VERSION "HNNBNNNYNNNNNNNNNNNNNNNNNNNNNNNNNNNNNNNNNN/4/%%%/4/'%**4NNN///"

NS_ :

BS_:

BU_: Frontradar Frontsensorik

BO_ 1801 ISO_Funktionaler_Req_09: 8 Vector__XXX
 SG_ ISO_09_Req_Data : 0|64@1+ (1,0) [0|1.84467440737096E+019] "" Vector__XXX

BO_ 1795 ISO_Funktionaler_Req_Abgas: 8 Vector__XXX
 SG_ ISO_Funktionaler_Req_Abgas : 0|64@1+ (1,0) [0|1.84467440737096E+019] "" Vector__XXX

BO_ 1792 ISO_Funktionaler_Req_All: 8 Vector__XXX
 SG_ ISO_ALL_01_Req_Data : 0|64@1+ (1,0) [0|1.84467440737096E+019] ""  Frontradar,Frontsensorik

BO_ 2015 ISO_Funktionaler_Req_OBD: 8 Vector__XXX
 SG_ ISO_OBD_Funktionaler_Req_Data : 0|64@1+ (1,0) [0|1.84467440737096E+019] "" Vector__XXX

BO_ 1871 ISO_Kamera_Req: 8 Vector__XXX
 SG_ ISO_Kamera_Req_Data : 0|64@1+ (1,0) [0|1.84467440737096E+019] ""  Frontsensorik

BO_ 1977 ISO_Kamera_Resp: 8 Frontsensorik
 SG_ ISO_Kamera_Resp_Data : 0|64@1+ (1,0) [0|1.84467440737096E+019] "" Vector__XXX

BO_ 1876 ISO_LWRAFS_Req: 8 Vector__XXX
 SG_ ISO_LWRAFS_Req_Data : 0|64@1+ (1,0) [0|1.84467440737096E+019] "" Vector__XXX

BO_ 1982 ISO_LWRAFS_Resp: 8 Vector__XXX
 SG_ ISO_LWRAFS_Resp_Data : 0|64@1+ (1,0) [0|1.84467440737096E+019] "" Vector__XXX

BO_ 1870 ISO_SWA_Req: 8 Vector__XXX
 SG_ ISO_SWA_Req_Data : 0|64@1+ (1,0) [0|1.84467440737096E+019] "" Vector__XXX

BO_ 1976 ISO_SWA_Resp: 8 Vector__XXX
 SG_ ISO_SWA_Resp_Data : 0|64@1+ (1,0) [0|1.84467440737096E+019] "" Vector__XXX

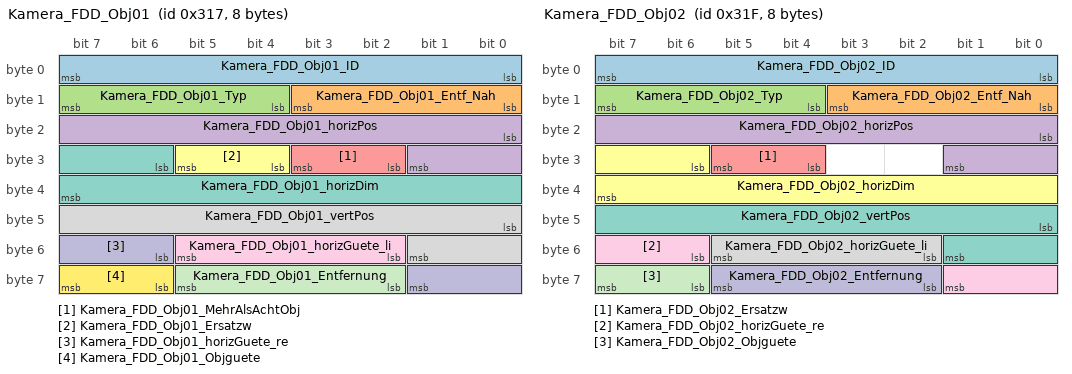
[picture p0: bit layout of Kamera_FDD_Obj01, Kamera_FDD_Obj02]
BO_ 791 Kamera_FDD_Obj01: 8 Frontsensorik
 SG_ Kamera_FDD_Obj01_ID : 0|8@1+ (1,0) [0|253] "" Vector__XXX
 SG_ Kamera_FDD_Obj01_Entf_Nah : 8|4@1+ (1,0) [0|15] "" Vector__XXX
 SG_ Kamera_FDD_Obj01_Typ : 12|4@1+ (1,0) [0|15] "" Vector__XXX
 SG_ Kamera_FDD_Obj01_horizPos : 16|10@1+ (0.05,-25.5) [-25.5|25.5] "Unit_DegreOfArc" Vector__XXX
 SG_ Kamera_FDD_Obj01_MehrAlsAchtObj : 26|2@1+ (1,0) [0|3] "" Vector__XXX
 SG_ Kamera_FDD_Obj01_Ersatzw : 28|2@1+ (1,0) [0|3] "" Vector__XXX
 SG_ Kamera_FDD_Obj01_horizDim : 30|10@1+ (0.05,0) [0|49.9] "Unit_DegreOfArc" Vector__XXX
 SG_ Kamera_FDD_Obj01_vertPos : 40|10@1+ (0.05,-12.75) [-12.75|12.75] "Unit_DegreOfArc" Vector__XXX
 SG_ Kamera_FDD_Obj01_horizGuete_li : 50|4@1+ (0.25,0) [0|3.75] "Unit_DegreOfArc" Vector__XXX
 SG_ Kamera_FDD_Obj01_horizGuete_re : 54|4@1+ (0.25,0) [0|3.75] "Unit_DegreOfArc" Vector__XXX
 SG_ Kamera_FDD_Obj01_Entfernung : 58|4@1+ (1,0) [0|15] "" Vector__XXX
 SG_ Kamera_FDD_Obj01_Objguete : 62|2@1+ (1,0) [0|3] "" Vector__XXX

BO_ 799 Kamera_FDD_Obj02: 8 Frontsensorik
 SG_ Kamera_FDD_Obj02_ID : 0|8@1+ (1,0) [0|253] "" Vector__XXX
 SG_ Kamera_FDD_Obj02_Entf_Nah : 8|4@1+ (1,0) [0|15] "" Vector__XXX
 SG_ Kamera_FDD_Obj02_Typ : 12|4@1+ (1,0) [0|15] "" Vector__XXX
 SG_ Kamera_FDD_Obj02_horizPos : 16|10@1+ (0.05,-25.5) [-25.5|25.5] "Unit_DegreOfArc" Vector__XXX
 SG_ Kamera_FDD_Obj02_Ersatzw : 28|2@1+ (1,0) [0|3] "" Vector__XXX
 SG_ Kamera_FDD_Obj02_horizDim : 30|10@1+ (0.05,0) [0|49.9] "Unit_DegreOfArc" Vector__XXX
 SG_ Kamera_FDD_Obj02_vertPos : 40|10@1+ (0.05,-12.75) [-12.75|12.75] "Unit_DegreOfArc" Vector__XXX
 SG_ Kamera_FDD_Obj02_horizGuete_li : 50|4@1+ (0.25,0) [0|3.75] "Unit_DegreOfArc" Vector__XXX
 SG_ Kamera_FDD_Obj02_horizGuete_re : 54|4@1+ (0.25,0) [0|3.75] "Unit_DegreOfArc" Vector__XXX
 SG_ Kamera_FDD_Obj02_Entfernung : 58|4@1+ (1,0) [0|15] "" Vector__XXX
 SG_ Kamera_FDD_Obj02_Objguete : 62|2@1+ (1,0) [0|3] "" Vector__XXX

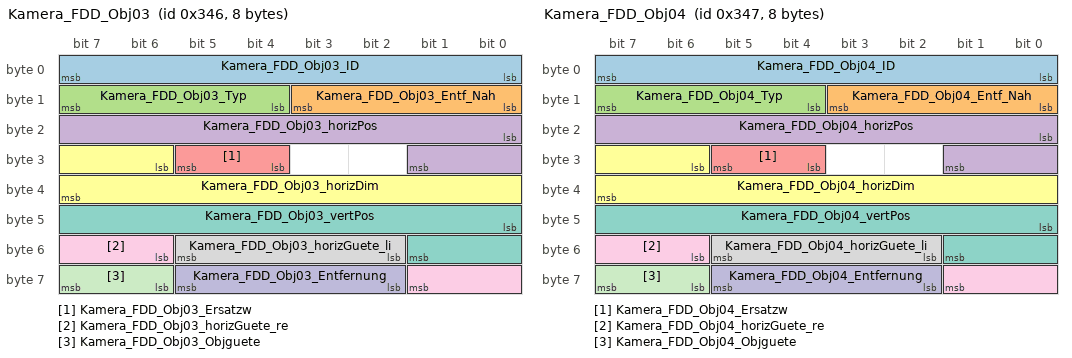
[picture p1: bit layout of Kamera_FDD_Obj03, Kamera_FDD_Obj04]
BO_ 838 Kamera_FDD_Obj03: 8 Frontsensorik
 SG_ Kamera_FDD_Obj03_ID : 0|8@1+ (1,0) [0|253] "" Vector__XXX
 SG_ Kamera_FDD_Obj03_Entf_Nah : 8|4@1+ (1,0) [0|15] "" Vector__XXX
 SG_ Kamera_FDD_Obj03_Typ : 12|4@1+ (1,0) [0|15] "" Vector__XXX
 SG_ Kamera_FDD_Obj03_horizPos : 16|10@1+ (0.05,-25.5) [-25.5|25.5] "Unit_DegreOfArc" Vector__XXX
 SG_ Kamera_FDD_Obj03_Ersatzw : 28|2@1+ (1,0) [0|3] "" Vector__XXX
 SG_ Kamera_FDD_Obj03_horizDim : 30|10@1+ (0.05,0) [0|49.9] "Unit_DegreOfArc" Vector__XXX
 SG_ Kamera_FDD_Obj03_vertPos : 40|10@1+ (0.05,-12.75) [-12.75|12.75] "Unit_DegreOfArc" Vector__XXX
 SG_ Kamera_FDD_Obj03_horizGuete_li : 50|4@1+ (0.25,0) [0|3.75] "Unit_DegreOfArc" Vector__XXX
 SG_ Kamera_FDD_Obj03_horizGuete_re : 54|4@1+ (0.25,0) [0|3.75] "Unit_DegreOfArc" Vector__XXX
 SG_ Kamera_FDD_Obj03_Entfernung : 58|4@1+ (1,0) [0|15] "" Vector__XXX
 SG_ Kamera_FDD_Obj03_Objguete : 62|2@1+ (1,0) [0|3] "" Vector__XXX

BO_ 839 Kamera_FDD_Obj04: 8 Frontsensorik
 SG_ Kamera_FDD_Obj04_ID : 0|8@1+ (1,0) [0|253] "" Vector__XXX
 SG_ Kamera_FDD_Obj04_Entf_Nah : 8|4@1+ (1,0) [0|15] "" Vector__XXX
 SG_ Kamera_FDD_Obj04_Typ : 12|4@1+ (1,0) [0|15] "" Vector__XXX
 SG_ Kamera_FDD_Obj04_horizPos : 16|10@1+ (0.05,-25.5) [-25.5|25.5] "Unit_DegreOfArc" Vector__XXX
 SG_ Kamera_FDD_Obj04_Ersatzw : 28|2@1+ (1,0) [0|3] "" Vector__XXX
 SG_ Kamera_FDD_Obj04_horizDim : 30|10@1+ (0.05,0) [0|49.9] "Unit_DegreOfArc" Vector__XXX
 SG_ Kamera_FDD_Obj04_vertPos : 40|10@1+ (0.05,-12.75) [-12.75|12.75] "Unit_DegreOfArc" Vector__XXX
 SG_ Kamera_FDD_Obj04_horizGuete_li : 50|4@1+ (0.25,0) [0|3.75] "Unit_DegreOfArc" Vector__XXX
 SG_ Kamera_FDD_Obj04_horizGuete_re : 54|4@1+ (0.25,0) [0|3.75] "Unit_DegreOfArc" Vector__XXX
 SG_ Kamera_FDD_Obj04_Entfernung : 58|4@1+ (1,0) [0|15] "" Vector__XXX
 SG_ Kamera_FDD_Obj04_Objguete : 62|2@1+ (1,0) [0|3] "" Vector__XXX

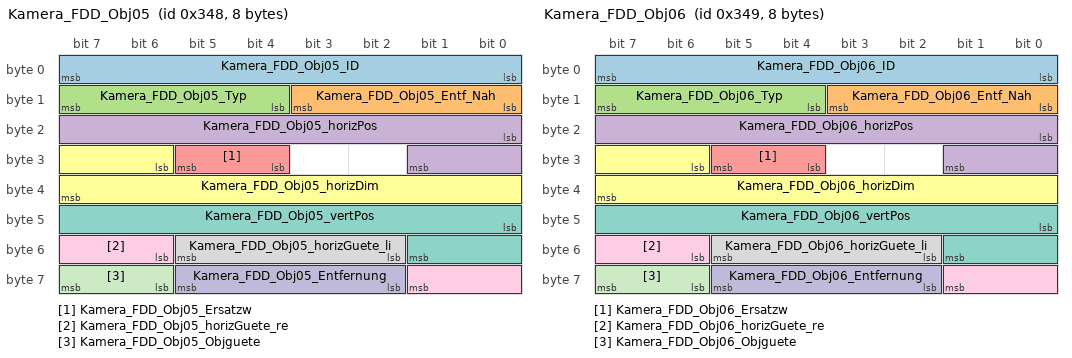
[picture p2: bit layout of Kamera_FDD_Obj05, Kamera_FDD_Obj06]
BO_ 840 Kamera_FDD_Obj05: 8 Frontsensorik
 SG_ Kamera_FDD_Obj05_ID : 0|8@1+ (1,0) [0|253] "" Vector__XXX
 SG_ Kamera_FDD_Obj05_Entf_Nah : 8|4@1+ (1,0) [0|15] "" Vector__XXX
 SG_ Kamera_FDD_Obj05_Typ : 12|4@1+ (1,0) [0|15] "" Vector__XXX
 SG_ Kamera_FDD_Obj05_horizPos : 16|10@1+ (0.05,-25.5) [-25.5|25.5] "Unit_DegreOfArc" Vector__XXX
 SG_ Kamera_FDD_Obj05_Ersatzw : 28|2@1+ (1,0) [0|3] "" Vector__XXX
 SG_ Kamera_FDD_Obj05_horizDim : 30|10@1+ (0.05,0) [0|49.9] "Unit_DegreOfArc" Vector__XXX
 SG_ Kamera_FDD_Obj05_vertPos : 40|10@1+ (0.05,-12.75) [-12.75|12.75] "Unit_DegreOfArc" Vector__XXX
 SG_ Kamera_FDD_Obj05_horizGuete_li : 50|4@1+ (0.25,0) [0|3.75] "Unit_DegreOfArc" Vector__XXX
 SG_ Kamera_FDD_Obj05_horizGuete_re : 54|4@1+ (0.25,0) [0|3.75] "Unit_DegreOfArc" Vector__XXX
 SG_ Kamera_FDD_Obj05_Entfernung : 58|4@1+ (1,0) [0|15] "" Vector__XXX
 SG_ Kamera_FDD_Obj05_Objguete : 62|2@1+ (1,0) [0|3] "" Vector__XXX

BO_ 841 Kamera_FDD_Obj06: 8 Frontsensorik
 SG_ Kamera_FDD_Obj06_ID : 0|8@1+ (1,0) [0|253] "" Vector__XXX
 SG_ Kamera_FDD_Obj06_Entf_Nah : 8|4@1+ (1,0) [0|15] "" Vector__XXX
 SG_ Kamera_FDD_Obj06_Typ : 12|4@1+ (1,0) [0|15] "" Vector__XXX
 SG_ Kamera_FDD_Obj06_horizPos : 16|10@1+ (0.05,-25.5) [-25.5|25.5] "Unit_DegreOfArc" Vector__XXX
 SG_ Kamera_FDD_Obj06_Ersatzw : 28|2@1+ (1,0) [0|3] "" Vector__XXX
 SG_ Kamera_FDD_Obj06_horizDim : 30|10@1+ (0.05,0) [0|49.9] "Unit_DegreOfArc" Vector__XXX
 SG_ Kamera_FDD_Obj06_vertPos : 40|10@1+ (0.05,-12.75) [-12.75|12.75] "Unit_DegreOfArc" Vector__XXX
 SG_ Kamera_FDD_Obj06_horizGuete_li : 50|4@1+ (0.25,0) [0|3.75] "Unit_DegreOfArc" Vector__XXX
 SG_ Kamera_FDD_Obj06_horizGuete_re : 54|4@1+ (0.25,0) [0|3.75] "Unit_DegreOfArc" Vector__XXX
 SG_ Kamera_FDD_Obj06_Entfernung : 58|4@1+ (1,0) [0|15] "" Vector__XXX
 SG_ Kamera_FDD_Obj06_Objguete : 62|2@1+ (1,0) [0|3] "" Vector__XXX

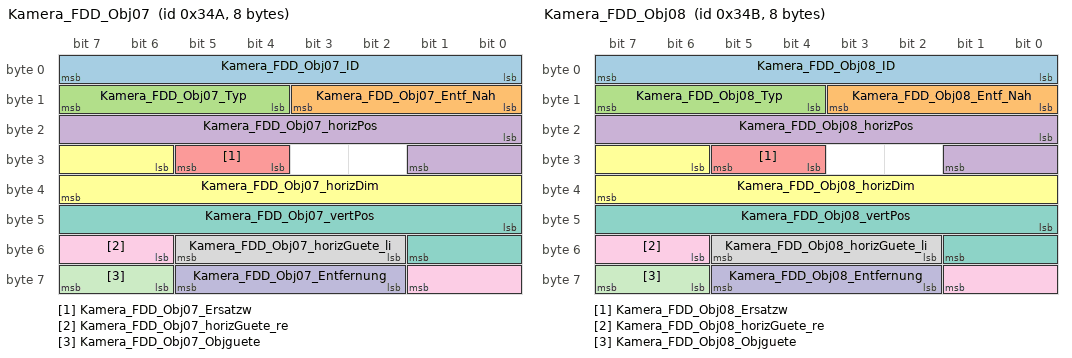
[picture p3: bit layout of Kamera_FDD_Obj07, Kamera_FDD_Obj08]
BO_ 842 Kamera_FDD_Obj07: 8 Frontsensorik
 SG_ Kamera_FDD_Obj07_ID : 0|8@1+ (1,0) [0|253] "" Vector__XXX
 SG_ Kamera_FDD_Obj07_Entf_Nah : 8|4@1+ (1,0) [0|15] "" Vector__XXX
 SG_ Kamera_FDD_Obj07_Typ : 12|4@1+ (1,0) [0|15] "" Vector__XXX
 SG_ Kamera_FDD_Obj07_horizPos : 16|10@1+ (0.05,-25.5) [-25.5|25.5] "Unit_DegreOfArc" Vector__XXX
 SG_ Kamera_FDD_Obj07_Ersatzw : 28|2@1+ (1,0) [0|3] "" Vector__XXX
 SG_ Kamera_FDD_Obj07_horizDim : 30|10@1+ (0.05,0) [0|49.9] "Unit_DegreOfArc" Vector__XXX
 SG_ Kamera_FDD_Obj07_vertPos : 40|10@1+ (0.05,-12.75) [-12.75|12.75] "Unit_DegreOfArc" Vector__XXX
 SG_ Kamera_FDD_Obj07_horizGuete_li : 50|4@1+ (0.25,0) [0|3.75] "Unit_DegreOfArc" Vector__XXX
 SG_ Kamera_FDD_Obj07_horizGuete_re : 54|4@1+ (0.25,0) [0|3.75] "Unit_DegreOfArc" Vector__XXX
 SG_ Kamera_FDD_Obj07_Entfernung : 58|4@1+ (1,0) [0|15] "" Vector__XXX
 SG_ Kamera_FDD_Obj07_Objguete : 62|2@1+ (1,0) [0|3] "" Vector__XXX

BO_ 843 Kamera_FDD_Obj08: 8 Frontsensorik
 SG_ Kamera_FDD_Obj08_ID : 0|8@1+ (1,0) [0|253] "" Vector__XXX
 SG_ Kamera_FDD_Obj08_Entf_Nah : 8|4@1+ (1,0) [0|15] "" Vector__XXX
 SG_ Kamera_FDD_Obj08_Typ : 12|4@1+ (1,0) [0|15] "" Vector__XXX
 SG_ Kamera_FDD_Obj08_horizPos : 16|10@1+ (0.05,-25.5) [-25.5|25.5] "Unit_DegreOfArc" Vector__XXX
 SG_ Kamera_FDD_Obj08_Ersatzw : 28|2@1+ (1,0) [0|3] "" Vector__XXX
 SG_ Kamera_FDD_Obj08_horizDim : 30|10@1+ (0.05,0) [0|49.9] "Unit_DegreOfArc" Vector__XXX
 SG_ Kamera_FDD_Obj08_vertPos : 40|10@1+ (0.05,-12.75) [-12.75|12.75] "Unit_DegreOfArc" Vector__XXX
 SG_ Kamera_FDD_Obj08_horizGuete_li : 50|4@1+ (0.25,0) [0|3.75] "Unit_DegreOfArc" Vector__XXX
 SG_ Kamera_FDD_Obj08_horizGuete_re : 54|4@1+ (0.25,0) [0|3.75] "Unit_DegreOfArc" Vector__XXX
 SG_ Kamera_FDD_Obj08_Entfernung : 58|4@1+ (1,0) [0|15] "" Vector__XXX
 SG_ Kamera_FDD_Obj08_Objguete : 62|2@1+ (1,0) [0|3] "" Vector__XXX

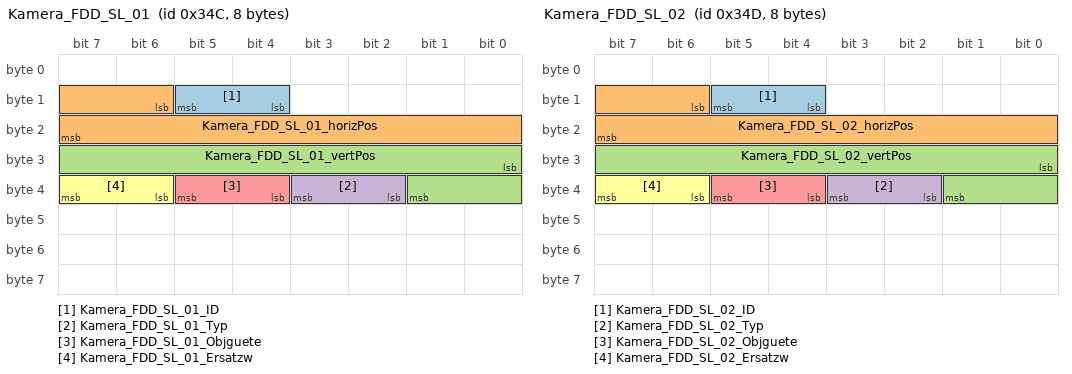
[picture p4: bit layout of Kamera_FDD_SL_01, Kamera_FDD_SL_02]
BO_ 844 Kamera_FDD_SL_01: 8 Frontsensorik
 SG_ Kamera_FDD_SL_01_ID : 12|2@1+ (1,0) [0|3] "" Vector__XXX
 SG_ Kamera_FDD_SL_01_horizPos : 14|10@1+ (0.05,-25.5) [-25.5|25.5] "Unit_DegreOfArc" Vector__XXX
 SG_ Kamera_FDD_SL_01_vertPos : 24|10@1+ (0.05,-12.75) [-12.75|12.75] "Unit_DegreOfArc" Vector__XXX
 SG_ Kamera_FDD_SL_01_Typ : 34|2@1+ (1,0) [0|3] "" Vector__XXX
 SG_ Kamera_FDD_SL_01_Objguete : 36|2@1+ (1,0) [0|3] "" Vector__XXX
 SG_ Kamera_FDD_SL_01_Ersatzw : 38|2@1+ (1,0) [0|3] "" Vector__XXX

BO_ 845 Kamera_FDD_SL_02: 8 Frontsensorik
 SG_ Kamera_FDD_SL_02_ID : 12|2@1+ (1,0) [0|3] "" Vector__XXX
 SG_ Kamera_FDD_SL_02_horizPos : 14|10@1+ (0.05,-25.5) [-25.5|25.5] "Unit_DegreOfArc" Vector__XXX
 SG_ Kamera_FDD_SL_02_vertPos : 24|10@1+ (0.05,-12.75) [-12.75|12.75] "Unit_DegreOfArc" Vector__XXX
 SG_ Kamera_FDD_SL_02_Typ : 34|2@1+ (1,0) [0|3] "" Vector__XXX
 SG_ Kamera_FDD_SL_02_Objguete : 36|2@1+ (1,0) [0|3] "" Vector__XXX
 SG_ Kamera_FDD_SL_02_Ersatzw : 38|2@1+ (1,0) [0|3] "" Vector__XXX

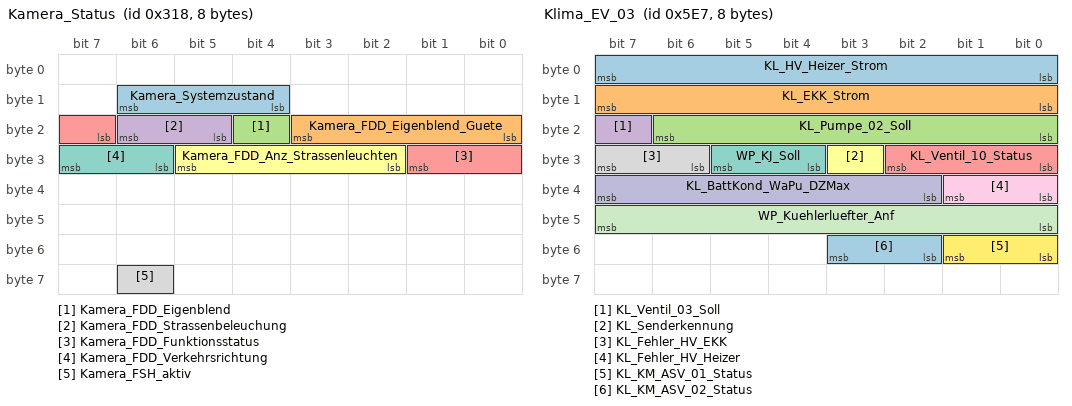
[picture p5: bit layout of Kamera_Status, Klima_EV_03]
BO_ 792 Kamera_Status: 8 Frontsensorik
 SG_ Kamera_Systemzustand : 12|3@1+ (1,0) [0|7] ""  Frontradar
 SG_ Kamera_FDD_Eigenblend_Guete : 16|4@1+ (10,0) [0|100] "Unit_PerCent" Vector__XXX
 SG_ Kamera_FDD_Eigenblend : 20|1@1+ (1,0) [0|1] "" Vector__XXX
 SG_ Kamera_FDD_Strassenbeleuchung : 21|2@1+ (1,0) [0|3] "" Vector__XXX
 SG_ Kamera_FDD_Funktionsstatus : 23|3@1+ (1,0) [0|7] "" Vector__XXX
 SG_ Kamera_FDD_Anz_Strassenleuchten : 26|4@1+ (1,0) [0|14] "" Vector__XXX
 SG_ Kamera_FDD_Verkehrsrichtung : 30|2@1+ (1,0) [0|3] "" Vector__XXX
 SG_ Kamera_FSH_aktiv : 62|1@1+ (1,0) [0|1] "" Vector__XXX

BO_ 960 Klemmen_Status_01: 4 Vector__XXX
 SG_ Klemmen_Status_01_CRC : 0|8@1+ (1,0) [0|255] "" Vector__XXX
 SG_ Klemmen_Status_01_BZ : 8|4@1+ (1,0) [0|15] "" Vector__XXX
 SG_ RSt_Fahrerhinweise : 12|4@1+ (1,0) [0|15] "" Vector__XXX
 SG_ ZAS_Kl_S : 16|1@1+ (1,0) [0|1] "" Vector__XXX
 SG_ ZAS_Kl_15 : 17|1@1+ (1,0) [0|1] ""  Frontradar
 SG_ ZAS_Kl_X : 18|1@1+ (1,0) [0|1] "" Vector__XXX
 SG_ ZAS_Kl_50_Startanforderung : 19|1@1+ (1,0) [0|1] "" Vector__XXX
 SG_ BCM_Remotestart_Betrieb : 20|1@1+ (1,0) [0|1] "" Vector__XXX
 SG_ ZAS_Kl_Infotainment : 21|1@1+ (1,0) [0|1] "" Vector__XXX
 SG_ BCM_Remotestart_KL15_Anf : 22|1@1+ (1,0) [0|1] "" Vector__XXX
 SG_ BCM_Remotestart_MO_Start : 23|1@1+ (1,0) [0|1] "" Vector__XXX
 SG_ KST_Warn_P1_ZST_def : 24|1@1+ (1,0) [0|1] "" Vector__XXX
 SG_ KST_Warn_P2_ZST_def : 25|1@1+ (1,0) [0|1] "" Vector__XXX
 SG_ KST_Fahrerhinweis_1 : 26|1@1+ (1,0) [0|1] "" Vector__XXX
 SG_ KST_Fahrerhinweis_2 : 27|1@1+ (1,0) [0|1] "" Vector__XXX
 SG_ KST_Fahrerhinweis_3 : 28|1@1+ (1,0) [0|1] "" Vector__XXX
 SG_ KST_Fahrerhinweis_4 : 29|1@1+ (1,0) [0|1] "" Vector__XXX
 SG_ KST_Fahrerhinweis_5 : 30|1@1+ (1,0) [0|1] "" Vector__XXX
 SG_ KST_Fahrerhinweis_6 : 31|1@1+ (1,0) [0|1] "" Vector__XXX

BO_ 1646 Klima_03: 8 Vector__XXX
 SG_ KL_STL_aktiv : 0|1@1+ (1,0) [0|1] "" Vector__XXX
 SG_ KL_STH_aktiv : 1|1@1+ (1,0) [0|1] "" Vector__XXX
 SG_ KL_Solarluefter_aktiv : 2|1@1+ (1,0) [0|1] "" Vector__XXX
 SG_ KL_Umluft_Taste : 3|1@1+ (1,0) [0|1] "" Vector__XXX
 SG_ KL_Geblaese_Fond_Status : 4|4@1+ (1,0) [0|15] "" Vector__XXX
 SG_ KL_STH_Ansteuerung : 8|2@1+ (1,0) [0|3] "" Vector__XXX
 SG_ KL_STH_Betriebsdauer : 10|6@1+ (1,0) [0|60] "Unit_Minut" Vector__XXX
 SG_ KL_Magnetventil : 16|1@1+ (1,0) [0|1] "" Vector__XXX
 SG_ KL_WaPu : 17|1@1+ (1,0) [0|1] "" Vector__XXX
 SG_ KL_Geblaese_Status : 18|4@1+ (1,0) [0|15] "" Vector__XXX
 SG_ KL_Restwaerme_aktiv : 22|1@1+ (1,0) [0|1] "" Vector__XXX
 SG_ KL_Kompressorkupplung : 23|1@1+ (1,0) [0|1] "" Vector__XXX
 SG_ KL_BCmE_Livetip_Freigabe : 24|1@1+ (1,0) [0|1] "" Vector__XXX
 SG_ KL_SH_Soll_hl : 25|3@1+ (1,0) [0|7] "" Vector__XXX
 SG_ KL_SH_Soll_hr : 28|3@1+ (1,0) [0|7] "" Vector__XXX
 SG_ KL_Innen_Temp : 32|8@1+ (0.5,-50) [-50|76] "Unit_DegreCelsi" Vector__XXX
 SG_ KL_I_Geblaese_Fond : 40|8@1+ (0.25,0) [0|63.5] "Unit_Amper" Vector__XXX
 SG_ KL_Heizkreisventilstellung : 49|2@1+ (1,0) [0|3] "" Vector__XXX
 SG_ KL_FSH_Automatikbetrieb : 51|1@1+ (1,0) [0|1] "" Vector__XXX
 SG_ KL_SIH_LEH_Verteilung_VL : 52|3@1+ (1,0) [0|7] "" Vector__XXX
 SG_ KL_SIH_LEL_Verteilung_VL : 55|3@1+ (1,0) [0|7] "" Vector__XXX
 SG_ KL_SIH_LEH_Verteilung_VR : 58|3@1+ (1,0) [0|7] "" Vector__XXX
 SG_ KL_SIH_LEL_Verteilung_VR : 61|3@1+ (1,0) [0|7] "" Vector__XXX

BO_ 949 Klima_11: 8 Vector__XXX
 SG_ KL_Drehz_Anh : 0|1@1+ (1,0) [0|1] "" Vector__XXX
 SG_ KL_Vorwarn_Komp_ein : 1|1@1+ (1,0) [0|1] "" Vector__XXX
 SG_ KL_AC_Schalter : 2|1@1+ (1,0) [0|1] "" Vector__XXX
 SG_ KL_Komp_Moment_alt : 3|1@1+ (1,0) [0|1] "" Vector__XXX
 SG_ KL_Vorwarn_Zuheizer_ein : 6|1@1+ (1,0) [0|1] "" Vector__XXX
 SG_ KL_Zustand : 7|1@1+ (1,0) [0|1] "" Vector__XXX
 SG_ KL_Kompressorkupplung_linear : 8|8@1+ (20,0) [0|4000] "Unit_MilliAmper" Vector__XXX
 SG_ KL_Charisma_FahrPr : 16|4@1+ (1,0) [0|15] "" Vector__XXX
 SG_ KL_Charisma_Status : 20|2@1+ (1,0) [0|3] "" Vector__XXX
 SG_ KL_nachtr_Stopp_Anf : 22|1@1+ (1,0) [0|1] "" Vector__XXX
 SG_ KL_T_Charge : 23|1@1+ (1,0) [0|1] "" Vector__XXX
 SG_ KL_Last_Kompr : 24|8@1+ (0.25,0) [0|63.5] "Unit_NewtoMeter" Vector__XXX
 SG_ KL_Spannungs_Anf : 32|2@1+ (1,0) [0|3] "" Vector__XXX
 SG_ KL_Thermomanagement : 34|2@1+ (1,0) [0|3] "" Vector__XXX
 SG_ KL_StartStopp_Info : 36|2@1+ (1,0) [0|3] "" Vector__XXX
 SG_ KL_Freilauf_Info : 38|2@1+ (1,0) [0|3] "" Vector__XXX
 SG_ KL_Anf_KL : 40|8@1+ (0.4,0) [0|101.6] "Unit_PerCent" Vector__XXX
 SG_ KL_el_Zuheizer_Stufe : 48|3@1+ (1,0) [0|7] "" Vector__XXX
 SG_ KL_Ausstattung_Klima : 51|3@1+ (1,0) [0|7] "" Vector__XXX
 SG_ KL_Variante_Standheizung : 54|2@1+ (1,0) [0|3] "" Vector__XXX

BO_ 1511 Klima_EV_03: 8 Vector__XXX
 SG_ KL_HV_Heizer_Strom : 0|8@1+ (0.25,0) [0|63.5] "Unit_Amper" Vector__XXX
 SG_ KL_EKK_Strom : 8|8@1+ (0.25,0) [0|63.5] "Unit_Amper" Vector__XXX
 SG_ KL_Pumpe_02_Soll : 16|7@1+ (1,0) [0|100] "Unit_PerCent" Vector__XXX
 SG_ KL_Ventil_03_Soll : 23|1@1+ (1,0) [0|1] "" Vector__XXX
 SG_ KL_Ventil_10_Status : 24|3@1+ (1,0) [0|7] "" Vector__XXX
 SG_ KL_Senderkennung : 27|1@1+ (1,0) [0|1] "" Vector__XXX
 SG_ WP_KJ_Soll : 28|2@1+ (1,0) [0|3] "" Vector__XXX
 SG_ KL_Fehler_HV_EKK : 30|2@1+ (1,0) [0|3] "" Vector__XXX
 SG_ KL_Fehler_HV_Heizer : 32|2@1+ (1,0) [0|3] "" Vector__XXX
 SG_ KL_BattKond_WaPu_DZMax : 34|6@1+ (2,0) [0|100] "Unit_PerCent" Vector__XXX
 SG_ WP_Kuehlerluefter_Anf : 40|8@1+ (0.4,0) [0|101.6] "Unit_PerCent" Vector__XXX
 SG_ KL_KM_ASV_01_Status : 48|2@1+ (1,0) [0|3] "" Vector__XXX
 SG_ KL_KM_ASV_02_Status : 50|2@1+ (1,0) [0|3] "" Vector__XXX

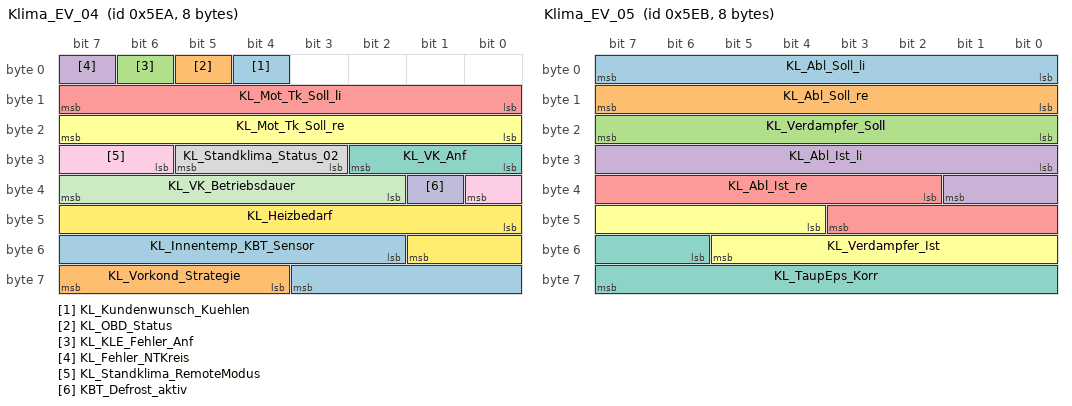
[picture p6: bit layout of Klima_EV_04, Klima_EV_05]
BO_ 1514 Klima_EV_04: 8 Vector__XXX
 SG_ KL_Kundenwunsch_Kuehlen : 4|1@1+ (1,0) [0|1] "" Vector__XXX
 SG_ KL_OBD_Status : 5|1@1+ (1,0) [0|1] "" Vector__XXX
 SG_ KL_KLE_Fehler_Anf : 6|1@1+ (1,0) [0|1] "" Vector__XXX
 SG_ KL_Fehler_NTKreis : 7|1@1+ (1,0) [0|1] "" Vector__XXX
 SG_ KL_Mot_Tk_Soll_li : 8|8@1+ (0.5,0) [0|100] "Unit_PerCent" Vector__XXX
 SG_ KL_Mot_Tk_Soll_re : 16|8@1+ (0.5,0) [0|100] "Unit_PerCent" Vector__XXX
 SG_ KL_VK_Anf : 24|3@1+ (1,0) [0|7] "" Vector__XXX
 SG_ KL_Standklima_Status_02 : 27|3@1+ (1,0) [0|7] "" Vector__XXX
 SG_ KL_Standklima_RemoteModus : 30|3@1+ (1,0) [0|7] "" Vector__XXX
 SG_ KBT_Defrost_aktiv : 33|1@1+ (1,0) [0|1] "" Vector__XXX
 SG_ KL_VK_Betriebsdauer : 34|6@1+ (1,0) [0|60] "Unit_Minut" Vector__XXX
 SG_ KL_Heizbedarf : 40|10@1+ (0.1,0) [0.1|90] "Unit_DegreCelsi" Vector__XXX
 SG_ KL_Innentemp_KBT_Sensor : 50|10@1+ (0.1,-40) [-40|62] "Unit_DegreCelsi" Vector__XXX
 SG_ KL_Vorkond_Strategie : 60|4@1+ (1,0) [0|15] "" Vector__XXX

BO_ 1515 Klima_EV_05: 8 Vector__XXX
 SG_ KL_Abl_Soll_li : 0|8@1+ (0.5,0) [0|86] "Unit_DegreCelsi" Vector__XXX
 SG_ KL_Abl_Soll_re : 8|8@1+ (0.5,0) [0|86] "Unit_DegreCelsi" Vector__XXX
 SG_ KL_Verdampfer_Soll : 16|8@1+ (0.5,-40) [-40|86.5] "Unit_DegreCelsi" Vector__XXX
 SG_ KL_Abl_Ist_li : 24|10@1+ (0.1,-20) [-20|82] "Unit_DegreCelsi" Vector__XXX
 SG_ KL_Abl_Ist_re : 34|10@1+ (0.1,-20) [-20|82] "Unit_DegreCelsi" Vector__XXX
 SG_ KL_Verdampfer_Ist : 44|10@1+ (0.1,-40) [-40|62] "Unit_DegreCelsi" Vector__XXX
 SG_ KL_TaupEps_Korr : 54|10@1+ (0.1,-50) [-50|52] "Unit_DegreCelsi" Vector__XXX

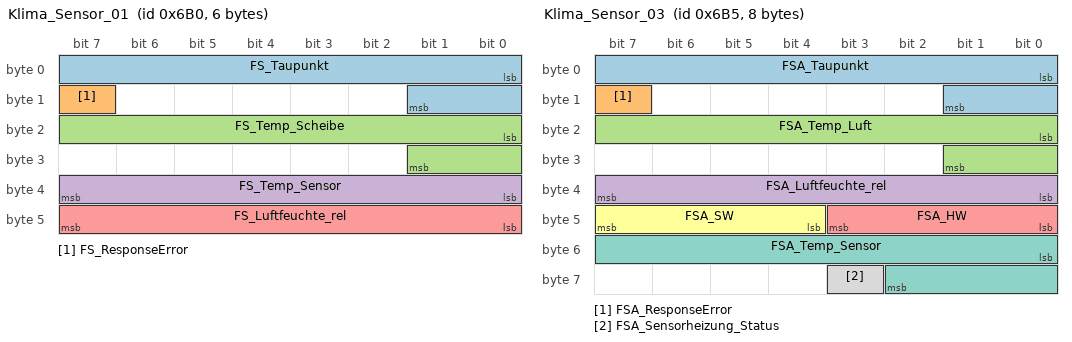
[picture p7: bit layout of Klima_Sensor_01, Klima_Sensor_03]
BO_ 1712 Klima_Sensor_01: 6 Vector__XXX
 SG_ FS_Taupunkt : 0|10@1+ (0.1,-39.6) [-39.5|60.4] "Unit_DegreCelsi" Vector__XXX
 SG_ FS_ResponseError : 15|1@1+ (1,0) [0|1] "" Vector__XXX
 SG_ FS_Temp_Scheibe : 16|10@1+ (0.1,-39.6) [-39.5|60.4] "Unit_DegreCelsi" Vector__XXX
 SG_ FS_Temp_Sensor : 32|8@1+ (0.5,-40) [-39.5|87] "Unit_DegreCelsi" Vector__XXX
 SG_ FS_Luftfeuchte_rel : 40|8@1+ (0.5,-0.5) [0|100] "Unit_PerCent" Vector__XXX

BO_ 1717 Klima_Sensor_03: 8 Vector__XXX
 SG_ FSA_Taupunkt : 0|10@1+ (0.1,-40) [-40|60] "Unit_DegreCelsi" Vector__XXX
 SG_ FSA_ResponseError : 15|1@1+ (1,0) [0|1] "" Vector__XXX
 SG_ FSA_Temp_Luft : 16|10@1+ (0.1,-40) [-40|61] "Unit_DegreCelsi" Vector__XXX
 SG_ FSA_Luftfeuchte_rel : 32|8@1+ (0.5,0) [0|100] "Unit_PerCent" Vector__XXX
 SG_ FSA_HW : 40|4@1+ (1,0) [0|15] "" Vector__XXX
 SG_ FSA_SW : 44|4@1+ (1,0) [0|15] "" Vector__XXX
 SG_ FSA_Temp_Sensor : 48|11@1+ (0.1,-40) [-40|90] "Unit_DegreCelsi" Vector__XXX
 SG_ FSA_Sensorheizung_Status : 59|1@1+ (1,0) [0|1] "" Vector__XXX

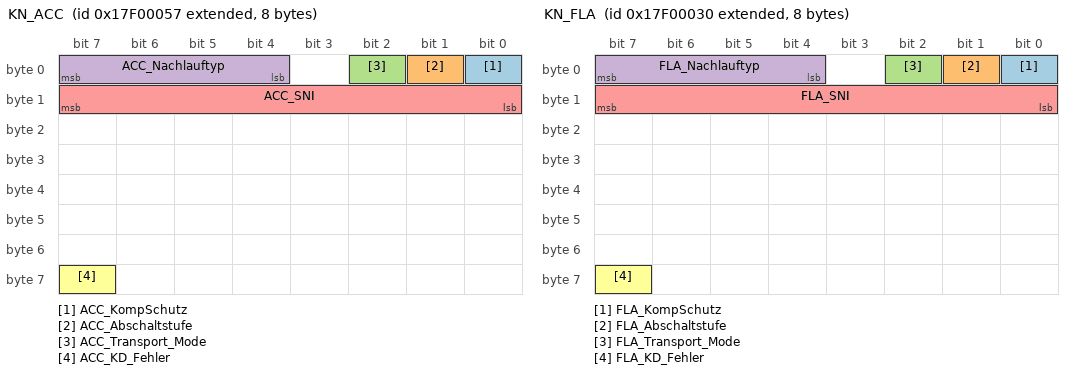
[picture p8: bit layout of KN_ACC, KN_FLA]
BO_ 2549088343 KN_ACC: 8 Frontradar
 SG_ ACC_KompSchutz : 0|1@1+ (1,0) [0|1] "" Vector__XXX
 SG_ ACC_Abschaltstufe : 1|1@1+ (1,0) [0|1] "" Vector__XXX
 SG_ ACC_Transport_Mode : 2|1@1+ (1,0) [0|1] "" Vector__XXX
 SG_ ACC_Nachlauftyp : 4|4@1+ (1,0) [0|15] "" Vector__XXX
 SG_ ACC_SNI : 8|8@1+ (1,0) [0|255] "" Vector__XXX
 SG_ ACC_KD_Fehler : 63|1@1+ (1,0) [0|1] "" Vector__XXX

BO_ 2549088304 KN_FLA: 8 Vector__XXX
 SG_ FLA_KompSchutz : 0|1@1+ (1,0) [0|1] "" Vector__XXX
 SG_ FLA_Abschaltstufe : 1|1@1+ (1,0) [0|1] "" Vector__XXX
 SG_ FLA_Transport_Mode : 2|1@1+ (1,0) [0|1] "" Vector__XXX
 SG_ FLA_Nachlauftyp : 4|4@1+ (1,0) [0|15] "" Vector__XXX
 SG_ FLA_SNI : 8|8@1+ (1,0) [0|255] "" Vector__XXX
 SG_ FLA_KD_Fehler : 63|1@1+ (1,0) [0|1] "" Vector__XXX

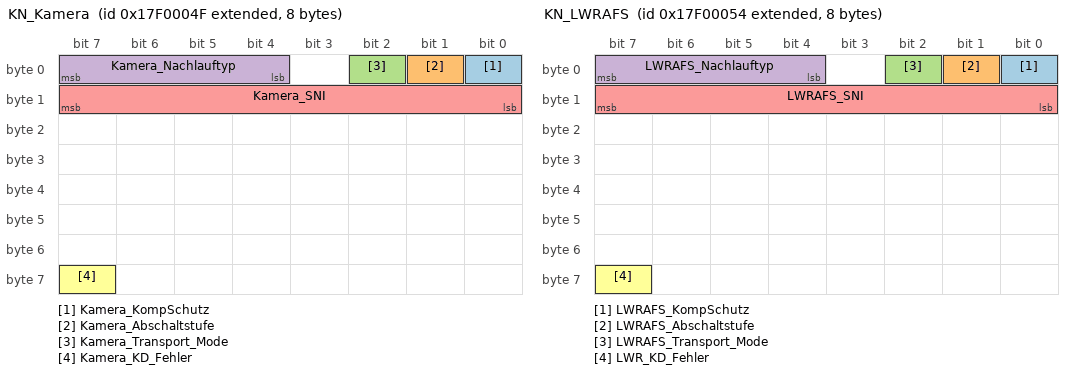
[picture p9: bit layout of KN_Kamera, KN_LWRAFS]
BO_ 2549088335 KN_Kamera: 8 Frontsensorik
 SG_ Kamera_KompSchutz : 0|1@1+ (1,0) [0|1] "" Vector__XXX
 SG_ Kamera_Abschaltstufe : 1|1@1+ (1,0) [0|1] "" Vector__XXX
 SG_ Kamera_Transport_Mode : 2|1@1+ (1,0) [0|1] "" Vector__XXX
 SG_ Kamera_Nachlauftyp : 4|4@1+ (1,0) [0|15] "" Vector__XXX
 SG_ Kamera_SNI : 8|8@1+ (1,0) [0|255] "" Vector__XXX
 SG_ Kamera_KD_Fehler : 63|1@1+ (1,0) [0|1] "" Vector__XXX

BO_ 2549088340 KN_LWRAFS: 8 Vector__XXX
 SG_ LWRAFS_KompSchutz : 0|1@1+ (1,0) [0|1] "" Vector__XXX
 SG_ LWRAFS_Abschaltstufe : 1|1@1+ (1,0) [0|1] "" Vector__XXX
 SG_ LWRAFS_Transport_Mode : 2|1@1+ (1,0) [0|1] "" Vector__XXX
 SG_ LWRAFS_Nachlauftyp : 4|4@1+ (1,0) [0|15] "" Vector__XXX
 SG_ LWRAFS_SNI : 8|8@1+ (1,0) [0|255] "" Vector__XXX
 SG_ LWR_KD_Fehler : 63|1@1+ (1,0) [0|1] "" Vector__XXX

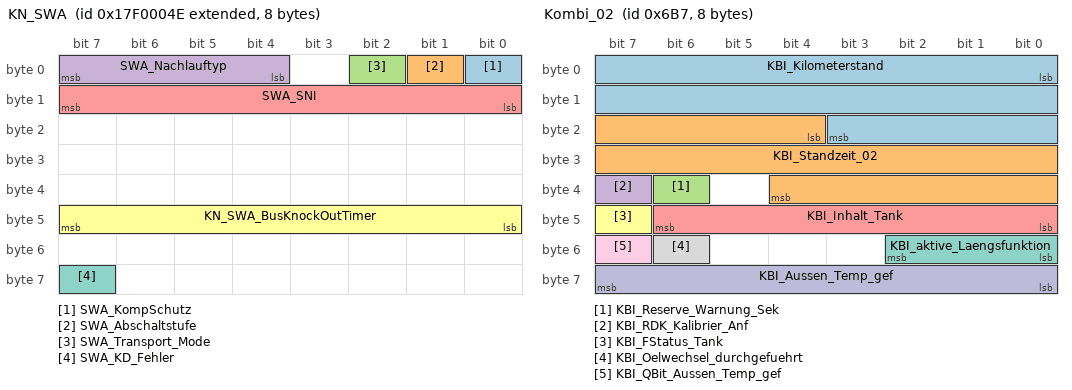
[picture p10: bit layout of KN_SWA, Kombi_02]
BO_ 2549088334 KN_SWA: 8 Vector__XXX
 SG_ SWA_KompSchutz : 0|1@1+ (1,0) [0|1] "" Vector__XXX
 SG_ SWA_Abschaltstufe : 1|1@1+ (1,0) [0|1] "" Vector__XXX
 SG_ SWA_Transport_Mode : 2|1@1+ (1,0) [0|1] "" Vector__XXX
 SG_ SWA_Nachlauftyp : 4|4@1+ (1,0) [0|15] "" Vector__XXX
 SG_ SWA_SNI : 8|8@1+ (1,0) [0|255] "" Vector__XXX
 SG_ KN_SWA_BusKnockOutTimer : 40|8@1+ (1,0) [0|254] "" Vector__XXX
 SG_ SWA_KD_Fehler : 63|1@1+ (1,0) [0|1] "" Vector__XXX

BO_ 779 Kombi_01: 8 Vector__XXX
 SG_ KBI_ABS_Lampe : 0|1@1+ (1,0) [0|1] "" Vector__XXX
 SG_ KBI_ESP_Lampe : 1|1@1+ (1,0) [0|1] "" Vector__XXX
 SG_ KBI_BKL_Lampe : 2|1@1+ (1,0) [0|1] "" Vector__XXX
 SG_ KBI_Airbag_Lampe : 3|1@1+ (1,0) [0|1] "" Vector__XXX
 SG_ KBI_SILA_gueltig : 4|1@1+ (1,0) [0|1] "" Vector__XXX
 SG_ KBI_Lenkung_Lampe : 5|1@1+ (1,0) [0|1] "" Vector__XXX
 SG_ KBI_Vorglueh_System_Lampe : 6|1@1+ (1,0) [0|1] "" Vector__XXX
 SG_ KBI_NV_in_Anzeige : 7|1@1+ (1,0) [0|1] "" Vector__XXX
 SG_ Kombi_01_BZ : 8|4@1+ (1,0) [0|15] ""  Frontradar
 SG_ KBI_Anzeigestatus_ACC : 12|1@1+ (1,0) [0|1] ""  Frontradar
 SG_ KBI_Anzeigestatus_GRA : 13|2@1+ (1,0) [0|3] "" Vector__XXX
 SG_ KBI_Oeldruck_Schalter : 15|1@1+ (1,0) [0|1] "" Vector__XXX
 SG_ KBI_Tankwarnung : 16|1@1+ (1,0) [0|1] "" Vector__XXX
 SG_ KBI_MFA_v_Einheit_01 : 17|1@1+ (1,0) [0|1] ""  Frontradar,Frontsensorik
 SG_ KBI_im_Stellgliedtest : 18|1@1+ (1,0) [0|1] "" Vector__XXX
 SG_ KBI_Anzeigefehler_LDW : 19|2@1+ (1,0) [0|3] "" Vector__XXX
 SG_ KBI_Oeldruckwarnung : 22|1@1+ (1,0) [0|1] "" Vector__XXX
 SG_ KBI_Handbremse : 23|1@1+ (1,0) [0|1] ""  Frontradar
 SG_ KBI_V_Digital : 24|9@1+ (1,0) [0|511] "" Vector__XXX
 SG_ KBI_PLA_in_Anzeige : 33|1@1+ (1,0) [0|1] "" Vector__XXX
 SG_ KBI_Anzeigefehler_NV : 34|1@1+ (1,0) [0|1] "" Vector__XXX
 SG_ KBI_Anzeigestatus_LIM : 35|2@1+ (1,0) [0|3] "" Vector__XXX
 SG_ KBI_ARA_in_Anzeige : 37|1@1+ (1,0) [0|1] "" Vector__XXX
 SG_ KBI_angez_Geschw : 48|10@1+ (0.32,0) [0|325.12] "Unit_KiloMeterPerHour"  Frontradar,Frontsensorik
 SG_ KBI_Einheit_Tacho : 58|1@1+ (1,0) [0|1] ""  Frontradar,Frontsensorik
 SG_ KBI_Konsistenz_ACC : 59|1@1+ (1,0) [0|1] ""  Frontradar
 SG_ KBI_Fehler_Anzeige_ACC : 60|1@1+ (1,0) [0|1] ""  Frontradar
 SG_ KBI_Anzeigefehler_SWA : 61|2@1+ (1,0) [0|3] "" Vector__XXX

BO_ 1719 Kombi_02: 8 Vector__XXX
 SG_ KBI_Kilometerstand : 0|20@1+ (1,0) [0|1048573] "Unit_KiloMeter" Vector__XXX
 SG_ KBI_Standzeit_02 : 20|17@1+ (1,0) [0|131068] "Unit_Secon" Vector__XXX
 SG_ KBI_Reserve_Warnung_Sek : 38|1@1+ (1,0) [0|1] "" Vector__XXX
 SG_ KBI_RDK_Kalibrier_Anf : 39|1@1+ (1,0) [0|1] "" Vector__XXX
 SG_ KBI_Inhalt_Tank : 40|7@1+ (1,0) [0|125] "Unit_Liter" Vector__XXX
 SG_ KBI_FStatus_Tank : 47|1@1+ (1,0) [0|1] "" Vector__XXX
 SG_ KBI_aktive_Laengsfunktion : 48|3@1+ (1,0) [0|7] "" Vector__XXX
 SG_ KBI_Oelwechsel_durchgefuehrt : 54|1@1+ (1,0) [0|1] "" Vector__XXX
 SG_ KBI_QBit_Aussen_Temp_gef : 55|1@1+ (1,0) [0|1] ""  Frontsensorik
 SG_ KBI_Aussen_Temp_gef : 56|8@1+ (0.5,-50) [-50|75] "Unit_DegreCelsi"  Frontsensorik

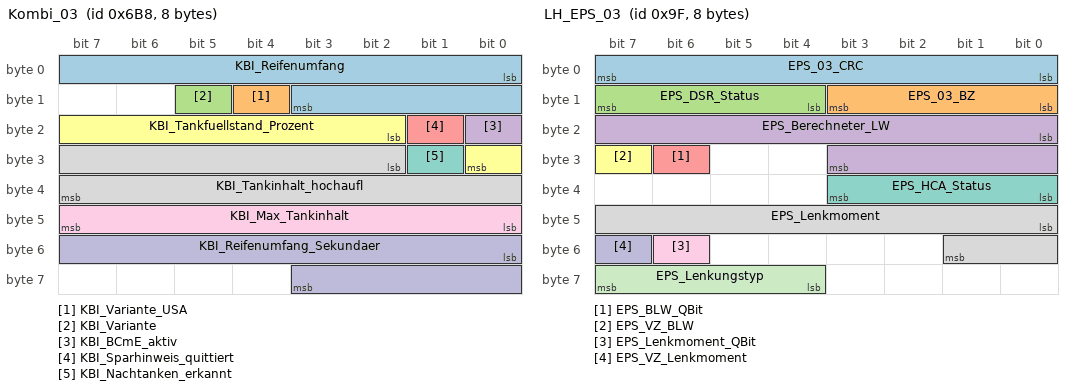
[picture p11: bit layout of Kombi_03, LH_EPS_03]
BO_ 1720 Kombi_03: 8 Vector__XXX
 SG_ KBI_Reifenumfang : 0|12@1+ (1,0) [0|4095] "Unit_MilliMeter" Vector__XXX
 SG_ KBI_Variante_USA : 12|1@1+ (1,0) [0|1] "" Vector__XXX
 SG_ KBI_Variante : 13|1@1+ (1,0) [0|1] ""  Frontradar
 SG_ KBI_BCmE_aktiv : 16|1@1+ (1,0) [0|1] "" Vector__XXX
 SG_ KBI_Sparhinweis_quittiert : 17|1@1+ (1,0) [0|1] "" Vector__XXX
 SG_ KBI_Tankfuellstand_Prozent : 18|7@1+ (1,0) [0|100] "Unit_PerCent" Vector__XXX
 SG_ KBI_Nachtanken_erkannt : 25|1@1+ (1,0) [0|1] "" Vector__XXX
 SG_ KBI_Tankinhalt_hochaufl : 26|14@1+ (0.01,0) [0|163.81] "Unit_Liter" Vector__XXX
 SG_ KBI_Max_Tankinhalt : 40|8@1+ (0.5,0) [0|126.5] "" Vector__XXX
 SG_ KBI_Reifenumfang_Sekundaer : 48|12@1+ (1,0) [0|4095] "Unit_MilliMeter" Vector__XXX

BO_ 2549875031 KS_ACC_Req: 8 Vector__XXX
 SG_ KS_ACC_Req_Data : 0|64@1+ (1,0) [0|1.84467440737096E+019] ""  Frontradar

BO_ 2550006103 KS_ACC_Resp: 8 Frontradar
 SG_ KS_ACC_Resp_Data : 0|64@1+ (1,0) [0|1.84467440737096E+019] "" Vector__XXX

BO_ 2549875023 KS_Kamera_Req: 8 Vector__XXX
 SG_ KS_Kamera_Req_Data : 0|64@1+ (1,0) [0|1.84467440737096E+019] "" Vector__XXX

BO_ 2550006095 KS_Kamera_Resp: 8 Vector__XXX
 SG_ KS_Kamera_Resp_Data : 0|64@1+ (1,0) [0|1.84467440737096E+019] "" Vector__XXX

BO_ 2549875082 KS_SWA_2_Req: 8 Vector__XXX
 SG_ KS_SWA_2_Req_Data : 0|64@1+ (1,0) [0|1.84467440737096E+019] "" Vector__XXX

BO_ 2550006154 KS_SWA_2_Resp: 8 Vector__XXX
 SG_ KS_SWA_2_Resp_Data : 0|64@1+ (1,0) [0|1.84467440737096E+019] "" Vector__XXX

BO_ 2549875022 KS_SWA_Req: 8 Vector__XXX
 SG_ KS_SWA_Req_Data : 0|64@1+ (1,0) [0|1.84467440737096E+019] "" Vector__XXX

BO_ 2550006094 KS_SWA_Resp: 8 Vector__XXX
 SG_ KS_SWA_Resp_Data : 0|64@1+ (1,0) [0|1.84467440737096E+019] "" Vector__XXX

BO_ 919 LDW_02: 8 Frontsensorik
 SG_ LDW_Gong : 12|2@1+ (1,0) [0|3] "" Vector__XXX
 SG_ LDW_Frueh_Spaet : 14|2@1+ (1,0) [0|3] "" Vector__XXX
 SG_ LDW_Texte : 16|4@1+ (1,0) [0|15] "" Vector__XXX
 SG_ LDW_Seite_DLCTLC : 20|1@1+ (1,0) [0|1] "" Vector__XXX
 SG_ LDW_Lernmodus : 21|3@1+ (1,0) [0|7] "" Vector__XXX
 SG_ LDW_Anlaufsp_VLR : 24|4@1+ (1,0) [0|15] "" Vector__XXX
 SG_ LDW_Vib_Amp_VLR : 28|4@1+ (1,0) [0|15] "" Vector__XXX
 SG_ LDW_Anlaufzeit_VLR : 32|4@1+ (1,0) [0|15] "" Vector__XXX
 SG_ LDW_Lernmodus_seitenabhaengig : 36|4@1+ (1,0) [0|15] "" Vector__XXX
 SG_ LDW_DLC : 40|8@1+ (0.01,-1.25) [-1.25|1.25] "Unit_Meter" Vector__XXX
 SG_ LDW_TLC : 48|5@1+ (0.1,0) [0|3] "Unit_Secon" Vector__XXX
 SG_ HC_Uss_Anforderung : 53|1@1+ (1,0) [0|1] "" Vector__XXX
 SG_ EA_Warnblinken : 54|2@1+ (1,0) [0|3] "" Vector__XXX
 SG_ LDW_Warnung_links : 56|1@1+ (1,0) [0|1] "" Vector__XXX
 SG_ LDW_Warnung_rechts : 57|1@1+ (1,0) [0|1] "" Vector__XXX
 SG_ LDW_Codierinfo_fuer_VLR : 58|2@1+ (1,0) [0|3] "" Vector__XXX
 SG_ LDW_Status_LED_gelb : 61|1@1+ (1,0) [0|1] "" Vector__XXX
 SG_ LDW_Status_LED_gruen : 62|1@1+ (1,0) [0|1] "" Vector__XXX

BO_ 159 LH_EPS_03: 8 Vector__XXX
 SG_ EPS_03_CRC : 0|8@1+ (1,0) [0|255] ""  Frontsensorik
 SG_ EPS_03_BZ : 8|4@1+ (1,0) [0|15] ""  Frontsensorik
 SG_ EPS_DSR_Status : 12|4@1+ (1,0) [0|15] "" Vector__XXX
 SG_ EPS_Berechneter_LW : 16|12@1+ (0.15,0) [0|613.95] "Unit_DegreOfArc"  Frontsensorik
 SG_ EPS_BLW_QBit : 30|1@1+ (1,0) [0|1] ""  Frontsensorik
 SG_ EPS_VZ_BLW : 31|1@1+ (1,0) [0|1] ""  Frontsensorik
 SG_ EPS_HCA_Status : 32|4@1+ (1,0) [0|15] ""  Frontsensorik
 SG_ EPS_Lenkmoment : 40|10@1+ (0.01,0) [0|8] "Unit_NewtoMeter"  Frontsensorik
 SG_ EPS_Lenkmoment_QBit : 54|1@1+ (1,0) [0|1] ""  Frontsensorik
 SG_ EPS_VZ_Lenkmoment : 55|1@1+ (1,0) [0|1] ""  Frontsensorik
 SG_ EPS_Lenkungstyp : 60|4@1+ (1,0) [0|15] ""  Frontsensorik

BO_ 981 Licht_Anf_01: 8 Vector__XXX
 SG_ Licht_Anf_01_CRC : 0|8@1+ (1,0) [0|255] "" Vector__XXX
 SG_ Licht_Anf_01_BZ : 8|4@1+ (1,0) [0|15] "" Vector__XXX
 SG_ BCM1_Kurvenlicht_links_Anf : 12|1@1+ (1,0) [0|1] "" Vector__XXX
 SG_ BCM1_Kurvenlicht_rechts_Anf : 13|1@1+ (1,0) [0|1] "" Vector__XXX
 SG_ BCM1_Standlicht_Anf : 14|1@1+ (1,0) [0|1] "" Vector__XXX
 SG_ BCM1_Abblendlicht_Anf : 15|1@1+ (1,0) [0|1] "" Vector__XXX
 SG_ BCM1_Fernlicht_Anf : 16|1@1+ (1,0) [0|1] "" Vector__XXX
 SG_ BCM1_Nebellicht_Anf : 17|1@1+ (1,0) [0|1] "" Vector__XXX
 SG_ BCM1_Parklicht_li_Anf : 18|1@1+ (1,0) [0|1] "" Vector__XXX
 SG_ BCM1_Parklicht_re_Anf : 19|1@1+ (1,0) [0|1] "" Vector__XXX
 SG_ BCM1_Nebelschluss_Ahg_Anf : 20|1@1+ (1,0) [0|1] "" Vector__XXX
 SG_ BCM1_Nebelschluss_Fzg_Anf : 21|1@1+ (1,0) [0|1] "" Vector__XXX
 SG_ BCM1_Schlusslicht_Anf : 22|1@1+ (1,0) [0|1] "" Vector__XXX
 SG_ BCM_Rueckfahrlicht_Anf : 23|1@1+ (1,0) [0|1] "" Vector__XXX
 SG_ BCM1_Signaturlicht_Anf : 24|1@1+ (1,0) [0|1] "" Vector__XXX
 SG_ BCM1_Umfeldleuchten_Anf : 25|1@1+ (1,0) [0|1] "" Vector__XXX
 SG_ BCM1_Tagfahrlicht_Anf : 26|1@1+ (1,0) [0|1] "" Vector__XXX
 SG_ BCM1_Regenlicht_Anf : 27|1@1+ (1,0) [0|1] "" Vector__XXX
 SG_ BCM1_Autobahnlicht_Anf : 28|1@1+ (1,0) [0|1] "" Vector__XXX
 SG_ BCM1_Touristen_Licht_Anf : 29|1@1+ (1,0) [0|1] ""  Frontsensorik
 SG_ BCM1_CH_aktiv : 30|1@1+ (1,0) [0|1] "" Vector__XXX
 SG_ BCM1_LH_aktiv : 31|1@1+ (1,0) [0|1] "" Vector__XXX
 SG_ BCM1_Gleitende_Leuchtw_Anf : 32|1@1+ (1,0) [0|1] "" Vector__XXX
 SG_ BCM1_GLW_Fernlicht_Anf : 33|1@1+ (1,0) [0|1] "" Vector__XXX
 SG_ BCM1_Adaptive_Lichtvert_Anf : 34|1@1+ (1,0) [0|1] "" Vector__XXX
 SG_ BCM1_CH_LH_aktiv : 40|1@1+ (1,0) [0|1] "" Vector__XXX
 SG_ BCM1_Allwetterlicht_Anf : 41|1@1+ (1,0) [0|1] ""  Frontsensorik

BO_ 1624 Licht_vorne_01: 8 Vector__XXX
 SG_ LV_Standlicht_Anzeige : 12|1@1+ (1,0) [0|1] "" Vector__XXX
 SG_ LV_Abblendlicht_Anzeige : 13|1@1+ (1,0) [0|1] ""  Frontsensorik
 SG_ LV_Fernlicht_Anzeige : 14|1@1+ (1,0) [0|1] ""  Frontsensorik
 SG_ LV_Nebellicht_Anzeige : 15|1@1+ (1,0) [0|1] ""  Frontsensorik
 SG_ LV_Nebelschlusslicht_Anzeige : 16|1@1+ (1,0) [0|1] ""  Frontsensorik
 SG_ LV_Tagfahrlicht_Anzeige : 17|1@1+ (1,0) [0|1] "" Vector__XXX
 SG_ LV_AFL_aktiv_Anzeige : 18|1@1+ (1,0) [0|1] ""  Frontsensorik
 SG_ LV_AFL_defekt : 19|1@1+ (1,0) [0|1] "" Vector__XXX
 SG_ LV_Blinker_li_def : 20|1@1+ (1,0) [0|1] "" Vector__XXX
 SG_ LV_Standlicht_li_def : 21|1@1+ (1,0) [0|1] "" Vector__XXX
 SG_ LV_Abblendlicht_li_def : 22|1@1+ (1,0) [0|1] "" Vector__XXX
 SG_ LV_Fernlicht_li_def : 23|1@1+ (1,0) [0|1] "" Vector__XXX
 SG_ LV_Nebellicht_li_def : 24|1@1+ (1,0) [0|1] "" Vector__XXX
 SG_ LV_Blk_li_Seite_def : 25|1@1+ (1,0) [0|1] "" Vector__XXX
 SG_ LV_Tagfahrlicht_li_def : 26|1@1+ (1,0) [0|1] "" Vector__XXX
 SG_ LV_FLA_aktiv_Anzeige : 27|1@1+ (1,0) [0|1] "" Vector__XXX
 SG_ LV_FLA_defekt : 28|1@1+ (1,0) [0|1] "" Vector__XXX
 SG_ LV_FLA_Sensor_blockiert : 29|1@1+ (1,0) [0|1] "" Vector__XXX
 SG_ LV_Blinker_re_def : 30|1@1+ (1,0) [0|1] "" Vector__XXX
 SG_ LV_Standlicht_re_def : 31|1@1+ (1,0) [0|1] "" Vector__XXX
 SG_ LV_Abblendlicht_re_def : 32|1@1+ (1,0) [0|1] "" Vector__XXX
 SG_ LV_Fernlicht_re_def : 33|1@1+ (1,0) [0|1] "" Vector__XXX
 SG_ LV_Nebellicht_re_def : 34|1@1+ (1,0) [0|1] "" Vector__XXX
 SG_ LV_Blk_re_Seite_def : 35|1@1+ (1,0) [0|1] "" Vector__XXX
 SG_ LV_Tagfahrlicht_re_def : 36|1@1+ (1,0) [0|1] "" Vector__XXX
 SG_ LV_Aussenlicht_def : 37|1@1+ (1,0) [0|1] "" Vector__XXX
 SG_ LV_Abblendlicht_TFL_li_def : 38|1@1+ (1,0) [0|1] "" Vector__XXX
 SG_ LV_Nebellicht_TFL_li_def : 39|1@1+ (1,0) [0|1] "" Vector__XXX
 SG_ LV_Standlicht_TFL_li_def : 40|1@1+ (1,0) [0|1] "" Vector__XXX
 SG_ LV_Abblend_Fernlicht_li_def : 41|1@1+ (1,0) [0|1] "" Vector__XXX
 SG_ LV_Abblendlicht_TFL_re_def : 42|1@1+ (1,0) [0|1] "" Vector__XXX
 SG_ LV_Nebellicht_TFL_re_def : 43|1@1+ (1,0) [0|1] "" Vector__XXX
 SG_ LV_Standlicht_TFL_re_def : 44|1@1+ (1,0) [0|1] "" Vector__XXX
 SG_ LV_Abblend_Fernlicht_re_def : 45|1@1+ (1,0) [0|1] "" Vector__XXX
 SG_ LV_Abbiegelicht_li_def : 46|1@1+ (1,0) [0|1] "" Vector__XXX
 SG_ LV_Abbiegelicht_re_def : 47|1@1+ (1,0) [0|1] "" Vector__XXX
 SG_ BCM1_Linksverkehr : 48|1@1+ (1,0) [0|1] "" Vector__XXX
 SG_ BCM1_Licht_Dunkelheit_aktiv : 49|1@1+ (1,0) [0|1] "" Vector__XXX
 SG_ LV_LED_Scheinwerfer_li_def : 50|1@1+ (1,0) [0|1] "" Vector__XXX
 SG_ LV_LED_Scheinwerfer_re_def : 51|1@1+ (1,0) [0|1] "" Vector__XXX
 SG_ LV_Blinker_VL_aktiv : 52|1@1+ (1,0) [0|1] "" Vector__XXX
 SG_ LV_Blinker_VR_aktiv : 53|1@1+ (1,0) [0|1] "" Vector__XXX

CM_ SG_ 1795 ISO_Funktionaler_Req_Abgas "Funktionaler Request für abgasrelevante Steuergeraete";
CM_ SG_ 1792 ISO_ALL_01_Req_Data "Funktionaler Request ALL";
CM_ SG_ 2015 ISO_OBD_Funktionaler_Req_Data "Funktionaler Request für OBD relevante Steuergeraete";
CM_ SG_ 1871 ISO_Kamera_Req_Data "Diagnose Request Kamerasteuergeraet";
CM_ SG_ 1977 ISO_Kamera_Resp_Data "Diagnose Response Kamerasteuergeraet";
CM_ SG_ 1876 ISO_LWRAFS_Req_Data "Diagnose Request Leuchtweitenregulierung / Advanced Frontlighting System";
CM_ SG_ 1982 ISO_LWRAFS_Resp_Data "Diagnose Response Leuchtweitenregulierung / Advanced Frontlighting System";
CM_ SG_ 1870 ISO_SWA_Req_Data "Diagnose Request Spurwechselassistent (Master)";
CM_ SG_ 1976 ISO_SWA_Resp_Data "Diagnose Response Spurwechselassistent (Master)";
CM_ SG_ 791 Kamera_FDD_Obj01_ID "Objekt-ID: Zuordnung einer festen ID zu den Objekten über die Lebenszeit. Damit kann ein Objekttracking im AFS - SG aufgebaut
werden.
";
CM_ SG_ 791 Kamera_FDD_Obj01_Entf_Nah "Genauere Entfernung des erkannten Objekts im Nahbereich (0...100 m).";
CM_ SG_ 791 Kamera_FDD_Obj01_Typ "Objekttyp";
CM_ SG_ 791 Kamera_FDD_Obj01_horizPos "Horizontale Position eines Objekts in Grad. Position bezieht sich auf Objektmitte im Sensorkoordinatensystem. ";
CM_ SG_ 791 Kamera_FDD_Obj01_MehrAlsAchtObj "Detektionsstatus hinsichtlich der Anzahl detektierter Objekte";
CM_ SG_ 791 Kamera_FDD_Obj01_Ersatzw "Objekt entstammt dem Tracking";
CM_ SG_ 791 Kamera_FDD_Obj01_horizDim "Horizontale Ausdehnung eines Objektes";
CM_ SG_ 791 Kamera_FDD_Obj01_vertPos "Verktikale Position eines Objekts. Position bezieht sich auf Unterkante Objekt im Sensorkoordinatensystem. Mathematischer Drehsinn.";
CM_ SG_ 791 Kamera_FDD_Obj01_horizGuete_li "Güte der horizontalen Position (Breite) bzgl. der linken Objektkante. Dieses Signal ersetzt das Signal FDD_Obj01_Guete!";
CM_ SG_ 791 Kamera_FDD_Obj01_horizGuete_re "Güte der horizontalen Position (Breite) bzgl. der rechten Objektkante. Dieses Signal ersetzt das Signal FDD_Obj01_Guete!";
CM_ SG_ 791 Kamera_FDD_Obj01_Entfernung "Eine Entfernungsschzätzung wird anhand des Heckleuchten- und Frontleuchtenabstandes durchgeführt.";
CM_ SG_ 791 Kamera_FDD_Obj01_Objguete "Die Objekt-Güte soll die Qualität der Objektklassifikation darstellen. Bei kleineren Güten ist die Aussage unsicherer.
Ensprechend kann die AFS - Steuerung darauf reagieren und bei unsicheren Objekten die Reaktion verlangsamen.";
CM_ SG_ 799 Kamera_FDD_Obj02_ID "Objekt-ID: Zuordnung einer festen ID zu den Objekten über die Lebenszeit. Damit kann ein Objekttracking im AFS - SG aufgebaut
werden.
";
CM_ SG_ 799 Kamera_FDD_Obj02_Entf_Nah "Genauere Entfernung des erkannten Objekts im Nahbereich (0...100 m).";
CM_ SG_ 799 Kamera_FDD_Obj02_Typ "Objekttyp";
CM_ SG_ 799 Kamera_FDD_Obj02_horizPos "Horizontale Position eines Objekts in Grad. Position bezieht sich auf Objektmitte im Sensorkoordinatensystem. ";
CM_ SG_ 799 Kamera_FDD_Obj02_Ersatzw "Objekt entstammt dem Tracking";
CM_ SG_ 799 Kamera_FDD_Obj02_horizDim "Horizontale Ausdehnung eines Objektes";
CM_ SG_ 799 Kamera_FDD_Obj02_vertPos "Verktikale Position eines Objekts. Position bezieht sich auf Unterkante Objekt im Sensorkoordinatensystem. Mathematischer Drehsinn.";
CM_ SG_ 799 Kamera_FDD_Obj02_horizGuete_li "Güte der horizontalen Position (Breite) bzgl. der linken Objektkante. Dieses Signal ersetzt das Signal FDD_Obj02_Guete!";
CM_ SG_ 799 Kamera_FDD_Obj02_horizGuete_re "Güte der horizontalen Position (Breite) bzgl. der rechten Objektkante. Dieses Signal ersetzt das Signal FDD_Obj02_Guete!";
CM_ SG_ 799 Kamera_FDD_Obj02_Entfernung "Eine Entfernungsschzätzung wird anhand des Heckleuchten- und Frontleuchtenabstandes durchgeführt.";
CM_ SG_ 799 Kamera_FDD_Obj02_Objguete "Die Objekt-Güte soll die Qualität der Objektklassifikation darstellen. Bei kleineren Güten ist die Aussage unsicherer.
Ensprechend kann die AFS - Steuerung darauf reagieren und bei unsicheren Objekten die Reaktion verlangsamen.";
CM_ SG_ 838 Kamera_FDD_Obj03_ID "Objekt-ID: Zuordnung einer festen ID zu den Objekten über die Lebenszeit. Damit kann ein Objekttracking im AFS - SG aufgebaut
werden.
";
CM_ SG_ 838 Kamera_FDD_Obj03_Entf_Nah "Genauere Entfernung des erkannten Objekts im Nahbereich (0...100 m).";
CM_ SG_ 838 Kamera_FDD_Obj03_Typ "Objekttyp";
CM_ SG_ 838 Kamera_FDD_Obj03_horizPos "Horizontale Position eines Objekts in Grad. Position bezieht sich auf Objektmitte im Sensorkoordinatensystem. ";
CM_ SG_ 838 Kamera_FDD_Obj03_Ersatzw "Objekt entstammt dem Tracking";
CM_ SG_ 838 Kamera_FDD_Obj03_horizDim "Horizontale Ausdehnung eines Objektes";
CM_ SG_ 838 Kamera_FDD_Obj03_vertPos "Verktikale Position eines Objekts. Position bezieht sich auf Unterkante Objekt im Sensorkoordinatensystem. Mathematischer Drehsinn.";
CM_ SG_ 838 Kamera_FDD_Obj03_horizGuete_li "Güte der horizontalen Position (Breite) bzgl. der linken Objektkante. Dieses Signal ersetzt das Signal FDD_Obj03_Guete!";
CM_ SG_ 838 Kamera_FDD_Obj03_horizGuete_re "Güte der horizontalen Position (Breite) bzgl. der rechten Objektkante. Dieses Signal ersetzt das Signal FDD_Obj03_Guete!";
CM_ SG_ 838 Kamera_FDD_Obj03_Entfernung "Eine Entfernungsschzätzung wird anhand des Heckleuchten- und Frontleuchtenabstandes durchgeführt.";
CM_ SG_ 838 Kamera_FDD_Obj03_Objguete "Die Objekt-Güte soll die Qualität der Objektklassifikation darstellen. Bei kleineren Güten ist die Aussage unsicherer.
Ensprechend kann die AFS - Steuerung darauf reagieren und bei unsicheren Objekten die Reaktion verlangsamen.";
CM_ SG_ 839 Kamera_FDD_Obj04_ID "Objekt-ID: Zuordnung einer festen ID zu den Objekten über die Lebenszeit. Damit kann ein Objekttracking im AFS - SG aufgebaut
werden.
";
CM_ SG_ 839 Kamera_FDD_Obj04_Entf_Nah "Genauere Entfernung des erkannten Objekts im Nahbereich (0...100 m).";
CM_ SG_ 839 Kamera_FDD_Obj04_Typ "Objekttyp";
CM_ SG_ 839 Kamera_FDD_Obj04_horizPos "Horizontale Position eines Objekts in Grad. Position bezieht sich auf Objektmitte im Sensorkoordinatensystem. ";
CM_ SG_ 839 Kamera_FDD_Obj04_Ersatzw "Objekt entstammt dem Tracking";
CM_ SG_ 839 Kamera_FDD_Obj04_horizDim "Horizontale Ausdehnung eines Objektes";
CM_ SG_ 839 Kamera_FDD_Obj04_vertPos "Verktikale Position eines Objekts. Position bezieht sich auf Unterkante Objekt im Sensorkoordinatensystem. Mathematischer Drehsinn.";
CM_ SG_ 839 Kamera_FDD_Obj04_horizGuete_li "Güte der horizontalen Position (Breite) bzgl. der linken Objektkante. Dieses Signal ersetzt das Signal FDD_Obj04_Guete!";
CM_ SG_ 839 Kamera_FDD_Obj04_horizGuete_re "Güte der horizontalen Position (Breite) bzgl. der rechten Objektkante. Dieses Signal ersetzt das Signal FDD_Obj04_Guete!";
CM_ SG_ 839 Kamera_FDD_Obj04_Entfernung "Eine Entfernungsschzätzung wird anhand des Heckleuchten- und Frontleuchtenabstandes durchgeführt.";
CM_ SG_ 839 Kamera_FDD_Obj04_Objguete "Die Objekt-Güte soll die Qualität der Objektklassifikation darstellen. Bei kleineren Güten ist die Aussage unsicherer.
Ensprechend kann die AFS - Steuerung darauf reagieren und bei unsicheren Objekten die Reaktion verlangsamen.";
CM_ SG_ 840 Kamera_FDD_Obj05_ID "Objekt-ID: Zuordnung einer festen ID zu den Objekten über die Lebenszeit. Damit kann ein Objekttracking im AFS - SG aufgebaut
werden.
";
CM_ SG_ 840 Kamera_FDD_Obj05_Entf_Nah "Genauere Entfernung des erkannten Objekts im Nahbereich (0...100 m).";
CM_ SG_ 840 Kamera_FDD_Obj05_Typ "Objekttyp";
CM_ SG_ 840 Kamera_FDD_Obj05_horizPos "Horizontale Position eines Objekts in Grad. Position bezieht sich auf Objektmitte im Sensorkoordinatensystem. ";
CM_ SG_ 840 Kamera_FDD_Obj05_Ersatzw "Objekt entstammt dem Tracking";
CM_ SG_ 840 Kamera_FDD_Obj05_horizDim "Horizontale Ausdehnung eines Objektes";
CM_ SG_ 840 Kamera_FDD_Obj05_vertPos "Verktikale Position eines Objekts. Position bezieht sich auf Unterkante Objekt im Sensorkoordinatensystem. Mathematischer Drehsinn.";
CM_ SG_ 840 Kamera_FDD_Obj05_horizGuete_li "Güte der horizontalen Position (Breite) bzgl. der linken Objektkante. Dieses Signal ersetzt das Signal FDD_Obj05_Guete!";
CM_ SG_ 840 Kamera_FDD_Obj05_horizGuete_re "Güte der horizontalen Position (Breite) bzgl. der rechten Objektkante. Dieses Signal ersetzt das Signal FDD_Obj05_Guete!";
CM_ SG_ 840 Kamera_FDD_Obj05_Entfernung "Eine Entfernungsschzätzung wird anhand des Heckleuchten- und Frontleuchtenabstandes durchgeführt.";
CM_ SG_ 840 Kamera_FDD_Obj05_Objguete "Die Objekt-Güte soll die Qualität der Objektklassifikation darstellen. Bei kleineren Güten ist die Aussage unsicherer.
Ensprechend kann die AFS - Steuerung darauf reagieren und bei unsicheren Objekten die Reaktion verlangsamen.";
CM_ SG_ 841 Kamera_FDD_Obj06_ID "Objekt-ID: Zuordnung einer festen ID zu den Objekten über die Lebenszeit. Damit kann ein Objekttracking im AFS - SG aufgebaut
werden.
";
CM_ SG_ 841 Kamera_FDD_Obj06_Entf_Nah "Genauere Entfernung des erkannten Objekts im Nahbereich (0...100 m).";
CM_ SG_ 841 Kamera_FDD_Obj06_Typ "Objekttyp";
CM_ SG_ 841 Kamera_FDD_Obj06_horizPos "Horizontale Position eines Objekts in Grad. Position bezieht sich auf Objektmitte im Sensorkoordinatensystem. ";
CM_ SG_ 841 Kamera_FDD_Obj06_Ersatzw "Objekt entstammt dem Tracking";
CM_ SG_ 841 Kamera_FDD_Obj06_horizDim "Horizontale Ausdehnung eines Objektes";
CM_ SG_ 841 Kamera_FDD_Obj06_vertPos "Verktikale Position eines Objekts. Position bezieht sich auf Unterkante Objekt im Sensorkoordinatensystem. Mathematischer Drehsinn.";
CM_ SG_ 841 Kamera_FDD_Obj06_horizGuete_li "Güte der horizontalen Position (Breite) bzgl. der linken Objektkante. Dieses Signal ersetzt das Signal FDD_Obj06_Guete!";
CM_ SG_ 841 Kamera_FDD_Obj06_horizGuete_re "Güte der horizontalen Position (Breite) bzgl. der rechten Objektkante. Dieses Signal ersetzt das Signal FDD_Obj06_Guete!";
CM_ SG_ 841 Kamera_FDD_Obj06_Entfernung "Eine Entfernungsschzätzung wird anhand des Heckleuchten- und Frontleuchtenabstandes durchgeführt.";
CM_ SG_ 841 Kamera_FDD_Obj06_Objguete "Die Objekt-Güte soll die Qualität der Objektklassifikation darstellen. Bei kleineren Güten ist die Aussage unsicherer.
Ensprechend kann die AFS - Steuerung darauf reagieren und bei unsicheren Objekten die Reaktion verlangsamen.";
CM_ SG_ 842 Kamera_FDD_Obj07_ID "Objekt-ID: Zuordnung einer festen ID zu den Objekten über die Lebenszeit. Damit kann ein Objekttracking im AFS - SG aufgebaut
werden.
";
CM_ SG_ 842 Kamera_FDD_Obj07_Entf_Nah "Genauere Entfernung des erkannten Objekts im Nahbereich (0...100 m).";
CM_ SG_ 842 Kamera_FDD_Obj07_Typ "Objekttyp";
CM_ SG_ 842 Kamera_FDD_Obj07_horizPos "Horizontale Position eines Objekts in Grad. Position bezieht sich auf Objektmitte im Sensorkoordinatensystem. ";
CM_ SG_ 842 Kamera_FDD_Obj07_Ersatzw "Objekt entstammt dem Tracking";
CM_ SG_ 842 Kamera_FDD_Obj07_horizDim "Horizontale Ausdehnung eines Objektes";
CM_ SG_ 842 Kamera_FDD_Obj07_vertPos "Verktikale Position eines Objekts. Position bezieht sich auf Unterkante Objekt im Sensorkoordinatensystem. Mathematischer Drehsinn.";
CM_ SG_ 842 Kamera_FDD_Obj07_horizGuete_li "Güte der horizontalen Position (Breite) bzgl. der linken Objektkante. Dieses Signal ersetzt das Signal FDD_Obj07_Guete!";
CM_ SG_ 842 Kamera_FDD_Obj07_horizGuete_re "Güte der horizontalen Position (Breite) bzgl. der rechten Objektkante. Dieses Signal ersetzt das Signal FDD_Obj07_Guete!";
CM_ SG_ 842 Kamera_FDD_Obj07_Entfernung "Eine Entfernungsschzätzung wird anhand des Heckleuchten- und Frontleuchtenabstandes durchgeführt.";
CM_ SG_ 842 Kamera_FDD_Obj07_Objguete "Die Objekt-Güte soll die Qualität der Objektklassifikation darstellen. Bei kleineren Güten ist die Aussage unsicherer.
Ensprechend kann die AFS - Steuerung darauf reagieren und bei unsicheren Objekten die Reaktion verlangsamen.";
CM_ SG_ 843 Kamera_FDD_Obj08_ID "Objekt-ID: Zuordnung einer festen ID zu den Objekten über die Lebenszeit. Damit kann ein Objekttracking im AFS - SG aufgebaut
werden.
";
CM_ SG_ 843 Kamera_FDD_Obj08_Entf_Nah "Genauere Entfernung des erkannten Objekts im Nahbereich (0...100 m).";
CM_ SG_ 843 Kamera_FDD_Obj08_Typ "Objekttyp";
CM_ SG_ 843 Kamera_FDD_Obj08_horizPos "Horizontale Position eines Objekts in Grad. Position bezieht sich auf Objektmitte im Sensorkoordinatensystem. ";
CM_ SG_ 843 Kamera_FDD_Obj08_Ersatzw "Objekt entstammt dem Tracking";
CM_ SG_ 843 Kamera_FDD_Obj08_horizDim "Horizontale Ausdehnung eines Objektes";
CM_ SG_ 843 Kamera_FDD_Obj08_vertPos "Verktikale Position eines Objekts. Position bezieht sich auf Unterkante Objekt im Sensorkoordinatensystem. Mathematischer Drehsinn.";
CM_ SG_ 843 Kamera_FDD_Obj08_horizGuete_li "Güte der horizontalen Position (Breite) bzgl. der linken Objektkante. Dieses Signal ersetzt das Signal FDD_Obj08_Guete!";
CM_ SG_ 843 Kamera_FDD_Obj08_horizGuete_re "Güte der horizontalen Position (Breite) bzgl. der rechten Objektkante. Dieses Signal ersetzt das Signal FDD_Obj08_Guete!";
CM_ SG_ 843 Kamera_FDD_Obj08_Entfernung "Eine Entfernungsschzätzung wird anhand des Heckleuchten- und Frontleuchtenabstandes durchgeführt.";
CM_ SG_ 843 Kamera_FDD_Obj08_Objguete "Die Objekt-Güte soll die Qualität der Objektklassifikation darstellen. Bei kleineren Güten ist die Aussage unsicherer.
Ensprechend kann die AFS - Steuerung darauf reagieren und bei unsicheren Objekten die Reaktion verlangsamen.";
CM_ BO_ 844 "Diese beiden Botschaften garantieren, dass maximal 2 Strassenleuchten immer als Objekte ausgegeben werden, falls vorhanden, auch wenn mehr als 6 Objekte in der Szene vorhanden sind. Sind weniger als 7 Objekte in der Szene vorhanden, werden die Daten der S";
CM_ SG_ 844 Kamera_FDD_SL_01_ID "Eindeutige ID der von der Kamera erkannten Strassenleuchte. Signal gilt für FDD_Strassenleuchte01 bis FDD_Strassenleuchte02.";
CM_ SG_ 844 Kamera_FDD_SL_01_horizPos "horizontale Position der erkannten Strassenleuchte. Signal gilt für FDD_Strassenleuchte01 bis FDD_Strassenleuchte02.";
CM_ SG_ 844 Kamera_FDD_SL_01_vertPos "Vertikale Position der erkannnten Strassenleucht. Wert gibt Position des Mittelpunkts an. Signal gilt für FDD_Strassenleuchte01 bis FDD_Strassenleuchte02.";
CM_ SG_ 844 Kamera_FDD_SL_01_Typ "Typ der erkannten Strassenleuchte. Signal gilt für FDD_Strassenleuchte01 bis FDD_Strassenleuchte02.";
CM_ SG_ 844 Kamera_FDD_SL_01_Objguete "Die Güte mit der die Strassenleuchte erkannt wurde. Signal gilt für FDD_Strassenleuchte01 bis FDD_Strassenleuchte02.";
CM_ SG_ 844 Kamera_FDD_SL_01_Ersatzw "Gibt an, ob es sich bei den gesendeten Werten um gemessene Werte handelt oder um Ersatzwerte durch Abschätzung. Signal gilt für FDD_Strassenleuchte01 bis FDD_Strassenleuchte02.";
CM_ BO_ 845 "Diese beiden Botschaften garantieren, dass maximal 2 Strassenleuchten immer als Objekte ausgegeben werden, falls vorhanden, auch wenn mehr als 6 Objekte in der Szene vorhanden sind. Sind weniger als 7 Objekte in der Szene vorhanden, werden die Daten der S";
CM_ SG_ 845 Kamera_FDD_SL_02_ID "Eindeutige ID der von der Kamera erkannten Strassenleuchte. Signal gilt für FDD_Strassenleuchte01 bis FDD_Strassenleuchte02.";
CM_ SG_ 845 Kamera_FDD_SL_02_horizPos "horizontale Position der erkannten Strassenleuchte. Signal gilt für FDD_Strassenleuchte01 bis FDD_Strassenleuchte02.";
CM_ SG_ 845 Kamera_FDD_SL_02_vertPos "Vertikale Position der erkannnten Strassenleucht. Wert gibt Position des Mittelpunkts an. Signal gilt für FDD_Strassenleuchte01 bis FDD_Strassenleuchte02.";
CM_ SG_ 845 Kamera_FDD_SL_02_Typ "Typ der erkannten Strassenleuchte. Signal gilt für FDD_Strassenleuchte01 bis FDD_Strassenleuchte02.";
CM_ SG_ 845 Kamera_FDD_SL_02_Objguete "Die Güte mit der die Strassenleuchte erkannt wurde. Signal gilt für FDD_Strassenleuchte01 bis FDD_Strassenleuchte02.";
CM_ SG_ 845 Kamera_FDD_SL_02_Ersatzw "Gibt an, ob es sich bei den gesendeten Werten um gemessene Werte handelt oder um Ersatzwerte durch Abschätzung. Signal gilt für FDD_Strassenleuchte01 bis FDD_Strassenleuchte02.";
CM_ SG_ 792 Kamera_Systemzustand "Systemzustand der Kamera";
CM_ SG_ 792 Kamera_FDD_Eigenblend_Guete "Diese Signal gibt an, welches Maß einer Eigenblendung vorliegt.";
CM_ SG_ 792 Kamera_FDD_Eigenblend "Dieses Signal gibt an, ob von der Kamera eine Eigenblendung, z.B. Nebel, erkannt wird.";
CM_ SG_ 792 Kamera_FDD_Strassenbeleuchung "Status Straßenbeleuchungsdetektion";
CM_ SG_ 792 Kamera_FDD_Funktionsstatus "Status der Fahrzeugdetektion bei Dunkelheit";
CM_ SG_ 792 Kamera_FDD_Anz_Strassenleuchten "Anzahl der erkannten Straßenleuchten";
CM_ SG_ 792 Kamera_FDD_Verkehrsrichtung "Gibt bei Nacht die auf Grund der entgegenkommenden Fahrzeuge erkannte Verkehrsrichtung an";
CM_ SG_ 792 Kamera_FSH_aktiv "Bei aktivierter (lokaler) Frontscheibenheizung wird die Scheibentemperaturmessung des Klimafeuchtesensors beeinflusst. Über das Signal wird dem Klima-SG mitgeteilt, dass die lokale Scheibenheizung aktiviert ist, um entsprechende Korrekturwerte bei der Sch";
CM_ BO_ 960 "MQB";
CM_ SG_ 960 Klemmen_Status_01_CRC "Für MLB:
'Berechnung siehe Lastenheft 'Kommunikationsabsicherung für FlexRay und CAN''

Ab MQB und MLBevo:
'Berechnung siehe Lastenheft 'End-to-End Kommunikationsabsicherung''

Endwerte siehe Begleitdokument 'S-PDU Kennungsfolgen'";
CM_ SG_ 960 Klemmen_Status_01_BZ "4bit Botschaftszaehler; wird in jeder Sendebotschaft inkrementiert";
CM_ SG_ 960 RSt_Fahrerhinweise "Über das Signal fordert das BCM Fahrerhinweise im Kombi für die Funktion RemoteStart an.";
CM_ SG_ 960 ZAS_Kl_S "Klemme S: S-Kontakt (Schluessel steckt)
";
CM_ SG_ 960 ZAS_Kl_15 "Klemme 15: Zuendung (SW-Kl.15)
";
CM_ SG_ 960 ZAS_Kl_X "Klemme 75
";
CM_ SG_ 960 ZAS_Kl_50_Startanforderung "Klemme 50: Startwunsch Fahrer
";
CM_ SG_ 960 BCM_Remotestart_Betrieb "Zeigt den Status des RemoteStarts an, d.h. KL15_RSt ist aktiviert und der Motorlauf ist im RSt-Betrieb aktiv.";
CM_ SG_ 960 ZAS_Kl_Infotainment "Separate Klemmeninformation für das Infotainment. Signal entspricht im wesentlichen einer Klemme S Information, kann aber über einen Vor - bzw. Nachlauf zu Klemme S verfügen. 
Ein konkreter Anwendungsfall für einen Nachlauf ist die Abschaltung der Klemme";
CM_ SG_ 960 BCM_Remotestart_KL15_Anf "Zeigt den Status der Aktivierung der KL15_RST durch das BCM an.";
CM_ SG_ 960 BCM_Remotestart_MO_Start "Nachdem das BCM die Remotestart MSG Freigabe sicher erkannt hat, fordert das BCM wiederum über dieses Signal vom MSG einen Motorstart durchzuführen.";
CM_ SG_ 960 KST_Warn_P1_ZST_def "Kombi Prio Warnung Klemmensteuerung 
Zündschloß defekt, Service aufsuchen!";
CM_ SG_ 960 KST_Warn_P2_ZST_def "Kombi Prio Warnung Klemmensteuerung
Zündschloß defekt!
";
CM_ SG_ 960 KST_Fahrerhinweis_1 "Signalisierung Fahrerhinweis 1 der Klemmensteuerung an das Kombi";
CM_ SG_ 960 KST_Fahrerhinweis_2 "Signalisierung Fahrerhinweis 2 der Klemmensteuerung an das Kombi";
CM_ SG_ 960 KST_Fahrerhinweis_3 "Signalisierung Fahrerhinweis 3 der Klemmensteuerung an das Kombi";
CM_ SG_ 960 KST_Fahrerhinweis_4 "Signalisierung Fahrerhinweis 4 der Klemmensteuerung an das Kombi";
CM_ SG_ 960 KST_Fahrerhinweis_5 "Anzeigesignal für RemoteStart";
CM_ SG_ 960 KST_Fahrerhinweis_6 "Signal aktiviert die Kombi-Anzeigeinstrumente (Drehzahl, Tankinhalt, Kühlmitteltemperatur) während aktiviertem RemoteStart-Betrieb";
CM_ BO_ 1646 "ab MQB 7.3";
CM_ SG_ 1646 KL_STL_aktiv "Betriebsstatus Standlueftung
";
CM_ SG_ 1646 KL_STH_aktiv "Betriebsstatus Standheizung
";
CM_ SG_ 1646 KL_Solarluefter_aktiv "Betriebsstatus Solarluefter
";
CM_ SG_ 1646 KL_Umluft_Taste "Betaetigung Umlufttaste
";
CM_ SG_ 1646 KL_Geblaese_Fond_Status "Status Geblaese









";
CM_ SG_ 1646 KL_STH_Ansteuerung "Ansteuerung STH

";
CM_ SG_ 1646 KL_STH_Betriebsdauer "Betriebsdauer STH";
CM_ SG_ 1646 KL_Magnetventil "Anforderung des Bypassventils.";
CM_ SG_ 1646 KL_WaPu "Ansteuerung der Standheizungswasserpumpe";
CM_ SG_ 1646 KL_Geblaese_Status "Status Geblaese









";
CM_ SG_ 1646 KL_Restwaerme_aktiv "Signal zur Aktivierung/Deaktivierung der Wasserpumpe bei Restwärme; 
reduzierte IRÜ Empfindlichkeit";
CM_ SG_ 1646 KL_Kompressorkupplung "Signal zur Aktivierung/Deaktivierung der Kompressorkupplung";
CM_ SG_ 1646 KL_BCmE_Livetip_Freigabe "Status der Klimaanlage. 
Zeigt an, ob der Livetip 'Fenster schließen wegen Ineffizienz Klimaanlage' sinvollerweise angezeigt werden soll

MQB: nur Audi relevant";
CM_ SG_ 1646 KL_SH_Soll_hl "Einstellung Sitzheizung hinten links (0...6)";
CM_ SG_ 1646 KL_SH_Soll_hr "Einstellung Sitzheizung hinten rechts (0...6)";
CM_ SG_ 1646 KL_Innen_Temp "Innentemperatur

";
CM_ SG_ 1646 KL_I_Geblaese_Fond "Stromaufnahme Gebläse Heck";
CM_ SG_ 1646 KL_Heizkreisventilstellung "Bei MQB PHEV: Stellung Heizkreisventil Motor";
CM_ SG_ 1646 KL_FSH_Automatikbetrieb "Ermöglicht eine Unterscheidung von Anforderung FSH durch Kundenwunsch und Anforderung FSH durch Regelung des Klimasteuergeräts.
Das Signal liegt als Pegel an.";
CM_ SG_ 1646 KL_SIH_LEH_Verteilung_VL "Vom Kunden eingestellte Aufteilung der Heizleistung auf Sitzfläche und Lehnefläche für Sitz vorne links";
CM_ SG_ 1646 KL_SIH_LEL_Verteilung_VL "Vom Kunden eingestellte Aufteilung der Lüftungsleistung auf Sitzfläche und Lehnenfläche für Sitz vorne links";
CM_ SG_ 1646 KL_SIH_LEH_Verteilung_VR "Vom Kunden eingestellte Aufteilung der Heizleistung auf Sitzfläche und Lehnefläche für Sitz vorne rechts";
CM_ SG_ 1646 KL_SIH_LEL_Verteilung_VR "Vom Kunden eingestellte Aufteilung der Lüftungsleistung auf Sitzfläche und Lehnenfläche für Sitz vorne rechts";
CM_ BO_ 949 "ab MQB 7.4";
CM_ SG_ 949 KL_Drehz_Anh "Drehzahlanhebung vom Motor angefordert

";
CM_ SG_ 949 KL_Vorwarn_Komp_ein "Vorwarnung Kompressor ein; 140ms vorher; Information für Motor zum Aufbau Momentenreserve";
CM_ SG_ 949 KL_AC_Schalter "AC Schalter
";
CM_ SG_ 949 KL_Vorwarn_Zuheizer_ein "Vorwarnung Zuheizerbetrieb
";
CM_ SG_ 949 KL_Zustand "Beschreibt den Zustand des Klima-/Heizungsbedienteils. (OFF-Mode Bedienteil)

PAG (MLB): Beschreibt den Zustand des Kompressors";
CM_ SG_ 949 KL_Kompressorkupplung_linear "Sollwert zur Ansteuerung der Kompressorkupplung";
CM_ SG_ 949 KL_Charisma_FahrPr "MLBevo: Aktuelles Fahrprogramm des Charisma-Teilnehmers (siehe Systemlastenheft Drive Select)
MQB: Istwert der Kennlinie (siehe Systemlastenheft MQB FPA)";
CM_ SG_ 949 KL_Charisma_Status "Charisma Systemstatus des Charisma-Teilnehmers

Wert 0x3 ist nur für Fahrzeuge ab MQB relevant";
CM_ SG_ 949 KL_nachtr_Stopp_Anf "Dieses Signal dient dem Motor als Trigger, dass ein nachträglicher Motorstopp eingeleitet werden kann, wenn es die Bedingungen des StSt Koordinators dies zulassen. ";
CM_ SG_ 949 KL_T_Charge "Signal für Tastenbetätigung Charge-Taste (SOC Increasing)";
CM_ SG_ 949 KL_Last_Kompr "Aktuelles Verlustmoment der Klimaanlage bezogen auf die Kurbelwelle. Wird der Klimakompressor nicht angesteuert, ist das Schleppmoment bezogen auf die Kurbelwelle zu senden.";
CM_ SG_ 949 KL_Spannungs_Anf "Forderung des Klima-SG's zur Spannungsanhebung.";
CM_ SG_ 949 KL_Thermomanagement "Stufen des Thermomanagements;
Bei Klemme 15 AUS und erkannten Timeout zum Klimabedienteil (z.B. Klimabedienteil während des Motorsteuergeräte-Kommunikations-Nachlaufs bereits im NM-Zustand ¿Bus Sleep¿)
erfolgt keine Ansteuerung der Wasserpumpe durch die";
CM_ SG_ 949 KL_StartStopp_Info "Stopp-Freigabe und Start-Anforderung an den Start-Stopp-Koordinator";
CM_ SG_ 949 KL_Freilauf_Info "Freilauf Informationssignal von Klima zum Freilaufkoordinator. Klima kann über dieses Signal den Freilauf freigeben, verhindern bzw. explizit anfordern.";
CM_ SG_ 949 KL_Anf_KL "Anforderung Kühlerlüfter der Klimaanlage in Prozent

";
CM_ SG_ 949 KL_el_Zuheizer_Stufe "Vorgabe für Motorsteuergeraet PTC-Stufe; im MLB-B8 und MQB nur Stufe 0...3

";
CM_ SG_ 949 KL_Ausstattung_Klima "Austtattungsart der Klimabedienung";
CM_ SG_ 949 KL_Variante_Standheizung "Identifikation der Variante der Standheizungen zur Berechnung der energetischen Zielzeit";
CM_ SG_ 1511 KL_HV_Heizer_Strom "Strom HV-Heizer für Reichweitenberechnung";
CM_ SG_ 1511 KL_EKK_Strom "EKK  Stromaufnahme (Hochvolt)";
CM_ SG_ 1511 KL_Pumpe_02_Soll "Anforderung KM-Pumpe Klimakreislauf
Init (126dec)      = 0% Ansteuerung Pumpe
Fehler (127dec) = 100% Ansteuerung Pumpe";
CM_ SG_ 1511 KL_Ventil_03_Soll "Anforderung Batteriebypass-Ventil im Klimakreislauf";
CM_ SG_ 1511 KL_Ventil_10_Status "Status Ventil_Wärmepumpe; 
nicht angesteuert: Motor- und Heizkreislauf getrennt; 
angesteuert: Motor- und Heizkreislauf verbunden.";
CM_ SG_ 1511 KL_Senderkennung "Gibt an, welches SG (Klima oder WP) die Botschaft sendet";
CM_ SG_ 1511 WP_KJ_Soll "Anforderung der Kuehlerjalousiestellung durch Waermepumpen SG";
CM_ SG_ 1511 KL_Fehler_HV_EKK "Fehlersignal bei Erkennung HV Fehler am elektrischen Klimakompressor EKK
Sender: Klima MQB (evtl. Wärmepumpen SG MQB, OBD SG MQB)";
CM_ SG_ 1511 KL_Fehler_HV_Heizer "Fehlersignal bei Erkennung HV Fehler am HV Heizer
Sender: Klima MQB (evtl. Wärmepumpen SG MQB, OBD SG MQB)";
CM_ SG_ 1511 KL_BattKond_WaPu_DZMax "Maximal-Drehzahl der Wasserpumpe im Batteriekühlkreislauf als Vorgabe für BMS";
CM_ SG_ 1511 WP_Kuehlerluefter_Anf "Anforderung Kühlerlüfter durch Wärmepumpen SG";
CM_ SG_ 1511 KL_KM_ASV_01_Status "Schaltstatus Kältemittel Absperrventil
VW370/9 PHEV = Ventil vor Verdampfer";
CM_ SG_ 1511 KL_KM_ASV_02_Status "Schaltstatus Kältemittel Absperrventil
VW370/9 PHEV = Ventil vor Chiller";
CM_ SG_ 1514 KL_Kundenwunsch_Kuehlen "KBT meldet aktiven Kühlungswunsch an Waermepumpen SG";
CM_ SG_ 1514 KL_OBD_Status "Dieses Bit steuert die MIL-Lampe an (Motorsteuergerät reicht diese Info an Kombi weiter).";
CM_ SG_ 1514 KL_KLE_Fehler_Anf "Anfrage der Klimatisierung an das MSG, ob ein Fehler im Kühlerlüfter vorliegt.";
CM_ SG_ 1514 KL_Fehler_NTKreis "Über dieses Fehlersignal werden andere Steuergeräte am NT-Kreis über einen Fehler in der Klimatisierung informiert und können so Folgefehlereinträge vermeiden.";
CM_ SG_ 1514 KL_Mot_Tk_Soll_li "Stellung Temperaturklappe Soll links";
CM_ SG_ 1514 KL_Mot_Tk_Soll_re "Stellung Temperaturklappe Soll rechts";
CM_ SG_ 1514 KL_VK_Anf "Starten einer Standklimatisierung ausgehend von der Climatronic Richtung Lademanagment.";
CM_ SG_ 1514 KL_Standklima_Status_02 "Status der Standklimatisierung (Innenraum)";
CM_ SG_ 1514 KL_Standklima_RemoteModus "Modus (Lüften, Kühlen, Heizen) der Standklimatisierung (Innenraum) zur Remote Anzeige";
CM_ SG_ 1514 KBT_Defrost_aktiv "Defrostmodus im KBT aktiv";
CM_ SG_ 1514 KL_VK_Betriebsdauer "Berechnete notwendige Betriebsdauer der Vorkonditionierung des Innerraumes (Standklimatisierung). ";
CM_ SG_ 1514 KL_Heizbedarf "Bedarf an Heizmenge für Innenraumklimatisierung";
CM_ SG_ 1514 KL_Innentemp_KBT_Sensor "Temperatur Innenraum vor Klimabedienteil";
CM_ SG_ 1514 KL_Vorkond_Strategie "Strategie der Vorkonditionierung des Innenraums";
CM_ SG_ 1515 KL_Abl_Soll_li "Ausblastemperatur Soll Links";
CM_ SG_ 1515 KL_Abl_Soll_re "Ausblastemperatur Soll Rechts";
CM_ SG_ 1515 KL_Verdampfer_Soll "Soll Temperatur nach Verdampfer";
CM_ SG_ 1515 KL_Abl_Ist_li "Ausblastemperatur Ist Links";
CM_ SG_ 1515 KL_Abl_Ist_re "Ausblastemperatur Ist Rechts";
CM_ SG_ 1515 KL_Verdampfer_Ist "Ist Temperatur nach Verdampfer";
CM_ SG_ 1515 KL_TaupEps_Korr "Korrigierter Taupunktabstannd Windschutzscheibe Innen";
CM_ BO_ 1712 "D4 und B8-PA

1:1 LIN-CAN Botschaft, nur bei Kl.15 EIN gesendet";
CM_ SG_ 1712 FS_ResponseError "siehe LIN2.0-Specification
(Darf nicht über ein Fehlergueltigkeitsbit abgesichtert werden!)";
CM_ BO_ 1717 "ab D4 gültig  --  geänderter Wertebereich und Signalnamen
1:1 LIN-CAN Botschaft vom BCM1, nur bei Kl.15 EIN gesendet";
CM_ SG_ 1717 FSA_Taupunkt "'Init' falls nicht verbaut";
CM_ SG_ 1717 FSA_ResponseError "siehe LIN2.0-Specification
(Darf nicht über ein Fehlergueltigkeitsbit abgesichtert werden!)";
CM_ SG_ 1717 FSA_Temp_Luft "gemessene Temperatur im Luftstrom (z.B. NTC am Sensor)
'Init' falls nicht verbaut
(+61°C bedeutet: Temp_Luft > 60,9°C !)";
CM_ SG_ 1717 FSA_HW "Hardwarestand";
CM_ SG_ 1717 FSA_SW "Softwarestand";
CM_ SG_ 1717 FSA_Sensorheizung_Status "Status der Heizung im Feuchteelement (z.B. SHT10).
0 (=inaktiv) auch bei nicht verbaut";
CM_ SG_ 2549088343 ACC_KompSchutz "Funktionseinschränkung aufgrund Komponentenschutz aktiv";
CM_ SG_ 2549088343 ACC_Abschaltstufe "Funktionseinschränkung aufgrund aktiver Abschaltstufe";
CM_ SG_ 2549088343 ACC_Transport_Mode "Funktionseinschränkung aufgrund aktivem Transport Mode und/oder Transport Schutz";
CM_ SG_ 2549088343 ACC_Nachlauftyp "Abgebildet wird die von der Hardware vorgegebene Möglichkeit, die Kommunikation nach Klemme 15 = AUS aufrecht zu erhalten. Es wird ein Init-Wert gesendet.
0 = Kommunikation nur bei KL15=EIN (kein Nachlauf, nicht weckfähig)
1 = Kommunikation nach KL15=AU";
CM_ SG_ 2549088343 ACC_SNI "Das Signal beinhaltet den Source Node Identifier (Knotenadresse, die auch in der Abbildungsvorschrift zur CAN-ID für die NM-High Botschaft verwendet wird).";
CM_ SG_ 2549088304 FLA_KompSchutz "Funktionseinschränkung aufgrund Komponentenschutz aktiv";
CM_ SG_ 2549088304 FLA_Abschaltstufe "Funktionseinschränkung aufgrund aktiver Abschaltstufe";
CM_ SG_ 2549088304 FLA_Transport_Mode "Funktionseinschränkung aufgrund aktivem Transport Mode und/oder Transport Schutz";
CM_ SG_ 2549088304 FLA_Nachlauftyp "Abgebildet wird die von der Hardware vorgegebene Möglichkeit, die Kommunikation nach Klemme 15 = AUS aufrecht zu erhalten. Es wird ein Init-Wert gesendet.
0 = Kommunikation nur bei KL15=EIN (kein Nachlauf, nicht weckfähig)
1 = Kommunikation nach KL15=AU";
CM_ SG_ 2549088304 FLA_SNI "Das Signal beinhaltet den Source Node Identifier (Knotenadresse, die auch in der Abbildungsvorschrift zur CAN-ID für die NM-High Botschaft verwendet wird).";
CM_ SG_ 2549088304 FLA_KD_Fehler "Kundendienstfehlerbit FLA";
CM_ SG_ 2549088335 Kamera_KompSchutz "Funktionseinschränkung aufgrund Komponentenschutz aktiv";
CM_ SG_ 2549088335 Kamera_Abschaltstufe "Funktionseinschränkung aufgrund aktiver Abschaltstufe";
CM_ SG_ 2549088335 Kamera_Transport_Mode "Funktionseinschränkung aufgrund aktivem Transport Mode und/oder Transport Schutz";
CM_ SG_ 2549088335 Kamera_Nachlauftyp "Abgebildet wird die von der Hardware vorgegebene Möglichkeit, die Kommunikation nach Klemme 15 = AUS aufrecht zu erhalten. Es wird ein Init-Wert gesendet.
0 = Kommunikation nur bei KL15=EIN (kein Nachlauf, nicht weckfähig)
1 = Kommunikation nach KL15=AU";
CM_ SG_ 2549088335 Kamera_SNI "Das Signal beinhaltet den Source Node Identifier (Knotenadresse, die auch in der Abbildungsvorschrift zur CAN-ID für die NM-High Botschaft verwendet wird).";
CM_ SG_ 2549088335 Kamera_KD_Fehler "Status Kundendienstfehlerspeichereinträge
";
CM_ SG_ 2549088340 LWRAFS_KompSchutz "Funktionseinschränkung aufgrund Komponentenschutz aktiv";
CM_ SG_ 2549088340 LWRAFS_Abschaltstufe "Funktionseinschränkung aufgrund aktiver Abschaltstufe";
CM_ SG_ 2549088340 LWRAFS_Transport_Mode "Funktionseinschränkung aufgrund aktivem Transport Mode und/oder Transport Schutz";
CM_ SG_ 2549088340 LWRAFS_Nachlauftyp "Abgebildet wird die von der Hardware vorgegebene Möglichkeit, die Kommunikation nach Klemme 15 = AUS aufrecht zu erhalten. Es wird ein Init-Wert gesendet.
0 = Kommunikation nur bei KL15=EIN (kein Nachlauf, nicht weckfähig)
1 = Kommunikation nach KL15=AU";
CM_ SG_ 2549088340 LWRAFS_SNI "Das Signal beinhaltet den Source Node Identifier (Knotenadresse, die auch in der Abbildungsvorschrift zur CAN-ID für die NM-High Botschaft verwendet wird).";
CM_ SG_ 2549088340 LWR_KD_Fehler "Bei gesetztem Bit ist mindestens ein Kundendienstfehler eingetragen";
CM_ SG_ 2549088334 SWA_KompSchutz "Funktionseinschränkung aufgrund Komponentenschutz aktiv";
CM_ SG_ 2549088334 SWA_Abschaltstufe "Funktionseinschränkung aufgrund aktiver Abschaltstufe";
CM_ SG_ 2549088334 SWA_Transport_Mode "Funktionseinschränkung aufgrund aktivem Transport Mode und/oder Transport Schutz";
CM_ SG_ 2549088334 SWA_Nachlauftyp "Abgebildet wird die von der Hardware vorgegebene Möglichkeit, die Kommunikation nach Klemme 15 = AUS aufrecht zu erhalten. Es wird ein Init-Wert gesendet.
0 = Kommunikation nur bei KL15=EIN (kein Nachlauf, nicht weckfähig)
1 = Kommunikation nach KL15=AU";
CM_ SG_ 2549088334 SWA_SNI "Das Signal beinhaltet den Source Node Identifier (Knotenadresse, die auch in der Abbildungsvorschrift zur CAN-ID für die NM-High Botschaft verwendet wird).";
CM_ SG_ 2549088334 KN_SWA_BusKnockOutTimer "Ausgabe des BusKnockOut-Timer in der Knotenbotschaft";
CM_ SG_ 2549088334 SWA_KD_Fehler "Bei gesetztem Bit ist mindestens ein Kundendienstfehler eingetragen";
CM_ BO_ 779 "MQB";
CM_ SG_ 779 KBI_ABS_Lampe "ABS-Sicherheits-Lampe wurde eingeschaltet.";
CM_ SG_ 779 KBI_ESP_Lampe "ESP-Sicherheits-Lampe wurde eingeschaltet ";
CM_ SG_ 779 KBI_BKL_Lampe "Sicherheits-Lampe Bremskontrolle wurde eingeschaltet;
";
CM_ SG_ 779 KBI_Airbag_Lampe "Airbag Sicherheits-Lampe wurde eingeschaltet ";
CM_ SG_ 779 KBI_SILA_gueltig "Rückmeldeinformation (Bit 1-6) ist gültig";
CM_ SG_ 779 KBI_Lenkung_Lampe "Sicherheits-Lampe der Lenkung (Lenkhilfe EPS, Audi-Dynamic-Steering ...) wurde eingeschaltet.

0x0 = Lenkungs-Lampe aus
0x1 = Lenkungs-Lampe ein";
CM_ SG_ 779 KBI_Vorglueh_System_Lampe "Rückmeldung der Vorglühlampe bzw. Motor Systemlampe (MO_Systemlampe) an den Motor (bei Diesel und Otto!). Hardwaremässig gleiche LED im Kombi (EPC- oder Glühwendel), Unterscheidung nur über Ziffernblatt.";
CM_ SG_ 779 KBI_NV_in_Anzeige "Das Bit gibt dem NV die Information, ob NV-Bild im Kombi in der Anzeige ist. (Information ist notwendig um Kontrasverstellungen nur dann zuzulassen, wenn der Fahrer das Feedback über das  Kombidisplay bekommt.)";
CM_ SG_ 779 KBI_Anzeigestatus_ACC "Status der ACC-Anzeige im nicht permanenten Displaybereich";
CM_ SG_ 779 KBI_Anzeigestatus_GRA "Anzeigestatus der GRA High Wunschgeschwindigkeitsanzeige im Kombiinstrument.
Bei VW bedeutet 'nicht vorhanden' GRA-low fähig (LED immer verbaut).
0 = nicht vorhanden
1 = Wunschgeschwindigkeits-Anzeigemöglichkeit vorhanden
2 = reserviert
3 = Fehler (B";
CM_ SG_ 779 KBI_Oeldruck_Schalter "Das Signal bildet den Status des Öldrucks über den am Kombi angeschlossenen Öldruckschalter ab.";
CM_ SG_ 779 KBI_Tankwarnung "Fahrer wird gewarnt, dass er den Reservebereich erreicht hat. Fzg.spezifische Warnschwelle";
CM_ SG_ 779 KBI_MFA_v_Einheit_01 "Einheit der Geschwindigkeit, die vom Fahrer im Car-Menü gewählt wurde. Veränderliche Grösse, im Gegensatz zur Einheit des Tachokranzes.";
CM_ SG_ 779 KBI_im_Stellgliedtest "Kombi im Stellgliedtest, Signal muss eingelesen werden, um Fehlfunktion aufgrund der Bewegung der Stellglieder (Drehzahlmesser, Tacho) des Kombis zu verhindern";
CM_ SG_ 779 KBI_Oeldruckwarnung "Öldruckwarnung im Kombi aktiv";
CM_ SG_ 779 KBI_Handbremse "Handbremsen-Information vom Kombi.
Das Signal bezieht sich ausschließlich auf den Zustand der konventionellen Handbremse.";
CM_ SG_ 779 KBI_V_Digital "Ausgabe der im Kombi angezeigten digitalen Geschwindigkeit.

Einheit ist im KBI_MFA_v_Einheit_01 definiert";
CM_ SG_ 779 KBI_PLA_in_Anzeige "Das Signal wird als aktive Rückmeldung genutzt, ob die Info des PLA im Kombi angezeigt wird. Wenn nach Anforderung des Displays das Signal zweimal auf 0 ist, wird der Parkvorgang abgebrochen.
Ein Kombi, dass PLA Anzeige nicht unterstützt, schickt dauerha";
CM_ SG_ 779 KBI_Anzeigefehler_NV "Über dieses Signal teilt das Kombiinstrument dem Nightvision-Steuergerät mit, dass ein Fehler vom Kombiinstrument diagnostiziert wurde, der zur Abschaltung der Nightvision-Funktion führen muss.";
CM_ SG_ 779 KBI_Anzeigestatus_LIM "Anzeigestatus der Speedlimiter Wunschgeschwindigkeitsanzeige im Kombiinstrument (permanenter Anzeigebereich)
0 = nicht vorhanden
1 = Wunschgeschwindigkeits-Anzeigemöglichkeit vorhanden
2 = reserviert
3 = Fehler (Botschaftsüberwachung, Timeout, Akustik";
CM_ SG_ 779 KBI_ARA_in_Anzeige "Anzeige von ARA im Kombi aktiv";
CM_ SG_ 779 KBI_angez_Geschw "Im Tacho angezeigte Geschwindigkeit inklusive der Voreilung

";
CM_ SG_ 779 KBI_Einheit_Tacho "Information, ob es sich um Meilen- oder Kmh-Kombi handelt, Einheit des Tachos entspricht dem Zifferblatt, Grösse ist nicht veränderlich";
CM_ SG_ 779 KBI_Konsistenz_ACC "Rückmeldung an ACC, dass die Botschaften zur Ansteuerung von Anzeigen nicht bzw. nicht konsistent empfangen wurden (Timeout-, BZ-, CHK- und DLC-Fehler)                                                                                                        ";
CM_ SG_ 779 KBI_Fehler_Anzeige_ACC "Rückmeldung an ACC, dass mindestens eine der ACC-relevanten Anzeigen -rote Fahrerübernahme, Mitteldisplay, Gong - fehlerhaft sind.";
CM_ SG_ 779 KBI_Anzeigefehler_SWA "Signal bezieht sich nur auf die SWA-Lampe, Vorhalt für Kombis mit SWA-Lampe. ";
CM_ SG_ 1719 KBI_Kilometerstand "Fehler wird ausgegeben, falls Kilometerstand nicht restaurierbar
";
CM_ SG_ 1719 KBI_Standzeit_02 "Zähler welcher die Standzeit des Motors wiedergibt.
Das Signal beschreibt den Anteil der Motor-Standzeit zwischen Zündung aus und nächstem Motorstart.";
CM_ SG_ 1719 KBI_Reserve_Warnung_Sek "Signalisiert die Reservewarnung für die Energiespeicher CNG, LPG, HV-Batterie.
Fahrer wird gewarnt, dass er den Reservebereich erreicht hat. Fzg.spezifische Warnschwelle.";
CM_ SG_ 1719 KBI_RDK_Kalibrier_Anf "Bei gesetztem Bit soll die RDK die aktuellen Istdrücke zu Solldrücken übernehmen (nur bei Nichtverbau einer Headunit erforderlich).";
CM_ SG_ 1719 KBI_Inhalt_Tank "Restmenge 2 bzw. 2,5l nicht auflösbar

";
CM_ SG_ 1719 KBI_FStatus_Tank "Signal wird gesetzt:

a) Während der Fehlerentprellzeit (20 s Entprellung)

b) Bei erkanntem Fehler wird der Tankinhalt während der laufenden KL15-Phase über den 
    Verbrauch zurückgerechnet. In dieser Zeit ist das Bit ebenfalls gesetzt. Nach einem";
CM_ SG_ 1719 KBI_aktive_Laengsfunktion "Auswahl, der vom Fahrer gewünschten Laengsregelfunktion";
CM_ SG_ 1719 KBI_Oelwechsel_durchgefuehrt "Nach einen Ölwechsel (Service) ist die Ethanol Warmfahrwarnung zu unterdrücken.";
CM_ SG_ 1719 KBI_QBit_Aussen_Temp_gef "0x0 = gültiger Wert
0x1 = Ersatz-, Init- oder Fehlerwert";
CM_ SG_ 1720 KBI_Reifenumfang "Mittlerer Radumfang aus der K-Zahl gerechnet in Millimeter.  Byte 2 Bit 5,4 reserviert, Byte 2 Bit 3..0 und Byte 1 Bit 7..0; Wertebereich 0..4096 mm
";
CM_ SG_ 1720 KBI_Variante_USA "In diesem Signal wird die HW-Variante des Kombis ausgegeben, ACC plausibilisiert auf dieses Signal hin seine US-Codierung";
CM_ SG_ 1720 KBI_Variante "Zeigt an ob es sich um ein konventionelles Zeiger-Kombiinstrument handelt oder um eine Volldisplay-Kombiinstrument";
CM_ SG_ 1720 KBI_BCmE_aktiv "Anzeige BCmE aktiv (BCmE-Screen oder Einsparhinweis in der Anzeige)";
CM_ SG_ 1720 KBI_Sparhinweis_quittiert "angezeigter Sparhinweis ist quittiert. Signal wird nach zwei Sendebotschaften wieder auf '0' gesetzt.";
CM_ SG_ 1720 KBI_Tankfuellstand_Prozent "Tankfüllstand in %";
CM_ SG_ 1720 KBI_Nachtanken_erkannt "Statusinformation Nachtankmodus";
CM_ SG_ 1720 KBI_Tankinhalt_hochaufl "angezeigter Tankinhalt hochauflösend zur Restreichweitenberechnung";
CM_ SG_ 1720 KBI_Max_Tankinhalt "Mitteilung des maximalen Tankinhalts an das Reichweitenmodul";
CM_ SG_ 1720 KBI_Reifenumfang_Sekundaer "Fahrzeuge mit unterschiedlichen Reifenumfängen Vorderachse / Hinterachse:

Primärachse: KBI_Reifenumfang
Sekundärachse: KBI_Reifenumfang_Sekundaer
";
CM_ SG_ 2549875031 KS_ACC_Req_Data "Komponentenschutz (Funktion 01h). Request mit NA des Slaves.";
CM_ SG_ 2550006103 KS_ACC_Resp_Data "Komponentenschutz (Funktion 01h). Response mit eigener NA.";
CM_ SG_ 2549875023 KS_Kamera_Req_Data "Komponentenschutz (Funktion 01h). Request mit NA des Slaves.";
CM_ SG_ 2550006095 KS_Kamera_Resp_Data "Komponentenschutz (Funktion 01h). Response mit eigener NA.";
CM_ SG_ 2549875082 KS_SWA_2_Req_Data "Komponentenschutz (Funktion 01h). Request mit NA des Slaves.";
CM_ SG_ 2550006154 KS_SWA_2_Resp_Data "Komponentenschutz (Funktion 01h). Response mit eigener NA.";
CM_ SG_ 2549875022 KS_SWA_Req_Data "Komponentenschutz (Funktion 01h). Request mit NA des Slaves.";
CM_ SG_ 2550006094 KS_SWA_Resp_Data "Komponentenschutz (Funktion 01h). Response mit eigener NA.";
CM_ BO_ 919 "ab MQB ohne CHK/BZ, LDW_SW_Warnung_links/rechts, KD-Fehler und mit Zyklus 100ms";
CM_ SG_ 919 LDW_Gong "Löst ein definiertes akustisches Signal aus.";
CM_ SG_ 919 LDW_Frueh_Spaet "Im MMI eingestellter, aktiver Lenkeingriffszeitpunkt:
0: frueh, frueh aktiv
1: frueh, spaet aktiv
2: spaet, spaet aktiv
3: Fehler";
CM_ SG_ 919 LDW_Texte "Bei Anzeige eines Fehlertextes im Kombi ertönt ein akustisches Signal";
CM_ SG_ 919 LDW_Seite_DLCTLC "Zuordnung auf welche Seite sich LDW_DLC bzw. LDW_TLC beziehen";
CM_ SG_ 919 LDW_Lernmodus "Signal dient zur Ansteuerung von Funktionsanzeigen im Mitteldisplay des Kombiinstruments (neue Funktion im MLB)";
CM_ SG_ 919 LDW_Lernmodus_seitenabhaengig "Signal dient zur Ansteuerung von Funktionsanzeigen im Mitteldisplay des Kombiinstruments für die Seitenabhänige Liniendetektion (neue Funktion ab D4)";
CM_ SG_ 919 LDW_DLC "distance to line, Abstand vom Fahrzeug zur Fahrbahnmarkierung
Der Wert gibt die Breite der Restspur zur Linie wieder (Abstand vom Fahrzeugäußerem zur Linie) (Wert POSITIV wenn Fahrzeug in der Spur - Wert NEGATIV wenn Fahrzeug über der Linie)";
CM_ SG_ 919 LDW_TLC "time to line, Zeit bis das Fahrzeug die Fahrbahnmarkierung überquert";
CM_ SG_ 919 HC_Uss_Anforderung "Ansteuerung der vorderen PLA (VLS, VRS) und APS Sensoren (VL, VR)
0 = Ultraschallsensoren Aus
1 = Ultraschallsensoren An";
CM_ SG_ 919 EA_Warnblinken "Anforderung Warnblinken durch Funktion Emergency Alert";
CM_ SG_ 919 LDW_Codierinfo_fuer_VLR "Vorhalt LDW-Codierinfo";
CM_ SG_ 919 LDW_Status_LED_gruen " ";
CM_ BO_ 159 "C7 und B8

Zykluszeit 10ms zyklisch";
CM_ SG_ 159 EPS_03_CRC "Für MLB:
'Berechnung siehe Lastenheft 'Kommunikationsabsicherung für FlexRay und CAN''

Ab MQB und MLBevo:
'Berechnung siehe Lastenheft 'End-to-End Kommunikationsabsicherung''

Endwerte siehe Begleitdokument 'S-PDU Kennungsfolgen'";
CM_ SG_ 159 EPS_DSR_Status "Interner DSR-Status des EPS-Steuergerätes";
CM_ SG_ 159 EPS_Berechneter_LW "Berechneter Lenkradwinkel (BLW)
MLB: Ausgabe des berechneten Lenkwinkels mit Geradeauslaufkorrektur aus der Position des Lenkmotors (Absolutwert)
MQB: Ausgabe des berechneten Lenkwinkels aus der Position des Lenkmotors (Absolutwert) und ggf. unter Berüc";
CM_ SG_ 159 EPS_BLW_QBit "beschreibt die Qualität/Vertrauenswürdigkeit des berechneten LW";
CM_ SG_ 159 EPS_VZ_BLW "Vorzeichen Berechneter Lenkwinkel

(für EPS_Berechneter_LW)";
CM_ SG_ 159 EPS_HCA_Status "Beschreibt den Status der HCA-Funktion im EPS-Steuergerät.";
CM_ SG_ 159 EPS_Lenkmoment "Gibt das durch den Momentensensor detektiertes Lenkhandmoment (Absolutmoment) aus

Wertebereich von 0x321 - 0x3FD reserviert (z.Zt. nicht bedient)";
CM_ SG_ 159 EPS_VZ_Lenkmoment "Vorzeichen Lenkhandmoment";
CM_ SG_ 159 EPS_Lenkungstyp "Signal beschreibt den eingebauten Lenkungstyp. Enthält z. B. implizit auch die Information, welche Ritzelübersetzung verbaut ist. Wichtig für die Regelsysteme HCA und DSR.
Im MQB gilt das 'EPS LH CAN-Schnittstelle'.";
CM_ SG_ 981 Licht_Anf_01_CRC "Für MLB:
'Berechnung siehe Lastenheft 'Kommunikationsabsicherung für FlexRay und CAN''

Ab MQB und MLBevo:
'Berechnung siehe Lastenheft 'End-to-End Kommunikationsabsicherung''

Endwerte siehe Begleitdokument 'S-PDU Kennungsfolgen'";
CM_ SG_ 981 Licht_Anf_01_BZ "4bit Botschaftszaehler, wird mit jeder Sendebotschaft inkrementiert";
CM_ SG_ 981 BCM1_Kurvenlicht_links_Anf "Ansteuerung linkes Kurvenlicht/Abbiegelicht duch BCM1";
CM_ SG_ 981 BCM1_Kurvenlicht_rechts_Anf "Ansteuerung rechtes Kurvenlicht/Abbiegelicht duch BCM1";
CM_ SG_ 981 BCM1_Standlicht_Anf "Anforderung: Schlusslicht (Sollzustand)";
CM_ SG_ 981 BCM1_Abblendlicht_Anf "Anforderung Abblendlicht
";
CM_ SG_ 981 BCM1_Fernlicht_Anf "Anforderung Fernlicht
";
CM_ SG_ 981 BCM1_Nebellicht_Anf "Anforderung Nebellicht
";
CM_ SG_ 981 BCM1_Parklicht_li_Anf "Anforderung: Parklicht links (Sollzustand)
";
CM_ SG_ 981 BCM1_Parklicht_re_Anf "Anforderung: Parklicht rechts (Sollzustand)
";
CM_ SG_ 981 BCM1_Nebelschluss_Ahg_Anf "Anforderung: Nebelschlusslicht Anhänger (Sollzustand)
";
CM_ SG_ 981 BCM1_Nebelschluss_Fzg_Anf "Anforderung: Nebelschlusslicht Fahrzeug (Sollzustand)
";
CM_ SG_ 981 BCM1_Schlusslicht_Anf "Anforderung: Schlusslicht Fahrzeug (Sollzustand)
";
CM_ SG_ 981 BCM_Rueckfahrlicht_Anf "Anforderung Rückfahrlicht (Sollzustand). 
Das Signal wird entprellt (typisch 400ms) und bei KL15EIN gesendet. Das Signal ist unabhängig von der Position des Heckdeckels (kein Überhitzungsschutz).";
CM_ SG_ 981 BCM1_Signaturlicht_Anf "Signal zur Anforderung des Signaturlichts";
CM_ SG_ 981 BCM1_Umfeldleuchten_Anf "Anforderung für Umfeldleuchten";
CM_ SG_ 981 BCM1_Tagfahrlicht_Anf "Anforderung: Tagfahrlicht (Sollzustand)";
CM_ SG_ 981 BCM1_Regenlicht_Anf "Anforderung: Regenlicht (Sollzustand)
";
CM_ SG_ 981 BCM1_Autobahnlicht_Anf "Anforderung Autobahnlicht
";
CM_ SG_ 981 BCM1_Touristen_Licht_Anf "Anforderung: Touristenlicht (Sollzustand)";
CM_ SG_ 981 BCM1_CH_aktiv "Coming Home (zusätzlich zum Signal 'BCM1_CH_LH_aktiv' in der Botschaft BCM1_01)";
CM_ SG_ 981 BCM1_LH_aktiv "Leaving Home (zusätzlich zum Signal 'BCM1_CH_LH_aktiv' in der Botschaft BCM1_01)";
CM_ SG_ 981 BCM1_Gleitende_Leuchtw_Anf "Funktion 'Gleitende Leuchtweite' im AFS-SG  freischalten";
CM_ SG_ 981 BCM1_GLW_Fernlicht_Anf "Harte Fernlichtanforderung von BCM1 an die Funktion 'gleitende Leuchtweite' im AFS-SG";
CM_ SG_ 981 BCM1_Adaptive_Lichtvert_Anf "Funktion 'Adaptive Lichtverteilung' im AFS-SG  Ein- und Ausschalten";
CM_ SG_ 981 BCM1_CH_LH_aktiv "Status Comming / Leaving Home
";
CM_ SG_ 981 BCM1_Allwetterlicht_Anf "Anforderung eines Allwetterlichts (über AFS-SG realisiert): Licht für schlechte Sichtverhältnisse";
CM_ SG_ 1624 LV_Standlicht_Anzeige "Anzeige Standlicht
";
CM_ SG_ 1624 LV_Abblendlicht_Anzeige "Abblendlicht aktiv";
CM_ SG_ 1624 LV_Fernlicht_Anzeige "Fernlicht_aktiv";
CM_ SG_ 1624 LV_Nebellicht_Anzeige "Nebellicht_aktiv
";
CM_ SG_ 1624 LV_Nebelschlusslicht_Anzeige "Nebelschlusslicht_aktiv
";
CM_ SG_ 1624 LV_Tagfahrlicht_Anzeige "Anzeige Tagfahrlicht
";
CM_ SG_ 1624 LV_AFL_aktiv_Anzeige "Anzeige AFL-Funktion";
CM_ SG_ 1624 LV_AFL_defekt "Fehlerstatus AFL
";
CM_ SG_ 1624 LV_Blinker_li_def "Fehlerstatus Blinker vorne links
";
CM_ SG_ 1624 LV_Standlicht_li_def "Fehlerstatus Standlicht vorne links
";
CM_ SG_ 1624 LV_Abblendlicht_li_def "Fehlerstatus Abblendlicht vorne links 
";
CM_ SG_ 1624 LV_Fernlicht_li_def "Fehlerstatus Fernlicht vorne links
";
CM_ SG_ 1624 LV_Nebellicht_li_def "Fehlerstatus Nebelscheinwerfer vorne links
";
CM_ SG_ 1624 LV_Blk_li_Seite_def "Fehlerstatus Seitenblinker links
";
CM_ SG_ 1624 LV_Tagfahrlicht_li_def "Fehlerstatus Tagfahrlicht links
";
CM_ SG_ 1624 LV_FLA_aktiv_Anzeige "Ansteuerung FLA-Lampe im Kombi (BCM1 Bedienmaster)";
CM_ SG_ 1624 LV_FLA_defekt "Fehlerstatus FLA (Anzeige des entsprechenden Fehlertext im Kombi)";
CM_ SG_ 1624 LV_FLA_Sensor_blockiert "Status FLA-Sensor (Anzeige des entsprechenden Fehlertext im Kombi)";
CM_ SG_ 1624 LV_Blinker_re_def "Fehlerstatus Blinker vorne rechts
";
CM_ SG_ 1624 LV_Standlicht_re_def "Fehlerstatus Standlicht vorne rechts
";
CM_ SG_ 1624 LV_Abblendlicht_re_def "Fehlerstatus Abblendlicht vorne rechts
";
CM_ SG_ 1624 LV_Fernlicht_re_def "Fehlerstatus Fernlicht vorne rechts
";
CM_ SG_ 1624 LV_Nebellicht_re_def "Fehlerstatus Nebelscheinwerfer vorne rechts
";
CM_ SG_ 1624 LV_Blk_re_Seite_def "Fehlerstatus Blinker Seite rechts
";
CM_ SG_ 1624 LV_Tagfahrlicht_re_def "Fehlerstatus Tagfahrlicht rechts";
CM_ SG_ 1624 LV_Aussenlicht_def "Aussenlicht kann nicht mehr korrekt angesteuert werden (EEPROM Codierung kann nicht mehr ausgelesen werden)
";
CM_ SG_ 1624 LV_Abblendlicht_TFL_li_def "Fehlerstatus Abblendlicht und Tagfahrlicht links
";
CM_ SG_ 1624 LV_Nebellicht_TFL_li_def "Fehlerstatus Nebellicht und Tagfahrlicht links ";
CM_ SG_ 1624 LV_Standlicht_TFL_li_def "Fehlerstatus Standlicht und Tagfahrlicht links ";
CM_ SG_ 1624 LV_Abblend_Fernlicht_li_def "Fehlerstatus Abblendlicht und Fernlicht links ";
CM_ SG_ 1624 LV_Abblendlicht_TFL_re_def "Fehlerstatus Abblendlicht und Tagfahrlicht rechts ";
CM_ SG_ 1624 LV_Nebellicht_TFL_re_def "Fehlerstatus Nebellicht und Tagfahrlicht rechts";
CM_ SG_ 1624 LV_Standlicht_TFL_re_def "Fehlerstatus Standlicht und Tagfahrlicht rechts ";
CM_ SG_ 1624 LV_Abblend_Fernlicht_re_def "Fehlerstatus Abblendlicht und Fernlicht rechts";
CM_ SG_ 1624 LV_Abbiegelicht_li_def "Fehlerstatus Abbiegelicht vorne links
";
CM_ SG_ 1624 LV_Abbiegelicht_re_def "Fehlerstatus Abbiegelicht vorne rechts
";
CM_ SG_ 1624 BCM1_Linksverkehr "Information über Aufbauzustand des Fzg:
0 = Scheinwerfer für Rechtsverkehr
1 = Scheinwerfer für Linksverkehr";
CM_ SG_ 1624 BCM1_Licht_Dunkelheit_aktiv "Licht aktiv aufgrund von Dunkelheit (nicht bei Autobahn-, Tagfahr- oder Regenlicht)
";
CM_ SG_ 1624 LV_LED_Scheinwerfer_li_def "Fehlerstatus LED-Scheinwerfer links
";
CM_ SG_ 1624 LV_LED_Scheinwerfer_re_def "Fehlerstatus LED-Scheinwerfer rechts";
CM_ SG_ 1624 LV_Blinker_VL_aktiv "Blinker vorne links
";
CM_ SG_ 1624 LV_Blinker_VR_aktiv "Blinker vorne links
";
BA_DEF_ BO_  "DiagRequest" ENUM  "No","Yes";
BA_DEF_ BO_  "DiagResponse" ENUM  "No","Yes";
BA_DEF_ BO_  "DiagState" ENUM  "No","Yes";
BA_DEF_ BO_  "GenMsgChkConstant" HEX 0 4095;
BA_DEF_ BO_  "GenMsgCycleTime" INT 0 65535;
BA_DEF_ BO_  "GenMsgCycleTimeFast" INT 0 65535;
BA_DEF_ BO_  "GenMsgDelayTime" INT 0 100000;
BA_DEF_ BO_  "GenMsgILSupport" ENUM  "No","Yes";
BA_DEF_ BO_  "GenMsgNrOfRepetition" INT 0 100;
BA_DEF_ BO_  "GenMsgPDUConstants" STRING ;
BA_DEF_ BO_  "GenMsgSendType" ENUM  "Cyclic","not_used","not_used","not_used","not_used","not_used","not_used","IfActive","NoMsgSendType";
BA_DEF_ BO_  "GenMsgStartDelayTime" INT 0 100000;
BA_DEF_ BO_  "NmMessage" ENUM  "No","Yes";
BA_DEF_ BO_  "NmhMessage" ENUM  "No","Yes";
BA_DEF_ BO_  "MsgType" ENUM  "Application","NM ","NMH","TP2.0","ISO-TP ","BAP","EID","KS";
BA_DEF_ BO_  "VAGTP20_API" HEX 0 255;
BA_DEF_ BO_  "VAGTP20_DynConnection" ENUM  "No","Yes";
BA_DEF_ BO_  "VAGTP20_DynSetup" ENUM  "No","Yes";
BA_DEF_ BO_  "VAGTP20_StatConnection" ENUM  "No","Yes";
BA_DEF_ SG_  "GenSigActiveRepetitions" INT -2147483648 2147483647;
BA_DEF_ SG_  "GenSigInactiveValue" INT -2147483648 2147483647;
BA_DEF_ SG_  "GenSigSendType" ENUM  "Cyclic","OnWrite","OnWriteWithRepetition","OnChange","OnChangeWithRepetition","IfActive","IfActiveWithRepetition","NoSigSendType","OnChangeAndIfActive","OnChangeAndIfActiveWithRepetition";
BA_DEF_ SG_  "GenSigStartValue" INT -2147483648 2147483647;
BA_DEF_ SG_  "NWM-WakeupAllowed" ENUM  "No","Yes";
BA_DEF_ SG_  "GenSigFuncType" ENUM  "NoFunction","MsgCounter","CRC-8","XOR","XOR-2","DatedBit","SW-Kl15","CHK","Constant","Protocol","CRC-8-SAE_J1850";
BA_DEF_ SG_  "GenSigSwitchedByIgnition" ENUM  "No","Yes";
BA_DEF_ SG_  "Fehlerwert" HEX 0 2147483647;
BA_DEF_ SG_  "GenSigMissingSourceValue" HEX 0 2147483647;
BA_DEF_REL_ BU_SG_REL_  "GenSigTimeoutTime" INT 0 65535;
BA_DEF_DEF_REL_ "GenSigTimeoutTime" 0;
BA_DEF_DEF_  "DiagRequest" "No";
BA_DEF_DEF_  "DiagResponse" "No";
BA_DEF_DEF_  "DiagState" "No";
BA_DEF_DEF_  "GenMsgChkConstant" 0;
BA_DEF_DEF_  "GenMsgCycleTime" 0;
BA_DEF_DEF_  "GenMsgCycleTimeFast" 0;
BA_DEF_DEF_  "GenMsgDelayTime" 0;
BA_DEF_DEF_  "GenMsgILSupport" "No";
BA_DEF_DEF_  "GenMsgNrOfRepetition" 0;
BA_DEF_DEF_  "GenMsgPDUConstants" "";
BA_DEF_DEF_  "GenMsgSendType" "NoMsgSendType";
BA_DEF_DEF_  "GenMsgStartDelayTime" 0;
BA_DEF_DEF_  "NmMessage" "No";
BA_DEF_DEF_  "NmhMessage" "No";
BA_DEF_DEF_  "MsgType" "Application";
BA_DEF_DEF_  "VAGTP20_API" 0;
BA_DEF_DEF_  "VAGTP20_DynConnection" "No";
BA_DEF_DEF_  "VAGTP20_DynSetup" "No";
BA_DEF_DEF_  "VAGTP20_StatConnection" "No";
BA_DEF_DEF_  "GenSigActiveRepetitions" 0;
BA_DEF_DEF_  "GenSigInactiveValue" 0;
BA_DEF_DEF_  "GenSigSendType" "NoSigSendType";
BA_DEF_DEF_  "GenSigStartValue" 0;
BA_DEF_DEF_  "NWM-WakeupAllowed" "No";
BA_DEF_DEF_  "GenSigFuncType" "NoFunction";
BA_DEF_DEF_  "GenSigSwitchedByIgnition" "Yes";
BA_DEF_DEF_  "Fehlerwert" 0;
BA_DEF_DEF_  "GenSigMissingSourceValue" 0;
BA_ "MsgType" BO_ 1801 4;
BA_ "DiagState" BO_ 1801 1;
BA_ "MsgType" BO_ 1795 4;
BA_ "DiagState" BO_ 1795 1;
BA_ "MsgType" BO_ 1792 4;
BA_ "DiagState" BO_ 1792 1;
BA_ "MsgType" BO_ 2015 4;
BA_ "DiagState" BO_ 2015 1;
BA_ "MsgType" BO_ 1871 4;
BA_ "DiagRequest" BO_ 1871 1;
BA_ "MsgType" BO_ 1977 4;
BA_ "DiagResponse" BO_ 1977 1;
BA_ "MsgType" BO_ 1876 4;
BA_ "DiagRequest" BO_ 1876 1;
BA_ "MsgType" BO_ 1982 4;
BA_ "DiagResponse" BO_ 1982 1;
BA_ "MsgType" BO_ 1870 4;
BA_ "DiagRequest" BO_ 1870 1;
BA_ "MsgType" BO_ 1976 4;
BA_ "DiagResponse" BO_ 1976 1;
BA_ "GenMsgSendType" BO_ 791 0;
BA_ "GenMsgILSupport" BO_ 791 1;
BA_ "GenMsgCycleTime" BO_ 791 40;
BA_ "GenMsgSendType" BO_ 799 0;
BA_ "GenMsgPDUConstants" BO_ 799 "0x1c,0x1c,0x1c,0x1c,0x1c,0x1c,0x1c,0x1c,0x1c,0x1c,0x1c,0x1c,0x1c,0x1c,0x1c,0x1c";
BA_ "GenMsgILSupport" BO_ 799 1;
BA_ "GenMsgCycleTime" BO_ 799 40;
BA_ "GenMsgChkConstant" BO_ 799 28;
BA_ "GenMsgSendType" BO_ 838 0;
BA_ "GenMsgPDUConstants" BO_ 838 "0x23,0x23,0x23,0x23,0x23,0x23,0x23,0x23,0x23,0x23,0x23,0x23,0x23,0x23,0x23,0x23";
BA_ "GenMsgILSupport" BO_ 838 1;
BA_ "GenMsgCycleTime" BO_ 838 40;
BA_ "GenMsgChkConstant" BO_ 838 35;
BA_ "GenMsgSendType" BO_ 839 0;
BA_ "GenMsgPDUConstants" BO_ 839 "0x22,0x22,0x22,0x22,0x22,0x22,0x22,0x22,0x22,0x22,0x22,0x22,0x22,0x22,0x22,0x22";
BA_ "GenMsgILSupport" BO_ 839 1;
BA_ "GenMsgCycleTime" BO_ 839 40;
BA_ "GenMsgChkConstant" BO_ 839 34;
BA_ "GenMsgSendType" BO_ 840 0;
BA_ "GenMsgILSupport" BO_ 840 1;
BA_ "GenMsgCycleTime" BO_ 840 40;
BA_ "GenMsgSendType" BO_ 841 0;
BA_ "GenMsgILSupport" BO_ 841 1;
BA_ "GenMsgCycleTime" BO_ 841 40;
BA_ "GenMsgSendType" BO_ 842 0;
BA_ "GenMsgILSupport" BO_ 842 1;
BA_ "GenMsgCycleTime" BO_ 842 40;
BA_ "GenMsgSendType" BO_ 843 0;
BA_ "GenMsgILSupport" BO_ 843 1;
BA_ "GenMsgCycleTime" BO_ 843 40;
BA_ "GenMsgSendType" BO_ 844 0;
BA_ "GenMsgILSupport" BO_ 844 1;
BA_ "GenMsgCycleTime" BO_ 844 40;
BA_ "GenMsgSendType" BO_ 845 0;
BA_ "GenMsgILSupport" BO_ 845 1;
BA_ "GenMsgCycleTime" BO_ 845 40;
BA_ "GenMsgSendType" BO_ 792 0;
BA_ "GenMsgILSupport" BO_ 792 1;
BA_ "GenMsgCycleTime" BO_ 792 80;
BA_ "GenMsgSendType" BO_ 960 0;
BA_ "GenMsgPDUConstants" BO_ 960 "0xc3,0xc3,0xc3,0xc3,0xc3,0xc3,0xc3,0xc3,0xc3,0xc3,0xc3,0xc3,0xc3,0xc3,0xc3,0xc3";
BA_ "GenMsgILSupport" BO_ 960 1;
BA_ "GenMsgDelayTime" BO_ 960 10;
BA_ "GenMsgCycleTime" BO_ 960 100;
BA_ "GenMsgChkConstant" BO_ 960 195;
BA_ "GenMsgSendType" BO_ 1646 0;
BA_ "GenMsgILSupport" BO_ 1646 1;
BA_ "GenMsgDelayTime" BO_ 1646 200;
BA_ "GenMsgCycleTime" BO_ 1646 2000;
BA_ "GenMsgSendType" BO_ 949 0;
BA_ "GenMsgILSupport" BO_ 949 1;
BA_ "GenMsgCycleTime" BO_ 949 100;
BA_ "GenMsgSendType" BO_ 1511 0;
BA_ "GenMsgILSupport" BO_ 1511 1;
BA_ "GenMsgCycleTime" BO_ 1511 500;
BA_ "GenMsgSendType" BO_ 1514 0;
BA_ "GenMsgILSupport" BO_ 1514 1;
BA_ "GenMsgCycleTime" BO_ 1514 500;
BA_ "GenMsgSendType" BO_ 1515 0;
BA_ "GenMsgILSupport" BO_ 1515 1;
BA_ "GenMsgCycleTime" BO_ 1515 500;
BA_ "GenMsgSendType" BO_ 1712 0;
BA_ "GenMsgILSupport" BO_ 1712 1;
BA_ "GenMsgCycleTime" BO_ 1712 500;
BA_ "GenMsgSendType" BO_ 1717 0;
BA_ "GenMsgILSupport" BO_ 1717 1;
BA_ "GenMsgCycleTime" BO_ 1717 500;
BA_ "GenMsgSendType" BO_ 2549088343 0;
BA_ "GenMsgILSupport" BO_ 2549088343 1;
BA_ "GenMsgCycleTime" BO_ 2549088343 500;
BA_ "GenMsgSendType" BO_ 2549088304 0;
BA_ "GenMsgILSupport" BO_ 2549088304 1;
BA_ "GenMsgCycleTime" BO_ 2549088304 500;
BA_ "GenMsgSendType" BO_ 2549088335 0;
BA_ "GenMsgILSupport" BO_ 2549088335 1;
BA_ "GenMsgCycleTime" BO_ 2549088335 500;
BA_ "GenMsgSendType" BO_ 2549088340 0;
BA_ "GenMsgILSupport" BO_ 2549088340 1;
BA_ "GenMsgCycleTime" BO_ 2549088340 500;
BA_ "GenMsgSendType" BO_ 2549088334 0;
BA_ "GenMsgILSupport" BO_ 2549088334 1;
BA_ "GenMsgCycleTime" BO_ 2549088334 500;
BA_ "GenMsgSendType" BO_ 779 0;
BA_ "GenMsgILSupport" BO_ 779 1;
BA_ "GenMsgCycleTime" BO_ 779 50;
BA_ "GenMsgSendType" BO_ 1719 0;
BA_ "GenMsgILSupport" BO_ 1719 1;
BA_ "GenMsgDelayTime" BO_ 1719 100;
BA_ "GenMsgCycleTime" BO_ 1719 1000;
BA_ "GenMsgSendType" BO_ 1720 0;
BA_ "GenMsgILSupport" BO_ 1720 1;
BA_ "GenMsgCycleTime" BO_ 1720 1000;
BA_ "MsgType" BO_ 2549875031 4;
BA_ "MsgType" BO_ 2550006103 4;
BA_ "MsgType" BO_ 2549875023 4;
BA_ "MsgType" BO_ 2550006095 4;
BA_ "MsgType" BO_ 2549875082 4;
BA_ "MsgType" BO_ 2550006154 4;
BA_ "MsgType" BO_ 2549875022 4;
BA_ "MsgType" BO_ 2550006094 4;
BA_ "GenMsgSendType" BO_ 919 0;
BA_ "GenMsgILSupport" BO_ 919 1;
BA_ "GenMsgDelayTime" BO_ 919 20;
BA_ "GenMsgCycleTime" BO_ 919 100;
BA_ "GenMsgSendType" BO_ 159 0;
BA_ "GenMsgPDUConstants" BO_ 159 "0xf5,0xf5,0xf5,0xf5,0xf5,0xf5,0xf5,0xf5,0xf5,0xf5,0xf5,0xf5,0xf5,0xf5,0xf5,0xf5";
BA_ "GenMsgILSupport" BO_ 159 1;
BA_ "GenMsgCycleTime" BO_ 159 10;
BA_ "GenMsgChkConstant" BO_ 159 245;
BA_ "GenMsgSendType" BO_ 981 0;
BA_ "GenMsgPDUConstants" BO_ 981 "0xc5,0x39,0xc7,0xf9,0x92,0xd8,0x24,0xce,0xf1,0xb5,0x7a,0xc4,0xbc,0x60,0xe3,0xd1";
BA_ "GenMsgILSupport" BO_ 981 1;
BA_ "GenMsgCycleTime" BO_ 981 100;
BA_ "GenMsgSendType" BO_ 1624 0;
BA_ "GenMsgPDUConstants" BO_ 1624 "0x46,0x0f,0xe0,0xcc,0xbe,0xb1,0xd7,0xf1,0x1f,0x31,0xc1,0x25,0xb4,0x3e,0xc8,0xa3";
BA_ "GenMsgILSupport" BO_ 1624 1;
BA_ "GenMsgDelayTime" BO_ 1624 50;
BA_ "GenMsgCycleTime" BO_ 1624 1000;
BA_ "GenSigSwitchedByIgnition" SG_ 1801 ISO_09_Req_Data 0;
BA_ "GenSigFuncType" SG_ 1801 ISO_09_Req_Data 9;
BA_ "GenSigSendType" SG_ 1801 ISO_09_Req_Data 3;
BA_ "GenSigSwitchedByIgnition" SG_ 1795 ISO_Funktionaler_Req_Abgas 0;
BA_ "GenSigFuncType" SG_ 1795 ISO_Funktionaler_Req_Abgas 9;
BA_ "GenSigSendType" SG_ 1795 ISO_Funktionaler_Req_Abgas 3;
BA_ "GenSigSwitchedByIgnition" SG_ 1792 ISO_ALL_01_Req_Data 0;
BA_ "GenSigFuncType" SG_ 1792 ISO_ALL_01_Req_Data 9;
BA_ "GenSigSendType" SG_ 1792 ISO_ALL_01_Req_Data 3;
BA_ "GenSigSwitchedByIgnition" SG_ 2015 ISO_OBD_Funktionaler_Req_Data 0;
BA_ "GenSigFuncType" SG_ 2015 ISO_OBD_Funktionaler_Req_Data 9;
BA_ "GenSigSendType" SG_ 2015 ISO_OBD_Funktionaler_Req_Data 3;
BA_ "GenSigSwitchedByIgnition" SG_ 1871 ISO_Kamera_Req_Data 0;
BA_ "GenSigFuncType" SG_ 1871 ISO_Kamera_Req_Data 9;
BA_ "GenSigSendType" SG_ 1871 ISO_Kamera_Req_Data 3;
BA_ "GenSigFuncType" SG_ 1977 ISO_Kamera_Resp_Data 9;
BA_ "GenSigSendType" SG_ 1977 ISO_Kamera_Resp_Data 3;
BA_ "GenSigSwitchedByIgnition" SG_ 1876 ISO_LWRAFS_Req_Data 0;
BA_ "GenSigFuncType" SG_ 1876 ISO_LWRAFS_Req_Data 9;
BA_ "GenSigSendType" SG_ 1876 ISO_LWRAFS_Req_Data 3;
BA_ "GenSigFuncType" SG_ 1982 ISO_LWRAFS_Resp_Data 9;
BA_ "GenSigSendType" SG_ 1982 ISO_LWRAFS_Resp_Data 3;
BA_ "GenSigSwitchedByIgnition" SG_ 1870 ISO_SWA_Req_Data 0;
BA_ "GenSigFuncType" SG_ 1870 ISO_SWA_Req_Data 9;
BA_ "GenSigSendType" SG_ 1870 ISO_SWA_Req_Data 3;
BA_ "GenSigFuncType" SG_ 1976 ISO_SWA_Resp_Data 9;
BA_ "GenSigSendType" SG_ 1976 ISO_SWA_Resp_Data 3;
BA_ "GenSigStartValue" SG_ 791 Kamera_FDD_Obj01_ID 254;
BA_ "GenSigSendType" SG_ 791 Kamera_FDD_Obj01_ID 0;
BA_ "GenSigSendType" SG_ 791 Kamera_FDD_Obj01_Entf_Nah 0;
BA_ "GenSigStartValue" SG_ 791 Kamera_FDD_Obj01_Typ 14;
BA_ "GenSigSendType" SG_ 791 Kamera_FDD_Obj01_Typ 0;
BA_ "GenSigStartValue" SG_ 791 Kamera_FDD_Obj01_horizPos 1022;
BA_ "GenSigSendType" SG_ 791 Kamera_FDD_Obj01_horizPos 0;
BA_ "GenSigStartValue" SG_ 791 Kamera_FDD_Obj01_MehrAlsAchtObj 2;
BA_ "GenSigSendType" SG_ 791 Kamera_FDD_Obj01_MehrAlsAchtObj 0;
BA_ "GenSigStartValue" SG_ 791 Kamera_FDD_Obj01_Ersatzw 2;
BA_ "GenSigSendType" SG_ 791 Kamera_FDD_Obj01_Ersatzw 0;
BA_ "GenSigStartValue" SG_ 791 Kamera_FDD_Obj01_horizDim 1022;
BA_ "GenSigSendType" SG_ 791 Kamera_FDD_Obj01_horizDim 0;
BA_ "GenSigStartValue" SG_ 791 Kamera_FDD_Obj01_vertPos 1022;
BA_ "GenSigSendType" SG_ 791 Kamera_FDD_Obj01_vertPos 0;
BA_ "GenSigSendType" SG_ 791 Kamera_FDD_Obj01_horizGuete_li 0;
BA_ "GenSigSendType" SG_ 791 Kamera_FDD_Obj01_horizGuete_re 0;
BA_ "GenSigStartValue" SG_ 791 Kamera_FDD_Obj01_Entfernung 14;
BA_ "GenSigSendType" SG_ 791 Kamera_FDD_Obj01_Entfernung 0;
BA_ "GenSigSendType" SG_ 791 Kamera_FDD_Obj01_Objguete 0;
BA_ "GenSigStartValue" SG_ 799 Kamera_FDD_Obj02_ID 254;
BA_ "GenSigSendType" SG_ 799 Kamera_FDD_Obj02_ID 0;
BA_ "GenSigSendType" SG_ 799 Kamera_FDD_Obj02_Entf_Nah 0;
BA_ "GenSigStartValue" SG_ 799 Kamera_FDD_Obj02_Typ 14;
BA_ "GenSigSendType" SG_ 799 Kamera_FDD_Obj02_Typ 0;
BA_ "GenSigStartValue" SG_ 799 Kamera_FDD_Obj02_horizPos 1022;
BA_ "GenSigSendType" SG_ 799 Kamera_FDD_Obj02_horizPos 0;
BA_ "GenSigStartValue" SG_ 799 Kamera_FDD_Obj02_Ersatzw 2;
BA_ "GenSigSendType" SG_ 799 Kamera_FDD_Obj02_Ersatzw 0;
BA_ "GenSigStartValue" SG_ 799 Kamera_FDD_Obj02_horizDim 1022;
BA_ "GenSigSendType" SG_ 799 Kamera_FDD_Obj02_horizDim 0;
BA_ "GenSigStartValue" SG_ 799 Kamera_FDD_Obj02_vertPos 1022;
BA_ "GenSigSendType" SG_ 799 Kamera_FDD_Obj02_vertPos 0;
BA_ "GenSigSendType" SG_ 799 Kamera_FDD_Obj02_horizGuete_li 0;
BA_ "GenSigSendType" SG_ 799 Kamera_FDD_Obj02_horizGuete_re 0;
BA_ "GenSigStartValue" SG_ 799 Kamera_FDD_Obj02_Entfernung 14;
BA_ "GenSigSendType" SG_ 799 Kamera_FDD_Obj02_Entfernung 0;
BA_ "GenSigSendType" SG_ 799 Kamera_FDD_Obj02_Objguete 0;
BA_ "GenSigStartValue" SG_ 838 Kamera_FDD_Obj03_ID 254;
BA_ "GenSigSendType" SG_ 838 Kamera_FDD_Obj03_ID 0;
BA_ "GenSigSendType" SG_ 838 Kamera_FDD_Obj03_Entf_Nah 0;
BA_ "GenSigStartValue" SG_ 838 Kamera_FDD_Obj03_Typ 14;
BA_ "GenSigSendType" SG_ 838 Kamera_FDD_Obj03_Typ 0;
BA_ "GenSigStartValue" SG_ 838 Kamera_FDD_Obj03_horizPos 1022;
BA_ "GenSigSendType" SG_ 838 Kamera_FDD_Obj03_horizPos 0;
BA_ "GenSigStartValue" SG_ 838 Kamera_FDD_Obj03_Ersatzw 2;
BA_ "GenSigSendType" SG_ 838 Kamera_FDD_Obj03_Ersatzw 0;
BA_ "GenSigStartValue" SG_ 838 Kamera_FDD_Obj03_horizDim 1022;
BA_ "GenSigSendType" SG_ 838 Kamera_FDD_Obj03_horizDim 0;
BA_ "GenSigStartValue" SG_ 838 Kamera_FDD_Obj03_vertPos 1022;
BA_ "GenSigSendType" SG_ 838 Kamera_FDD_Obj03_vertPos 0;
BA_ "GenSigSendType" SG_ 838 Kamera_FDD_Obj03_horizGuete_li 0;
BA_ "GenSigSendType" SG_ 838 Kamera_FDD_Obj03_horizGuete_re 0;
BA_ "GenSigStartValue" SG_ 838 Kamera_FDD_Obj03_Entfernung 14;
BA_ "GenSigSendType" SG_ 838 Kamera_FDD_Obj03_Entfernung 0;
BA_ "GenSigSendType" SG_ 838 Kamera_FDD_Obj03_Objguete 0;
BA_ "GenSigStartValue" SG_ 839 Kamera_FDD_Obj04_ID 254;
BA_ "GenSigSendType" SG_ 839 Kamera_FDD_Obj04_ID 0;
BA_ "GenSigSendType" SG_ 839 Kamera_FDD_Obj04_Entf_Nah 0;
BA_ "GenSigStartValue" SG_ 839 Kamera_FDD_Obj04_Typ 14;
BA_ "GenSigSendType" SG_ 839 Kamera_FDD_Obj04_Typ 0;
BA_ "GenSigStartValue" SG_ 839 Kamera_FDD_Obj04_horizPos 1022;
BA_ "GenSigSendType" SG_ 839 Kamera_FDD_Obj04_horizPos 0;
BA_ "GenSigStartValue" SG_ 839 Kamera_FDD_Obj04_Ersatzw 2;
BA_ "GenSigSendType" SG_ 839 Kamera_FDD_Obj04_Ersatzw 0;
BA_ "GenSigStartValue" SG_ 839 Kamera_FDD_Obj04_horizDim 1022;
BA_ "GenSigSendType" SG_ 839 Kamera_FDD_Obj04_horizDim 0;
BA_ "GenSigStartValue" SG_ 839 Kamera_FDD_Obj04_vertPos 1022;
BA_ "GenSigSendType" SG_ 839 Kamera_FDD_Obj04_vertPos 0;
BA_ "GenSigSendType" SG_ 839 Kamera_FDD_Obj04_horizGuete_li 0;
BA_ "GenSigSendType" SG_ 839 Kamera_FDD_Obj04_horizGuete_re 0;
BA_ "GenSigStartValue" SG_ 839 Kamera_FDD_Obj04_Entfernung 14;
BA_ "GenSigSendType" SG_ 839 Kamera_FDD_Obj04_Entfernung 0;
BA_ "GenSigSendType" SG_ 839 Kamera_FDD_Obj04_Objguete 0;
BA_ "GenSigStartValue" SG_ 840 Kamera_FDD_Obj05_ID 254;
BA_ "GenSigSendType" SG_ 840 Kamera_FDD_Obj05_ID 0;
BA_ "GenSigSendType" SG_ 840 Kamera_FDD_Obj05_Entf_Nah 0;
BA_ "GenSigStartValue" SG_ 840 Kamera_FDD_Obj05_Typ 14;
BA_ "GenSigSendType" SG_ 840 Kamera_FDD_Obj05_Typ 0;
BA_ "GenSigStartValue" SG_ 840 Kamera_FDD_Obj05_horizPos 1022;
BA_ "GenSigSendType" SG_ 840 Kamera_FDD_Obj05_horizPos 0;
BA_ "GenSigStartValue" SG_ 840 Kamera_FDD_Obj05_Ersatzw 2;
BA_ "GenSigSendType" SG_ 840 Kamera_FDD_Obj05_Ersatzw 0;
BA_ "GenSigStartValue" SG_ 840 Kamera_FDD_Obj05_horizDim 1022;
BA_ "GenSigSendType" SG_ 840 Kamera_FDD_Obj05_horizDim 0;
BA_ "GenSigStartValue" SG_ 840 Kamera_FDD_Obj05_vertPos 1022;
BA_ "GenSigSendType" SG_ 840 Kamera_FDD_Obj05_vertPos 0;
BA_ "GenSigSendType" SG_ 840 Kamera_FDD_Obj05_horizGuete_li 0;
BA_ "GenSigSendType" SG_ 840 Kamera_FDD_Obj05_horizGuete_re 0;
BA_ "GenSigStartValue" SG_ 840 Kamera_FDD_Obj05_Entfernung 14;
BA_ "GenSigSendType" SG_ 840 Kamera_FDD_Obj05_Entfernung 0;
BA_ "GenSigSendType" SG_ 840 Kamera_FDD_Obj05_Objguete 0;
BA_ "GenSigStartValue" SG_ 841 Kamera_FDD_Obj06_ID 254;
BA_ "GenSigSendType" SG_ 841 Kamera_FDD_Obj06_ID 0;
BA_ "GenSigSendType" SG_ 841 Kamera_FDD_Obj06_Entf_Nah 0;
BA_ "GenSigStartValue" SG_ 841 Kamera_FDD_Obj06_Typ 14;
BA_ "GenSigSendType" SG_ 841 Kamera_FDD_Obj06_Typ 0;
BA_ "GenSigStartValue" SG_ 841 Kamera_FDD_Obj06_horizPos 1022;
BA_ "GenSigSendType" SG_ 841 Kamera_FDD_Obj06_horizPos 0;
BA_ "GenSigStartValue" SG_ 841 Kamera_FDD_Obj06_Ersatzw 2;
BA_ "GenSigSendType" SG_ 841 Kamera_FDD_Obj06_Ersatzw 0;
BA_ "GenSigStartValue" SG_ 841 Kamera_FDD_Obj06_horizDim 1022;
BA_ "GenSigSendType" SG_ 841 Kamera_FDD_Obj06_horizDim 0;
BA_ "GenSigStartValue" SG_ 841 Kamera_FDD_Obj06_vertPos 1022;
BA_ "GenSigSendType" SG_ 841 Kamera_FDD_Obj06_vertPos 0;
BA_ "GenSigSendType" SG_ 841 Kamera_FDD_Obj06_horizGuete_li 0;
BA_ "GenSigSendType" SG_ 841 Kamera_FDD_Obj06_horizGuete_re 0;
BA_ "GenSigStartValue" SG_ 841 Kamera_FDD_Obj06_Entfernung 14;
BA_ "GenSigSendType" SG_ 841 Kamera_FDD_Obj06_Entfernung 0;
BA_ "GenSigSendType" SG_ 841 Kamera_FDD_Obj06_Objguete 0;
BA_ "GenSigStartValue" SG_ 842 Kamera_FDD_Obj07_ID 254;
BA_ "GenSigSendType" SG_ 842 Kamera_FDD_Obj07_ID 0;
BA_ "GenSigSendType" SG_ 842 Kamera_FDD_Obj07_Entf_Nah 0;
BA_ "GenSigStartValue" SG_ 842 Kamera_FDD_Obj07_Typ 14;
BA_ "GenSigSendType" SG_ 842 Kamera_FDD_Obj07_Typ 0;
BA_ "GenSigStartValue" SG_ 842 Kamera_FDD_Obj07_horizPos 1022;
BA_ "GenSigSendType" SG_ 842 Kamera_FDD_Obj07_horizPos 0;
BA_ "GenSigStartValue" SG_ 842 Kamera_FDD_Obj07_Ersatzw 2;
BA_ "GenSigSendType" SG_ 842 Kamera_FDD_Obj07_Ersatzw 0;
BA_ "GenSigStartValue" SG_ 842 Kamera_FDD_Obj07_horizDim 1022;
BA_ "GenSigSendType" SG_ 842 Kamera_FDD_Obj07_horizDim 0;
BA_ "GenSigStartValue" SG_ 842 Kamera_FDD_Obj07_vertPos 1022;
BA_ "GenSigSendType" SG_ 842 Kamera_FDD_Obj07_vertPos 0;
BA_ "GenSigSendType" SG_ 842 Kamera_FDD_Obj07_horizGuete_li 0;
BA_ "GenSigSendType" SG_ 842 Kamera_FDD_Obj07_horizGuete_re 0;
BA_ "GenSigStartValue" SG_ 842 Kamera_FDD_Obj07_Entfernung 14;
BA_ "GenSigSendType" SG_ 842 Kamera_FDD_Obj07_Entfernung 0;
BA_ "GenSigSendType" SG_ 842 Kamera_FDD_Obj07_Objguete 0;
BA_ "GenSigStartValue" SG_ 843 Kamera_FDD_Obj08_ID 254;
BA_ "GenSigSendType" SG_ 843 Kamera_FDD_Obj08_ID 0;
BA_ "GenSigSendType" SG_ 843 Kamera_FDD_Obj08_Entf_Nah 0;
BA_ "GenSigStartValue" SG_ 843 Kamera_FDD_Obj08_Typ 14;
BA_ "GenSigSendType" SG_ 843 Kamera_FDD_Obj08_Typ 0;
BA_ "GenSigStartValue" SG_ 843 Kamera_FDD_Obj08_horizPos 1022;
BA_ "GenSigSendType" SG_ 843 Kamera_FDD_Obj08_horizPos 0;
BA_ "GenSigStartValue" SG_ 843 Kamera_FDD_Obj08_Ersatzw 2;
BA_ "GenSigSendType" SG_ 843 Kamera_FDD_Obj08_Ersatzw 0;
BA_ "GenSigStartValue" SG_ 843 Kamera_FDD_Obj08_horizDim 1022;
BA_ "GenSigSendType" SG_ 843 Kamera_FDD_Obj08_horizDim 0;
BA_ "GenSigStartValue" SG_ 843 Kamera_FDD_Obj08_vertPos 1022;
BA_ "GenSigSendType" SG_ 843 Kamera_FDD_Obj08_vertPos 0;
BA_ "GenSigSendType" SG_ 843 Kamera_FDD_Obj08_horizGuete_li 0;
BA_ "GenSigSendType" SG_ 843 Kamera_FDD_Obj08_horizGuete_re 0;
BA_ "GenSigStartValue" SG_ 843 Kamera_FDD_Obj08_Entfernung 14;
BA_ "GenSigSendType" SG_ 843 Kamera_FDD_Obj08_Entfernung 0;
BA_ "GenSigSendType" SG_ 843 Kamera_FDD_Obj08_Objguete 0;
BA_ "GenSigSendType" SG_ 844 Kamera_FDD_SL_01_ID 0;
BA_ "GenSigStartValue" SG_ 844 Kamera_FDD_SL_01_horizPos 1022;
BA_ "GenSigSendType" SG_ 844 Kamera_FDD_SL_01_horizPos 0;
BA_ "GenSigStartValue" SG_ 844 Kamera_FDD_SL_01_vertPos 1022;
BA_ "GenSigSendType" SG_ 844 Kamera_FDD_SL_01_vertPos 0;
BA_ "GenSigStartValue" SG_ 844 Kamera_FDD_SL_01_Typ 2;
BA_ "GenSigSendType" SG_ 844 Kamera_FDD_SL_01_Typ 0;
BA_ "GenSigSendType" SG_ 844 Kamera_FDD_SL_01_Objguete 0;
BA_ "Fehlerwert" SG_ 844 Kamera_FDD_SL_01_Ersatzw 3;
BA_ "GenSigStartValue" SG_ 844 Kamera_FDD_SL_01_Ersatzw 2;
BA_ "GenSigSendType" SG_ 844 Kamera_FDD_SL_01_Ersatzw 0;
BA_ "GenSigSendType" SG_ 845 Kamera_FDD_SL_02_ID 0;
BA_ "GenSigStartValue" SG_ 845 Kamera_FDD_SL_02_horizPos 1022;
BA_ "GenSigSendType" SG_ 845 Kamera_FDD_SL_02_horizPos 0;
BA_ "GenSigStartValue" SG_ 845 Kamera_FDD_SL_02_vertPos 1022;
BA_ "GenSigSendType" SG_ 845 Kamera_FDD_SL_02_vertPos 0;
BA_ "GenSigStartValue" SG_ 845 Kamera_FDD_SL_02_Typ 2;
BA_ "GenSigSendType" SG_ 845 Kamera_FDD_SL_02_Typ 0;
BA_ "GenSigSendType" SG_ 845 Kamera_FDD_SL_02_Objguete 0;
BA_ "Fehlerwert" SG_ 845 Kamera_FDD_SL_02_Ersatzw 3;
BA_ "GenSigStartValue" SG_ 845 Kamera_FDD_SL_02_Ersatzw 2;
BA_ "GenSigSendType" SG_ 845 Kamera_FDD_SL_02_Ersatzw 0;
BA_ "GenSigStartValue" SG_ 792 Kamera_Systemzustand 1;
BA_ "GenSigSendType" SG_ 792 Kamera_Systemzustand 0;
BA_ "Fehlerwert" SG_ 792 Kamera_FDD_Eigenblend_Guete 15;
BA_ "GenSigStartValue" SG_ 792 Kamera_FDD_Eigenblend_Guete 14;
BA_ "GenSigSendType" SG_ 792 Kamera_FDD_Eigenblend_Guete 0;
BA_ "GenSigSendType" SG_ 792 Kamera_FDD_Eigenblend 0;
BA_ "GenSigSendType" SG_ 792 Kamera_FDD_Strassenbeleuchung 0;
BA_ "GenSigStartValue" SG_ 792 Kamera_FDD_Funktionsstatus 6;
BA_ "GenSigSendType" SG_ 792 Kamera_FDD_Funktionsstatus 0;
BA_ "GenSigStartValue" SG_ 792 Kamera_FDD_Anz_Strassenleuchten 15;
BA_ "GenSigSendType" SG_ 792 Kamera_FDD_Anz_Strassenleuchten 0;
BA_ "GenSigStartValue" SG_ 792 Kamera_FDD_Verkehrsrichtung 2;
BA_ "GenSigSendType" SG_ 792 Kamera_FDD_Verkehrsrichtung 0;
BA_ "GenSigSendType" SG_ 792 Kamera_FSH_aktiv 0;
BA_ "GenSigSwitchedByIgnition" SG_ 960 Klemmen_Status_01_CRC 0;
BA_ "GenSigFuncType" SG_ 960 Klemmen_Status_01_CRC 2;
BA_ "GenSigSendType" SG_ 960 Klemmen_Status_01_CRC 0;
BA_ "GenSigSwitchedByIgnition" SG_ 960 Klemmen_Status_01_BZ 0;
BA_ "GenSigFuncType" SG_ 960 Klemmen_Status_01_BZ 1;
BA_ "GenSigSendType" SG_ 960 Klemmen_Status_01_BZ 0;
BA_ "GenSigSwitchedByIgnition" SG_ 960 RSt_Fahrerhinweise 0;
BA_ "GenSigSendType" SG_ 960 RSt_Fahrerhinweise 3;
BA_ "GenSigSwitchedByIgnition" SG_ 960 ZAS_Kl_S 0;
BA_ "GenSigSendType" SG_ 960 ZAS_Kl_S 3;
BA_ "GenSigSwitchedByIgnition" SG_ 960 ZAS_Kl_15 0;
BA_ "GenSigFuncType" SG_ 960 ZAS_Kl_15 6;
BA_ "NWM-WakeupAllowed" SG_ 960 ZAS_Kl_15 1;
BA_ "GenSigSendType" SG_ 960 ZAS_Kl_15 3;
BA_ "GenSigSwitchedByIgnition" SG_ 960 ZAS_Kl_X 0;
BA_ "GenSigSendType" SG_ 960 ZAS_Kl_X 3;
BA_ "GenSigSwitchedByIgnition" SG_ 960 ZAS_Kl_50_Startanforderung 0;
BA_ "GenSigSendType" SG_ 960 ZAS_Kl_50_Startanforderung 3;
BA_ "GenSigSwitchedByIgnition" SG_ 960 BCM_Remotestart_Betrieb 0;
BA_ "GenSigSendType" SG_ 960 BCM_Remotestart_Betrieb 3;
BA_ "GenSigSwitchedByIgnition" SG_ 960 ZAS_Kl_Infotainment 0;
BA_ "GenSigSendType" SG_ 960 ZAS_Kl_Infotainment 3;
BA_ "GenSigSwitchedByIgnition" SG_ 960 BCM_Remotestart_KL15_Anf 0;
BA_ "GenSigSendType" SG_ 960 BCM_Remotestart_KL15_Anf 3;
BA_ "GenSigSwitchedByIgnition" SG_ 960 BCM_Remotestart_MO_Start 0;
BA_ "GenSigSendType" SG_ 960 BCM_Remotestart_MO_Start 3;
BA_ "GenSigSwitchedByIgnition" SG_ 960 KST_Warn_P1_ZST_def 0;
BA_ "GenSigSendType" SG_ 960 KST_Warn_P1_ZST_def 3;
BA_ "GenSigSwitchedByIgnition" SG_ 960 KST_Warn_P2_ZST_def 0;
BA_ "GenSigSendType" SG_ 960 KST_Warn_P2_ZST_def 3;
BA_ "GenSigSwitchedByIgnition" SG_ 960 KST_Fahrerhinweis_1 0;
BA_ "GenSigSendType" SG_ 960 KST_Fahrerhinweis_1 3;
BA_ "GenSigSwitchedByIgnition" SG_ 960 KST_Fahrerhinweis_2 0;
BA_ "GenSigSendType" SG_ 960 KST_Fahrerhinweis_2 3;
BA_ "GenSigSwitchedByIgnition" SG_ 960 KST_Fahrerhinweis_3 0;
BA_ "GenSigSendType" SG_ 960 KST_Fahrerhinweis_3 3;
BA_ "GenSigSwitchedByIgnition" SG_ 960 KST_Fahrerhinweis_4 0;
BA_ "GenSigSendType" SG_ 960 KST_Fahrerhinweis_4 3;
BA_ "GenSigSwitchedByIgnition" SG_ 960 KST_Fahrerhinweis_5 0;
BA_ "GenSigSendType" SG_ 960 KST_Fahrerhinweis_5 3;
BA_ "GenSigSwitchedByIgnition" SG_ 960 KST_Fahrerhinweis_6 0;
BA_ "GenSigSendType" SG_ 960 KST_Fahrerhinweis_6 3;
BA_ "GenSigSwitchedByIgnition" SG_ 1646 KL_STL_aktiv 0;
BA_ "GenSigSendType" SG_ 1646 KL_STL_aktiv 3;
BA_ "GenSigSwitchedByIgnition" SG_ 1646 KL_STH_aktiv 0;
BA_ "GenSigSendType" SG_ 1646 KL_STH_aktiv 3;
BA_ "GenSigSwitchedByIgnition" SG_ 1646 KL_Solarluefter_aktiv 0;
BA_ "GenSigSendType" SG_ 1646 KL_Solarluefter_aktiv 3;
BA_ "GenSigSwitchedByIgnition" SG_ 1646 KL_Umluft_Taste 0;
BA_ "GenSigSendType" SG_ 1646 KL_Umluft_Taste 3;
BA_ "Fehlerwert" SG_ 1646 KL_Geblaese_Fond_Status 15;
BA_ "GenSigSwitchedByIgnition" SG_ 1646 KL_Geblaese_Fond_Status 0;
BA_ "GenSigStartValue" SG_ 1646 KL_Geblaese_Fond_Status 14;
BA_ "GenSigSendType" SG_ 1646 KL_Geblaese_Fond_Status 0;
BA_ "GenSigSwitchedByIgnition" SG_ 1646 KL_STH_Ansteuerung 0;
BA_ "GenSigSendType" SG_ 1646 KL_STH_Ansteuerung 3;
BA_ "GenSigSwitchedByIgnition" SG_ 1646 KL_STH_Betriebsdauer 0;
BA_ "GenSigSendType" SG_ 1646 KL_STH_Betriebsdauer 3;
BA_ "GenSigSwitchedByIgnition" SG_ 1646 KL_Magnetventil 0;
BA_ "GenSigSendType" SG_ 1646 KL_Magnetventil 3;
BA_ "GenSigSwitchedByIgnition" SG_ 1646 KL_WaPu 0;
BA_ "GenSigSendType" SG_ 1646 KL_WaPu 3;
BA_ "Fehlerwert" SG_ 1646 KL_Geblaese_Status 15;
BA_ "GenSigSwitchedByIgnition" SG_ 1646 KL_Geblaese_Status 0;
BA_ "GenSigStartValue" SG_ 1646 KL_Geblaese_Status 14;
BA_ "GenSigSendType" SG_ 1646 KL_Geblaese_Status 0;
BA_ "GenSigSwitchedByIgnition" SG_ 1646 KL_Restwaerme_aktiv 0;
BA_ "GenSigSendType" SG_ 1646 KL_Restwaerme_aktiv 3;
BA_ "GenSigSwitchedByIgnition" SG_ 1646 KL_Kompressorkupplung 0;
BA_ "GenSigSendType" SG_ 1646 KL_Kompressorkupplung 3;
BA_ "GenSigSwitchedByIgnition" SG_ 1646 KL_BCmE_Livetip_Freigabe 0;
BA_ "GenSigSendType" SG_ 1646 KL_BCmE_Livetip_Freigabe 3;
BA_ "GenSigSwitchedByIgnition" SG_ 1646 KL_SH_Soll_hl 0;
BA_ "GenSigSendType" SG_ 1646 KL_SH_Soll_hl 3;
BA_ "GenSigSwitchedByIgnition" SG_ 1646 KL_SH_Soll_hr 0;
BA_ "GenSigSendType" SG_ 1646 KL_SH_Soll_hr 3;
BA_ "Fehlerwert" SG_ 1646 KL_Innen_Temp 255;
BA_ "GenSigSwitchedByIgnition" SG_ 1646 KL_Innen_Temp 0;
BA_ "GenSigStartValue" SG_ 1646 KL_Innen_Temp 254;
BA_ "GenSigSendType" SG_ 1646 KL_Innen_Temp 0;
BA_ "Fehlerwert" SG_ 1646 KL_I_Geblaese_Fond 255;
BA_ "GenSigSwitchedByIgnition" SG_ 1646 KL_I_Geblaese_Fond 0;
BA_ "GenSigSendType" SG_ 1646 KL_I_Geblaese_Fond 3;
BA_ "Fehlerwert" SG_ 1646 KL_Heizkreisventilstellung 3;
BA_ "GenSigSwitchedByIgnition" SG_ 1646 KL_Heizkreisventilstellung 0;
BA_ "GenSigSendType" SG_ 1646 KL_Heizkreisventilstellung 0;
BA_ "GenSigSwitchedByIgnition" SG_ 1646 KL_FSH_Automatikbetrieb 0;
BA_ "GenSigSendType" SG_ 1646 KL_FSH_Automatikbetrieb 3;
BA_ "GenSigSwitchedByIgnition" SG_ 1646 KL_SIH_LEH_Verteilung_VL 0;
BA_ "GenSigSendType" SG_ 1646 KL_SIH_LEH_Verteilung_VL 3;
BA_ "GenSigSwitchedByIgnition" SG_ 1646 KL_SIH_LEL_Verteilung_VL 0;
BA_ "GenSigSendType" SG_ 1646 KL_SIH_LEL_Verteilung_VL 3;
BA_ "GenSigSwitchedByIgnition" SG_ 1646 KL_SIH_LEH_Verteilung_VR 0;
BA_ "GenSigSendType" SG_ 1646 KL_SIH_LEH_Verteilung_VR 3;
BA_ "GenSigSwitchedByIgnition" SG_ 1646 KL_SIH_LEL_Verteilung_VR 0;
BA_ "GenSigSendType" SG_ 1646 KL_SIH_LEL_Verteilung_VR 3;
BA_ "GenSigSwitchedByIgnition" SG_ 949 KL_Drehz_Anh 0;
BA_ "GenSigSendType" SG_ 949 KL_Drehz_Anh 0;
BA_ "GenSigSwitchedByIgnition" SG_ 949 KL_Vorwarn_Komp_ein 0;
BA_ "GenSigSendType" SG_ 949 KL_Vorwarn_Komp_ein 0;
BA_ "GenSigSwitchedByIgnition" SG_ 949 KL_AC_Schalter 0;
BA_ "GenSigSendType" SG_ 949 KL_AC_Schalter 0;
BA_ "GenSigSwitchedByIgnition" SG_ 949 KL_Komp_Moment_alt 0;
BA_ "GenSigFuncType" SG_ 949 KL_Komp_Moment_alt 5;
BA_ "GenSigSendType" SG_ 949 KL_Komp_Moment_alt 0;
BA_ "GenSigSwitchedByIgnition" SG_ 949 KL_Vorwarn_Zuheizer_ein 0;
BA_ "GenSigSendType" SG_ 949 KL_Vorwarn_Zuheizer_ein 0;
BA_ "GenSigSwitchedByIgnition" SG_ 949 KL_Zustand 0;
BA_ "GenSigSendType" SG_ 949 KL_Zustand 0;
BA_ "GenSigSwitchedByIgnition" SG_ 949 KL_Kompressorkupplung_linear 0;
BA_ "GenSigStartValue" SG_ 949 KL_Kompressorkupplung_linear 254;
BA_ "GenSigSendType" SG_ 949 KL_Kompressorkupplung_linear 0;
BA_ "GenSigSwitchedByIgnition" SG_ 949 KL_Charisma_FahrPr 0;
BA_ "GenSigSendType" SG_ 949 KL_Charisma_FahrPr 0;
BA_ "GenSigSwitchedByIgnition" SG_ 949 KL_Charisma_Status 0;
BA_ "GenSigSendType" SG_ 949 KL_Charisma_Status 0;
BA_ "GenSigSwitchedByIgnition" SG_ 949 KL_nachtr_Stopp_Anf 0;
BA_ "GenSigSendType" SG_ 949 KL_nachtr_Stopp_Anf 0;
BA_ "GenSigSwitchedByIgnition" SG_ 949 KL_T_Charge 0;
BA_ "GenSigSendType" SG_ 949 KL_T_Charge 0;
BA_ "Fehlerwert" SG_ 949 KL_Last_Kompr 255;
BA_ "GenSigSwitchedByIgnition" SG_ 949 KL_Last_Kompr 0;
BA_ "GenSigSendType" SG_ 949 KL_Last_Kompr 0;
BA_ "GenSigSwitchedByIgnition" SG_ 949 KL_Spannungs_Anf 0;
BA_ "GenSigSendType" SG_ 949 KL_Spannungs_Anf 0;
BA_ "GenSigSwitchedByIgnition" SG_ 949 KL_Thermomanagement 0;
BA_ "GenSigSendType" SG_ 949 KL_Thermomanagement 0;
BA_ "GenSigSwitchedByIgnition" SG_ 949 KL_StartStopp_Info 0;
BA_ "GenSigSendType" SG_ 949 KL_StartStopp_Info 0;
BA_ "GenSigSwitchedByIgnition" SG_ 949 KL_Freilauf_Info 0;
BA_ "GenSigSendType" SG_ 949 KL_Freilauf_Info 0;
BA_ "Fehlerwert" SG_ 949 KL_Anf_KL 255;
BA_ "GenSigSwitchedByIgnition" SG_ 949 KL_Anf_KL 0;
BA_ "GenSigSendType" SG_ 949 KL_Anf_KL 0;
BA_ "GenSigSwitchedByIgnition" SG_ 949 KL_el_Zuheizer_Stufe 0;
BA_ "GenSigSendType" SG_ 949 KL_el_Zuheizer_Stufe 0;
BA_ "GenSigSwitchedByIgnition" SG_ 949 KL_Ausstattung_Klima 0;
BA_ "GenSigSendType" SG_ 949 KL_Ausstattung_Klima 0;
BA_ "GenSigSwitchedByIgnition" SG_ 949 KL_Variante_Standheizung 0;
BA_ "GenSigSendType" SG_ 949 KL_Variante_Standheizung 0;
BA_ "GenSigSwitchedByIgnition" SG_ 1511 KL_HV_Heizer_Strom 0;
BA_ "GenSigStartValue" SG_ 1511 KL_HV_Heizer_Strom 255;
BA_ "GenSigSendType" SG_ 1511 KL_HV_Heizer_Strom 0;
BA_ "GenSigSwitchedByIgnition" SG_ 1511 KL_EKK_Strom 0;
BA_ "GenSigStartValue" SG_ 1511 KL_EKK_Strom 255;
BA_ "GenSigSendType" SG_ 1511 KL_EKK_Strom 0;
BA_ "Fehlerwert" SG_ 1511 KL_Pumpe_02_Soll 127;
BA_ "GenSigSwitchedByIgnition" SG_ 1511 KL_Pumpe_02_Soll 0;
BA_ "GenSigStartValue" SG_ 1511 KL_Pumpe_02_Soll 126;
BA_ "GenSigSendType" SG_ 1511 KL_Pumpe_02_Soll 0;
BA_ "GenSigSwitchedByIgnition" SG_ 1511 KL_Ventil_03_Soll 0;
BA_ "GenSigSendType" SG_ 1511 KL_Ventil_03_Soll 0;
BA_ "Fehlerwert" SG_ 1511 KL_Ventil_10_Status 7;
BA_ "GenSigSwitchedByIgnition" SG_ 1511 KL_Ventil_10_Status 0;
BA_ "GenSigStartValue" SG_ 1511 KL_Ventil_10_Status 6;
BA_ "GenSigSendType" SG_ 1511 KL_Ventil_10_Status 0;
BA_ "GenSigSwitchedByIgnition" SG_ 1511 KL_Senderkennung 0;
BA_ "GenSigSendType" SG_ 1511 KL_Senderkennung 0;
BA_ "Fehlerwert" SG_ 1511 WP_KJ_Soll 3;
BA_ "GenSigSwitchedByIgnition" SG_ 1511 WP_KJ_Soll 0;
BA_ "GenSigSendType" SG_ 1511 WP_KJ_Soll 0;
BA_ "Fehlerwert" SG_ 1511 KL_Fehler_HV_EKK 3;
BA_ "GenSigSwitchedByIgnition" SG_ 1511 KL_Fehler_HV_EKK 0;
BA_ "GenSigSendType" SG_ 1511 KL_Fehler_HV_EKK 0;
BA_ "Fehlerwert" SG_ 1511 KL_Fehler_HV_Heizer 3;
BA_ "GenSigSwitchedByIgnition" SG_ 1511 KL_Fehler_HV_Heizer 0;
BA_ "GenSigSendType" SG_ 1511 KL_Fehler_HV_Heizer 0;
BA_ "Fehlerwert" SG_ 1511 KL_BattKond_WaPu_DZMax 63;
BA_ "GenSigSwitchedByIgnition" SG_ 1511 KL_BattKond_WaPu_DZMax 0;
BA_ "GenSigStartValue" SG_ 1511 KL_BattKond_WaPu_DZMax 62;
BA_ "GenSigSendType" SG_ 1511 KL_BattKond_WaPu_DZMax 0;
BA_ "Fehlerwert" SG_ 1511 WP_Kuehlerluefter_Anf 255;
BA_ "GenSigSwitchedByIgnition" SG_ 1511 WP_Kuehlerluefter_Anf 0;
BA_ "GenSigSendType" SG_ 1511 WP_Kuehlerluefter_Anf 0;
BA_ "Fehlerwert" SG_ 1511 KL_KM_ASV_01_Status 3;
BA_ "GenSigSwitchedByIgnition" SG_ 1511 KL_KM_ASV_01_Status 0;
BA_ "GenSigSendType" SG_ 1511 KL_KM_ASV_01_Status 0;
BA_ "Fehlerwert" SG_ 1511 KL_KM_ASV_02_Status 3;
BA_ "GenSigSwitchedByIgnition" SG_ 1511 KL_KM_ASV_02_Status 0;
BA_ "GenSigSendType" SG_ 1511 KL_KM_ASV_02_Status 0;
BA_ "GenSigSwitchedByIgnition" SG_ 1514 KL_Kundenwunsch_Kuehlen 0;
BA_ "GenSigSendType" SG_ 1514 KL_Kundenwunsch_Kuehlen 0;
BA_ "GenSigSwitchedByIgnition" SG_ 1514 KL_OBD_Status 0;
BA_ "GenSigSendType" SG_ 1514 KL_OBD_Status 0;
BA_ "GenSigSwitchedByIgnition" SG_ 1514 KL_KLE_Fehler_Anf 0;
BA_ "GenSigSendType" SG_ 1514 KL_KLE_Fehler_Anf 0;
BA_ "Fehlerwert" SG_ 1514 KL_Fehler_NTKreis 1;
BA_ "GenSigSwitchedByIgnition" SG_ 1514 KL_Fehler_NTKreis 0;
BA_ "GenSigSendType" SG_ 1514 KL_Fehler_NTKreis 0;
BA_ "GenSigSwitchedByIgnition" SG_ 1514 KL_Mot_Tk_Soll_li 0;
BA_ "GenSigSendType" SG_ 1514 KL_Mot_Tk_Soll_li 0;
BA_ "GenSigSwitchedByIgnition" SG_ 1514 KL_Mot_Tk_Soll_re 0;
BA_ "GenSigSendType" SG_ 1514 KL_Mot_Tk_Soll_re 0;
BA_ "Fehlerwert" SG_ 1514 KL_VK_Anf 7;
BA_ "GenSigSwitchedByIgnition" SG_ 1514 KL_VK_Anf 0;
BA_ "GenSigStartValue" SG_ 1514 KL_VK_Anf 6;
BA_ "GenSigSendType" SG_ 1514 KL_VK_Anf 0;
BA_ "Fehlerwert" SG_ 1514 KL_Standklima_Status_02 7;
BA_ "GenSigSwitchedByIgnition" SG_ 1514 KL_Standklima_Status_02 0;
BA_ "GenSigStartValue" SG_ 1514 KL_Standklima_Status_02 6;
BA_ "GenSigSendType" SG_ 1514 KL_Standklima_Status_02 0;
BA_ "GenSigSwitchedByIgnition" SG_ 1514 KL_Standklima_RemoteModus 0;
BA_ "GenSigSendType" SG_ 1514 KL_Standklima_RemoteModus 0;
BA_ "GenSigSwitchedByIgnition" SG_ 1514 KBT_Defrost_aktiv 0;
BA_ "GenSigSendType" SG_ 1514 KBT_Defrost_aktiv 0;
BA_ "Fehlerwert" SG_ 1514 KL_VK_Betriebsdauer 63;
BA_ "GenSigSwitchedByIgnition" SG_ 1514 KL_VK_Betriebsdauer 0;
BA_ "GenSigStartValue" SG_ 1514 KL_VK_Betriebsdauer 62;
BA_ "GenSigSendType" SG_ 1514 KL_VK_Betriebsdauer 0;
BA_ "Fehlerwert" SG_ 1514 KL_Heizbedarf 1023;
BA_ "GenSigSwitchedByIgnition" SG_ 1514 KL_Heizbedarf 0;
BA_ "GenSigStartValue" SG_ 1514 KL_Heizbedarf 1022;
BA_ "GenSigSendType" SG_ 1514 KL_Heizbedarf 0;
BA_ "Fehlerwert" SG_ 1514 KL_Innentemp_KBT_Sensor 1023;
BA_ "GenSigSwitchedByIgnition" SG_ 1514 KL_Innentemp_KBT_Sensor 0;
BA_ "GenSigStartValue" SG_ 1514 KL_Innentemp_KBT_Sensor 1022;
BA_ "GenSigSendType" SG_ 1514 KL_Innentemp_KBT_Sensor 0;
BA_ "GenSigSwitchedByIgnition" SG_ 1514 KL_Vorkond_Strategie 0;
BA_ "GenSigStartValue" SG_ 1514 KL_Vorkond_Strategie 15;
BA_ "GenSigSendType" SG_ 1514 KL_Vorkond_Strategie 0;
BA_ "Fehlerwert" SG_ 1515 KL_Abl_Soll_li 255;
BA_ "GenSigSwitchedByIgnition" SG_ 1515 KL_Abl_Soll_li 0;
BA_ "GenSigSendType" SG_ 1515 KL_Abl_Soll_li 0;
BA_ "Fehlerwert" SG_ 1515 KL_Abl_Soll_re 255;
BA_ "GenSigSwitchedByIgnition" SG_ 1515 KL_Abl_Soll_re 0;
BA_ "GenSigSendType" SG_ 1515 KL_Abl_Soll_re 0;
BA_ "Fehlerwert" SG_ 1515 KL_Verdampfer_Soll 255;
BA_ "GenSigSwitchedByIgnition" SG_ 1515 KL_Verdampfer_Soll 0;
BA_ "GenSigStartValue" SG_ 1515 KL_Verdampfer_Soll 254;
BA_ "GenSigSendType" SG_ 1515 KL_Verdampfer_Soll 0;
BA_ "Fehlerwert" SG_ 1515 KL_Abl_Ist_li 1023;
BA_ "GenSigSwitchedByIgnition" SG_ 1515 KL_Abl_Ist_li 0;
BA_ "GenSigStartValue" SG_ 1515 KL_Abl_Ist_li 1022;
BA_ "GenSigSendType" SG_ 1515 KL_Abl_Ist_li 0;
BA_ "Fehlerwert" SG_ 1515 KL_Abl_Ist_re 1023;
BA_ "GenSigSwitchedByIgnition" SG_ 1515 KL_Abl_Ist_re 0;
BA_ "GenSigStartValue" SG_ 1515 KL_Abl_Ist_re 1022;
BA_ "GenSigSendType" SG_ 1515 KL_Abl_Ist_re 0;
BA_ "GenSigSwitchedByIgnition" SG_ 1515 KL_Verdampfer_Ist 0;
BA_ "GenSigSendType" SG_ 1515 KL_Verdampfer_Ist 0;
BA_ "Fehlerwert" SG_ 1515 KL_TaupEps_Korr 1023;
BA_ "GenSigSwitchedByIgnition" SG_ 1515 KL_TaupEps_Korr 0;
BA_ "GenSigStartValue" SG_ 1515 KL_TaupEps_Korr 1022;
BA_ "GenSigSendType" SG_ 1515 KL_TaupEps_Korr 0;
BA_ "GenSigMissingSourceValue" SG_ 1712 FS_Taupunkt 1023;
BA_ "Fehlerwert" SG_ 1712 FS_Taupunkt 1023;
BA_ "GenSigSendType" SG_ 1712 FS_Taupunkt 0;
BA_ "Fehlerwert" SG_ 1712 FS_ResponseError 1;
BA_ "GenSigSendType" SG_ 1712 FS_ResponseError 0;
BA_ "GenSigMissingSourceValue" SG_ 1712 FS_Temp_Scheibe 1023;
BA_ "Fehlerwert" SG_ 1712 FS_Temp_Scheibe 1023;
BA_ "GenSigSendType" SG_ 1712 FS_Temp_Scheibe 0;
BA_ "GenSigMissingSourceValue" SG_ 1712 FS_Temp_Sensor 255;
BA_ "Fehlerwert" SG_ 1712 FS_Temp_Sensor 255;
BA_ "GenSigSendType" SG_ 1712 FS_Temp_Sensor 0;
BA_ "GenSigMissingSourceValue" SG_ 1712 FS_Luftfeuchte_rel 255;
BA_ "Fehlerwert" SG_ 1712 FS_Luftfeuchte_rel 255;
BA_ "GenSigSendType" SG_ 1712 FS_Luftfeuchte_rel 0;
BA_ "GenSigStartValue" SG_ 1717 FSA_Taupunkt 1022;
BA_ "GenSigSendType" SG_ 1717 FSA_Taupunkt 0;
BA_ "Fehlerwert" SG_ 1717 FSA_ResponseError 1;
BA_ "GenSigSendType" SG_ 1717 FSA_ResponseError 0;
BA_ "GenSigStartValue" SG_ 1717 FSA_Temp_Luft 1022;
BA_ "GenSigSendType" SG_ 1717 FSA_Temp_Luft 0;
BA_ "GenSigStartValue" SG_ 1717 FSA_Luftfeuchte_rel 254;
BA_ "GenSigSendType" SG_ 1717 FSA_Luftfeuchte_rel 0;
BA_ "GenSigSwitchedByIgnition" SG_ 1717 FSA_HW 0;
BA_ "GenSigSendType" SG_ 1717 FSA_HW 0;
BA_ "GenSigSendType" SG_ 1717 FSA_SW 0;
BA_ "GenSigStartValue" SG_ 1717 FSA_Temp_Sensor 2046;
BA_ "GenSigSendType" SG_ 1717 FSA_Temp_Sensor 0;
BA_ "GenSigSendType" SG_ 1717 FSA_Sensorheizung_Status 0;
BA_ "GenSigSendType" SG_ 2549088343 ACC_KompSchutz 0;
BA_ "GenSigSendType" SG_ 2549088343 ACC_Abschaltstufe 0;
BA_ "GenSigSendType" SG_ 2549088343 ACC_Transport_Mode 0;
BA_ "GenSigSendType" SG_ 2549088343 ACC_Nachlauftyp 0;
BA_ "GenSigStartValue" SG_ 2549088343 ACC_SNI 87;
BA_ "GenSigSendType" SG_ 2549088343 ACC_SNI 0;
BA_ "GenSigSendType" SG_ 2549088343 ACC_KD_Fehler 0;
BA_ "GenSigSendType" SG_ 2549088304 FLA_KompSchutz 0;
BA_ "GenSigSendType" SG_ 2549088304 FLA_Abschaltstufe 0;
BA_ "GenSigSendType" SG_ 2549088304 FLA_Transport_Mode 0;
BA_ "GenSigSendType" SG_ 2549088304 FLA_Nachlauftyp 0;
BA_ "GenSigStartValue" SG_ 2549088304 FLA_SNI 48;
BA_ "GenSigSendType" SG_ 2549088304 FLA_SNI 0;
BA_ "GenSigSendType" SG_ 2549088304 FLA_KD_Fehler 0;
BA_ "GenSigSendType" SG_ 2549088335 Kamera_KompSchutz 0;
BA_ "GenSigSendType" SG_ 2549088335 Kamera_Abschaltstufe 0;
BA_ "GenSigSendType" SG_ 2549088335 Kamera_Transport_Mode 0;
BA_ "GenSigSendType" SG_ 2549088335 Kamera_Nachlauftyp 0;
BA_ "GenSigStartValue" SG_ 2549088335 Kamera_SNI 79;
BA_ "GenSigSendType" SG_ 2549088335 Kamera_SNI 0;
BA_ "GenSigSendType" SG_ 2549088335 Kamera_KD_Fehler 0;
BA_ "GenSigSendType" SG_ 2549088340 LWRAFS_KompSchutz 0;
BA_ "GenSigSendType" SG_ 2549088340 LWRAFS_Abschaltstufe 0;
BA_ "GenSigSendType" SG_ 2549088340 LWRAFS_Transport_Mode 0;
BA_ "GenSigSendType" SG_ 2549088340 LWRAFS_Nachlauftyp 0;
BA_ "GenSigStartValue" SG_ 2549088340 LWRAFS_SNI 84;
BA_ "GenSigSendType" SG_ 2549088340 LWRAFS_SNI 0;
BA_ "GenSigSendType" SG_ 2549088340 LWR_KD_Fehler 0;
BA_ "GenSigSendType" SG_ 2549088334 SWA_KompSchutz 0;
BA_ "GenSigSendType" SG_ 2549088334 SWA_Abschaltstufe 0;
BA_ "GenSigSendType" SG_ 2549088334 SWA_Transport_Mode 0;
BA_ "GenSigSendType" SG_ 2549088334 SWA_Nachlauftyp 0;
BA_ "GenSigStartValue" SG_ 2549088334 SWA_SNI 78;
BA_ "GenSigSendType" SG_ 2549088334 SWA_SNI 0;
BA_ "GenSigSendType" SG_ 2549088334 KN_SWA_BusKnockOutTimer 0;
BA_ "GenSigSendType" SG_ 2549088334 SWA_KD_Fehler 0;
BA_ "GenSigSwitchedByIgnition" SG_ 779 KBI_ABS_Lampe 0;
BA_ "GenSigSendType" SG_ 779 KBI_ABS_Lampe 0;
BA_ "GenSigSwitchedByIgnition" SG_ 779 KBI_ESP_Lampe 0;
BA_ "GenSigSendType" SG_ 779 KBI_ESP_Lampe 0;
BA_ "GenSigSwitchedByIgnition" SG_ 779 KBI_BKL_Lampe 0;
BA_ "GenSigSendType" SG_ 779 KBI_BKL_Lampe 0;
BA_ "GenSigSwitchedByIgnition" SG_ 779 KBI_Airbag_Lampe 0;
BA_ "GenSigSendType" SG_ 779 KBI_Airbag_Lampe 0;
BA_ "GenSigSwitchedByIgnition" SG_ 779 KBI_SILA_gueltig 0;
BA_ "GenSigSendType" SG_ 779 KBI_SILA_gueltig 0;
BA_ "GenSigSwitchedByIgnition" SG_ 779 KBI_Lenkung_Lampe 0;
BA_ "GenSigSendType" SG_ 779 KBI_Lenkung_Lampe 0;
BA_ "GenSigSwitchedByIgnition" SG_ 779 KBI_Vorglueh_System_Lampe 0;
BA_ "GenSigSendType" SG_ 779 KBI_Vorglueh_System_Lampe 0;
BA_ "GenSigSwitchedByIgnition" SG_ 779 KBI_NV_in_Anzeige 0;
BA_ "GenSigSendType" SG_ 779 KBI_NV_in_Anzeige 0;
BA_ "GenSigSwitchedByIgnition" SG_ 779 Kombi_01_BZ 0;
BA_ "GenSigFuncType" SG_ 779 Kombi_01_BZ 1;
BA_ "GenSigSendType" SG_ 779 Kombi_01_BZ 0;
BA_ "GenSigSwitchedByIgnition" SG_ 779 KBI_Anzeigestatus_ACC 0;
BA_ "GenSigSendType" SG_ 779 KBI_Anzeigestatus_ACC 0;
BA_ "Fehlerwert" SG_ 779 KBI_Anzeigestatus_GRA 3;
BA_ "GenSigSwitchedByIgnition" SG_ 779 KBI_Anzeigestatus_GRA 0;
BA_ "GenSigSendType" SG_ 779 KBI_Anzeigestatus_GRA 0;
BA_ "GenSigSwitchedByIgnition" SG_ 779 KBI_Oeldruck_Schalter 0;
BA_ "GenSigSendType" SG_ 779 KBI_Oeldruck_Schalter 0;
BA_ "GenSigSwitchedByIgnition" SG_ 779 KBI_Tankwarnung 0;
BA_ "GenSigSendType" SG_ 779 KBI_Tankwarnung 0;
BA_ "GenSigSwitchedByIgnition" SG_ 779 KBI_MFA_v_Einheit_01 0;
BA_ "GenSigSendType" SG_ 779 KBI_MFA_v_Einheit_01 0;
BA_ "GenSigSwitchedByIgnition" SG_ 779 KBI_im_Stellgliedtest 0;
BA_ "GenSigSendType" SG_ 779 KBI_im_Stellgliedtest 0;
BA_ "GenSigSwitchedByIgnition" SG_ 779 KBI_Anzeigefehler_LDW 0;
BA_ "GenSigSendType" SG_ 779 KBI_Anzeigefehler_LDW 0;
BA_ "GenSigSwitchedByIgnition" SG_ 779 KBI_Oeldruckwarnung 0;
BA_ "GenSigSendType" SG_ 779 KBI_Oeldruckwarnung 0;
BA_ "GenSigSwitchedByIgnition" SG_ 779 KBI_Handbremse 0;
BA_ "GenSigSendType" SG_ 779 KBI_Handbremse 0;
BA_ "GenSigSwitchedByIgnition" SG_ 779 KBI_V_Digital 0;
BA_ "GenSigSendType" SG_ 779 KBI_V_Digital 0;
BA_ "GenSigSwitchedByIgnition" SG_ 779 KBI_PLA_in_Anzeige 0;
BA_ "GenSigSendType" SG_ 779 KBI_PLA_in_Anzeige 0;
BA_ "GenSigSwitchedByIgnition" SG_ 779 KBI_Anzeigefehler_NV 0;
BA_ "GenSigSendType" SG_ 779 KBI_Anzeigefehler_NV 0;
BA_ "Fehlerwert" SG_ 779 KBI_Anzeigestatus_LIM 3;
BA_ "GenSigSwitchedByIgnition" SG_ 779 KBI_Anzeigestatus_LIM 0;
BA_ "GenSigSendType" SG_ 779 KBI_Anzeigestatus_LIM 0;
BA_ "GenSigSwitchedByIgnition" SG_ 779 KBI_ARA_in_Anzeige 0;
BA_ "GenSigSendType" SG_ 779 KBI_ARA_in_Anzeige 0;
BA_ "GenSigSwitchedByIgnition" SG_ 779 KBI_angez_Geschw 0;
BA_ "GenSigSendType" SG_ 779 KBI_angez_Geschw 0;
BA_ "GenSigSwitchedByIgnition" SG_ 779 KBI_Einheit_Tacho 0;
BA_ "GenSigSendType" SG_ 779 KBI_Einheit_Tacho 0;
BA_ "GenSigSwitchedByIgnition" SG_ 779 KBI_Konsistenz_ACC 0;
BA_ "GenSigSendType" SG_ 779 KBI_Konsistenz_ACC 0;
BA_ "GenSigSwitchedByIgnition" SG_ 779 KBI_Fehler_Anzeige_ACC 0;
BA_ "GenSigSendType" SG_ 779 KBI_Fehler_Anzeige_ACC 0;
BA_ "GenSigSwitchedByIgnition" SG_ 779 KBI_Anzeigefehler_SWA 0;
BA_ "GenSigSendType" SG_ 779 KBI_Anzeigefehler_SWA 0;
BA_ "Fehlerwert" SG_ 1719 KBI_Kilometerstand 1048575;
BA_ "GenSigSwitchedByIgnition" SG_ 1719 KBI_Kilometerstand 0;
BA_ "GenSigStartValue" SG_ 1719 KBI_Kilometerstand 1048574;
BA_ "GenSigSendType" SG_ 1719 KBI_Kilometerstand 0;
BA_ "Fehlerwert" SG_ 1719 KBI_Standzeit_02 131071;
BA_ "GenSigSwitchedByIgnition" SG_ 1719 KBI_Standzeit_02 0;
BA_ "GenSigStartValue" SG_ 1719 KBI_Standzeit_02 131070;
BA_ "GenSigSendType" SG_ 1719 KBI_Standzeit_02 0;
BA_ "GenSigSwitchedByIgnition" SG_ 1719 KBI_Reserve_Warnung_Sek 0;
BA_ "GenSigSendType" SG_ 1719 KBI_Reserve_Warnung_Sek 3;
BA_ "GenSigSwitchedByIgnition" SG_ 1719 KBI_RDK_Kalibrier_Anf 0;
BA_ "GenSigSendType" SG_ 1719 KBI_RDK_Kalibrier_Anf 3;
BA_ "Fehlerwert" SG_ 1719 KBI_Inhalt_Tank 127;
BA_ "GenSigSwitchedByIgnition" SG_ 1719 KBI_Inhalt_Tank 0;
BA_ "GenSigStartValue" SG_ 1719 KBI_Inhalt_Tank 126;
BA_ "GenSigSendType" SG_ 1719 KBI_Inhalt_Tank 0;
BA_ "GenSigSwitchedByIgnition" SG_ 1719 KBI_FStatus_Tank 0;
BA_ "GenSigSendType" SG_ 1719 KBI_FStatus_Tank 0;
BA_ "GenSigSendType" SG_ 1719 KBI_aktive_Laengsfunktion 3;
BA_ "GenSigSwitchedByIgnition" SG_ 1719 KBI_Oelwechsel_durchgefuehrt 0;
BA_ "GenSigSendType" SG_ 1719 KBI_Oelwechsel_durchgefuehrt 0;
BA_ "GenSigSwitchedByIgnition" SG_ 1719 KBI_QBit_Aussen_Temp_gef 0;
BA_ "GenSigStartValue" SG_ 1719 KBI_QBit_Aussen_Temp_gef 1;
BA_ "GenSigSendType" SG_ 1719 KBI_QBit_Aussen_Temp_gef 0;
BA_ "Fehlerwert" SG_ 1719 KBI_Aussen_Temp_gef 255;
BA_ "GenSigSwitchedByIgnition" SG_ 1719 KBI_Aussen_Temp_gef 0;
BA_ "GenSigStartValue" SG_ 1719 KBI_Aussen_Temp_gef 254;
BA_ "GenSigSendType" SG_ 1719 KBI_Aussen_Temp_gef 0;
BA_ "GenSigSwitchedByIgnition" SG_ 1720 KBI_Reifenumfang 0;
BA_ "GenSigFuncType" SG_ 1720 KBI_Reifenumfang 8;
BA_ "GenSigSendType" SG_ 1720 KBI_Reifenumfang 0;
BA_ "GenSigSwitchedByIgnition" SG_ 1720 KBI_Variante_USA 0;
BA_ "GenSigSendType" SG_ 1720 KBI_Variante_USA 0;
BA_ "GenSigSwitchedByIgnition" SG_ 1720 KBI_Variante 0;
BA_ "GenSigSendType" SG_ 1720 KBI_Variante 0;
BA_ "GenSigSwitchedByIgnition" SG_ 1720 KBI_BCmE_aktiv 0;
BA_ "GenSigSendType" SG_ 1720 KBI_BCmE_aktiv 0;
BA_ "GenSigSwitchedByIgnition" SG_ 1720 KBI_Sparhinweis_quittiert 0;
BA_ "GenSigSendType" SG_ 1720 KBI_Sparhinweis_quittiert 0;
BA_ "Fehlerwert" SG_ 1720 KBI_Tankfuellstand_Prozent 127;
BA_ "GenSigSwitchedByIgnition" SG_ 1720 KBI_Tankfuellstand_Prozent 0;
BA_ "GenSigStartValue" SG_ 1720 KBI_Tankfuellstand_Prozent 126;
BA_ "GenSigSendType" SG_ 1720 KBI_Tankfuellstand_Prozent 0;
BA_ "GenSigSwitchedByIgnition" SG_ 1720 KBI_Nachtanken_erkannt 0;
BA_ "GenSigSendType" SG_ 1720 KBI_Nachtanken_erkannt 0;
BA_ "Fehlerwert" SG_ 1720 KBI_Tankinhalt_hochaufl 16383;
BA_ "GenSigSwitchedByIgnition" SG_ 1720 KBI_Tankinhalt_hochaufl 0;
BA_ "GenSigStartValue" SG_ 1720 KBI_Tankinhalt_hochaufl 16382;
BA_ "GenSigSendType" SG_ 1720 KBI_Tankinhalt_hochaufl 0;
BA_ "Fehlerwert" SG_ 1720 KBI_Max_Tankinhalt 255;
BA_ "GenSigSwitchedByIgnition" SG_ 1720 KBI_Max_Tankinhalt 0;
BA_ "GenSigStartValue" SG_ 1720 KBI_Max_Tankinhalt 254;
BA_ "GenSigSendType" SG_ 1720 KBI_Max_Tankinhalt 0;
BA_ "GenSigSwitchedByIgnition" SG_ 1720 KBI_Reifenumfang_Sekundaer 0;
BA_ "GenSigSendType" SG_ 1720 KBI_Reifenumfang_Sekundaer 0;
BA_ "GenSigSwitchedByIgnition" SG_ 2549875031 KS_ACC_Req_Data 0;
BA_ "GenSigFuncType" SG_ 2549875031 KS_ACC_Req_Data 9;
BA_ "GenSigFuncType" SG_ 2550006103 KS_ACC_Resp_Data 9;
BA_ "GenSigSwitchedByIgnition" SG_ 2549875023 KS_Kamera_Req_Data 0;
BA_ "GenSigFuncType" SG_ 2549875023 KS_Kamera_Req_Data 9;
BA_ "GenSigSwitchedByIgnition" SG_ 2550006095 KS_Kamera_Resp_Data 0;
BA_ "GenSigFuncType" SG_ 2550006095 KS_Kamera_Resp_Data 9;
BA_ "GenSigSwitchedByIgnition" SG_ 2549875082 KS_SWA_2_Req_Data 0;
BA_ "GenSigFuncType" SG_ 2549875082 KS_SWA_2_Req_Data 9;
BA_ "GenSigSwitchedByIgnition" SG_ 2550006154 KS_SWA_2_Resp_Data 0;
BA_ "GenSigFuncType" SG_ 2550006154 KS_SWA_2_Resp_Data 9;
BA_ "GenSigSwitchedByIgnition" SG_ 2549875022 KS_SWA_Req_Data 0;
BA_ "GenSigFuncType" SG_ 2549875022 KS_SWA_Req_Data 9;
BA_ "GenSigSwitchedByIgnition" SG_ 2550006094 KS_SWA_Resp_Data 0;
BA_ "GenSigFuncType" SG_ 2550006094 KS_SWA_Resp_Data 9;
BA_ "GenSigSendType" SG_ 919 LDW_Gong 0;
BA_ "Fehlerwert" SG_ 919 LDW_Frueh_Spaet 3;
BA_ "GenSigStartValue" SG_ 919 LDW_Frueh_Spaet 2;
BA_ "GenSigSendType" SG_ 919 LDW_Frueh_Spaet 0;
BA_ "GenSigSendType" SG_ 919 LDW_Texte 0;
BA_ "GenSigSendType" SG_ 919 LDW_Seite_DLCTLC 0;
BA_ "GenSigSendType" SG_ 919 LDW_Lernmodus 0;
BA_ "GenSigSendType" SG_ 919 LDW_Anlaufsp_VLR 3;
BA_ "GenSigSendType" SG_ 919 LDW_Vib_Amp_VLR 3;
BA_ "GenSigSendType" SG_ 919 LDW_Anlaufzeit_VLR 3;
BA_ "GenSigSendType" SG_ 919 LDW_Lernmodus_seitenabhaengig 3;
BA_ "GenSigStartValue" SG_ 919 LDW_DLC 250;
BA_ "GenSigSendType" SG_ 919 LDW_DLC 0;
BA_ "GenSigStartValue" SG_ 919 LDW_TLC 31;
BA_ "GenSigSendType" SG_ 919 LDW_TLC 0;
BA_ "GenSigSendType" SG_ 919 HC_Uss_Anforderung 3;
BA_ "GenSigSendType" SG_ 919 EA_Warnblinken 0;
BA_ "GenSigSendType" SG_ 919 LDW_Warnung_links 3;
BA_ "GenSigSendType" SG_ 919 LDW_Warnung_rechts 3;
BA_ "GenSigSendType" SG_ 919 LDW_Codierinfo_fuer_VLR 0;
BA_ "GenSigSendType" SG_ 919 LDW_Status_LED_gelb 0;
BA_ "GenSigSendType" SG_ 919 LDW_Status_LED_gruen 0;
BA_ "GenSigSwitchedByIgnition" SG_ 159 EPS_03_CRC 0;
BA_ "GenSigFuncType" SG_ 159 EPS_03_CRC 2;
BA_ "GenSigSendType" SG_ 159 EPS_03_CRC 0;
BA_ "GenSigSwitchedByIgnition" SG_ 159 EPS_03_BZ 0;
BA_ "GenSigFuncType" SG_ 159 EPS_03_BZ 1;
BA_ "GenSigSendType" SG_ 159 EPS_03_BZ 0;
BA_ "GenSigSwitchedByIgnition" SG_ 159 EPS_DSR_Status 0;
BA_ "GenSigSendType" SG_ 159 EPS_DSR_Status 0;
BA_ "Fehlerwert" SG_ 159 EPS_Berechneter_LW 4095;
BA_ "GenSigSwitchedByIgnition" SG_ 159 EPS_Berechneter_LW 0;
BA_ "GenSigStartValue" SG_ 159 EPS_Berechneter_LW 4094;
BA_ "GenSigSendType" SG_ 159 EPS_Berechneter_LW 0;
BA_ "GenSigSwitchedByIgnition" SG_ 159 EPS_BLW_QBit 0;
BA_ "GenSigSendType" SG_ 159 EPS_BLW_QBit 0;
BA_ "GenSigSwitchedByIgnition" SG_ 159 EPS_VZ_BLW 0;
BA_ "GenSigSendType" SG_ 159 EPS_VZ_BLW 0;
BA_ "GenSigSwitchedByIgnition" SG_ 159 EPS_HCA_Status 0;
BA_ "GenSigStartValue" SG_ 159 EPS_HCA_Status 3;
BA_ "GenSigSendType" SG_ 159 EPS_HCA_Status 0;
BA_ "Fehlerwert" SG_ 159 EPS_Lenkmoment 1023;
BA_ "GenSigSwitchedByIgnition" SG_ 159 EPS_Lenkmoment 0;
BA_ "GenSigStartValue" SG_ 159 EPS_Lenkmoment 1022;
BA_ "GenSigSendType" SG_ 159 EPS_Lenkmoment 0;
BA_ "GenSigSwitchedByIgnition" SG_ 159 EPS_Lenkmoment_QBit 0;
BA_ "GenSigSendType" SG_ 159 EPS_Lenkmoment_QBit 0;
BA_ "GenSigSwitchedByIgnition" SG_ 159 EPS_VZ_Lenkmoment 0;
BA_ "GenSigSendType" SG_ 159 EPS_VZ_Lenkmoment 0;
BA_ "GenSigSwitchedByIgnition" SG_ 159 EPS_Lenkungstyp 0;
BA_ "GenSigStartValue" SG_ 159 EPS_Lenkungstyp 15;
BA_ "GenSigSendType" SG_ 159 EPS_Lenkungstyp 0;
BA_ "GenSigSwitchedByIgnition" SG_ 981 Licht_Anf_01_CRC 0;
BA_ "GenSigFuncType" SG_ 981 Licht_Anf_01_CRC 2;
BA_ "GenSigSendType" SG_ 981 Licht_Anf_01_CRC 0;
BA_ "GenSigSwitchedByIgnition" SG_ 981 Licht_Anf_01_BZ 0;
BA_ "GenSigFuncType" SG_ 981 Licht_Anf_01_BZ 1;
BA_ "GenSigSendType" SG_ 981 Licht_Anf_01_BZ 0;
BA_ "GenSigSwitchedByIgnition" SG_ 981 BCM1_Kurvenlicht_links_Anf 0;
BA_ "GenSigSendType" SG_ 981 BCM1_Kurvenlicht_links_Anf 0;
BA_ "GenSigSwitchedByIgnition" SG_ 981 BCM1_Kurvenlicht_rechts_Anf 0;
BA_ "GenSigSendType" SG_ 981 BCM1_Kurvenlicht_rechts_Anf 0;
BA_ "GenSigSwitchedByIgnition" SG_ 981 BCM1_Standlicht_Anf 0;
BA_ "GenSigSendType" SG_ 981 BCM1_Standlicht_Anf 0;
BA_ "GenSigSwitchedByIgnition" SG_ 981 BCM1_Abblendlicht_Anf 0;
BA_ "GenSigSendType" SG_ 981 BCM1_Abblendlicht_Anf 0;
BA_ "GenSigSwitchedByIgnition" SG_ 981 BCM1_Fernlicht_Anf 0;
BA_ "GenSigSendType" SG_ 981 BCM1_Fernlicht_Anf 0;
BA_ "GenSigSwitchedByIgnition" SG_ 981 BCM1_Nebellicht_Anf 0;
BA_ "GenSigSendType" SG_ 981 BCM1_Nebellicht_Anf 0;
BA_ "GenSigSwitchedByIgnition" SG_ 981 BCM1_Parklicht_li_Anf 0;
BA_ "GenSigSendType" SG_ 981 BCM1_Parklicht_li_Anf 0;
BA_ "GenSigSwitchedByIgnition" SG_ 981 BCM1_Parklicht_re_Anf 0;
BA_ "GenSigSendType" SG_ 981 BCM1_Parklicht_re_Anf 0;
BA_ "GenSigSwitchedByIgnition" SG_ 981 BCM1_Nebelschluss_Ahg_Anf 0;
BA_ "GenSigSendType" SG_ 981 BCM1_Nebelschluss_Ahg_Anf 0;
BA_ "GenSigSwitchedByIgnition" SG_ 981 BCM1_Nebelschluss_Fzg_Anf 0;
BA_ "GenSigSendType" SG_ 981 BCM1_Nebelschluss_Fzg_Anf 0;
BA_ "GenSigSwitchedByIgnition" SG_ 981 BCM1_Schlusslicht_Anf 0;
BA_ "GenSigSendType" SG_ 981 BCM1_Schlusslicht_Anf 0;
BA_ "GenSigSwitchedByIgnition" SG_ 981 BCM_Rueckfahrlicht_Anf 0;
BA_ "GenSigSendType" SG_ 981 BCM_Rueckfahrlicht_Anf 0;
BA_ "GenSigSwitchedByIgnition" SG_ 981 BCM1_Signaturlicht_Anf 0;
BA_ "GenSigSendType" SG_ 981 BCM1_Signaturlicht_Anf 0;
BA_ "GenSigSwitchedByIgnition" SG_ 981 BCM1_Umfeldleuchten_Anf 0;
BA_ "GenSigSendType" SG_ 981 BCM1_Umfeldleuchten_Anf 0;
BA_ "GenSigSwitchedByIgnition" SG_ 981 BCM1_Tagfahrlicht_Anf 0;
BA_ "GenSigSendType" SG_ 981 BCM1_Tagfahrlicht_Anf 0;
BA_ "GenSigSwitchedByIgnition" SG_ 981 BCM1_Regenlicht_Anf 0;
BA_ "GenSigSendType" SG_ 981 BCM1_Regenlicht_Anf 0;
BA_ "GenSigSwitchedByIgnition" SG_ 981 BCM1_Autobahnlicht_Anf 0;
BA_ "GenSigSendType" SG_ 981 BCM1_Autobahnlicht_Anf 0;
BA_ "GenSigSwitchedByIgnition" SG_ 981 BCM1_Touristen_Licht_Anf 0;
BA_ "GenSigSendType" SG_ 981 BCM1_Touristen_Licht_Anf 0;
BA_ "GenSigSwitchedByIgnition" SG_ 981 BCM1_CH_aktiv 0;
BA_ "NWM-WakeupAllowed" SG_ 981 BCM1_CH_aktiv 1;
BA_ "GenSigSendType" SG_ 981 BCM1_CH_aktiv 0;
BA_ "GenSigSwitchedByIgnition" SG_ 981 BCM1_LH_aktiv 0;
BA_ "NWM-WakeupAllowed" SG_ 981 BCM1_LH_aktiv 1;
BA_ "GenSigSendType" SG_ 981 BCM1_LH_aktiv 0;
BA_ "GenSigSwitchedByIgnition" SG_ 981 BCM1_Gleitende_Leuchtw_Anf 0;
BA_ "GenSigSendType" SG_ 981 BCM1_Gleitende_Leuchtw_Anf 0;
BA_ "GenSigSwitchedByIgnition" SG_ 981 BCM1_GLW_Fernlicht_Anf 0;
BA_ "GenSigSendType" SG_ 981 BCM1_GLW_Fernlicht_Anf 0;
BA_ "GenSigSwitchedByIgnition" SG_ 981 BCM1_Adaptive_Lichtvert_Anf 0;
BA_ "GenSigSendType" SG_ 981 BCM1_Adaptive_Lichtvert_Anf 0;
BA_ "GenSigSwitchedByIgnition" SG_ 981 BCM1_CH_LH_aktiv 0;
BA_ "GenSigSendType" SG_ 981 BCM1_CH_LH_aktiv 0;
BA_ "GenSigSwitchedByIgnition" SG_ 981 BCM1_Allwetterlicht_Anf 0;
BA_ "GenSigSendType" SG_ 981 BCM1_Allwetterlicht_Anf 0;
BA_ "GenSigSwitchedByIgnition" SG_ 1624 LV_Standlicht_Anzeige 0;
BA_ "GenSigSendType" SG_ 1624 LV_Standlicht_Anzeige 3;
BA_ "GenSigSwitchedByIgnition" SG_ 1624 LV_Abblendlicht_Anzeige 0;
BA_ "GenSigSendType" SG_ 1624 LV_Abblendlicht_Anzeige 3;
BA_ "GenSigSwitchedByIgnition" SG_ 1624 LV_Fernlicht_Anzeige 0;
BA_ "GenSigSendType" SG_ 1624 LV_Fernlicht_Anzeige 3;
BA_ "GenSigSwitchedByIgnition" SG_ 1624 LV_Nebellicht_Anzeige 0;
BA_ "GenSigSendType" SG_ 1624 LV_Nebellicht_Anzeige 3;
BA_ "GenSigSwitchedByIgnition" SG_ 1624 LV_Nebelschlusslicht_Anzeige 0;
BA_ "GenSigSendType" SG_ 1624 LV_Nebelschlusslicht_Anzeige 3;
BA_ "GenSigSwitchedByIgnition" SG_ 1624 LV_Tagfahrlicht_Anzeige 0;
BA_ "GenSigSendType" SG_ 1624 LV_Tagfahrlicht_Anzeige 3;
BA_ "GenSigSwitchedByIgnition" SG_ 1624 LV_AFL_aktiv_Anzeige 0;
BA_ "GenSigSendType" SG_ 1624 LV_AFL_aktiv_Anzeige 3;
BA_ "GenSigSwitchedByIgnition" SG_ 1624 LV_AFL_defekt 0;
BA_ "GenSigSendType" SG_ 1624 LV_AFL_defekt 3;
BA_ "GenSigSwitchedByIgnition" SG_ 1624 LV_Blinker_li_def 0;
BA_ "GenSigSendType" SG_ 1624 LV_Blinker_li_def 0;
BA_ "GenSigSwitchedByIgnition" SG_ 1624 LV_Standlicht_li_def 0;
BA_ "GenSigSendType" SG_ 1624 LV_Standlicht_li_def 0;
BA_ "GenSigSwitchedByIgnition" SG_ 1624 LV_Abblendlicht_li_def 0;
BA_ "GenSigSendType" SG_ 1624 LV_Abblendlicht_li_def 0;
BA_ "GenSigSwitchedByIgnition" SG_ 1624 LV_Fernlicht_li_def 0;
BA_ "GenSigSendType" SG_ 1624 LV_Fernlicht_li_def 0;
BA_ "GenSigSwitchedByIgnition" SG_ 1624 LV_Nebellicht_li_def 0;
BA_ "GenSigSendType" SG_ 1624 LV_Nebellicht_li_def 0;
BA_ "GenSigSwitchedByIgnition" SG_ 1624 LV_Blk_li_Seite_def 0;
BA_ "GenSigSendType" SG_ 1624 LV_Blk_li_Seite_def 0;
BA_ "GenSigSwitchedByIgnition" SG_ 1624 LV_Tagfahrlicht_li_def 0;
BA_ "GenSigSendType" SG_ 1624 LV_Tagfahrlicht_li_def 0;
BA_ "GenSigSwitchedByIgnition" SG_ 1624 LV_FLA_aktiv_Anzeige 0;
BA_ "GenSigSendType" SG_ 1624 LV_FLA_aktiv_Anzeige 3;
BA_ "GenSigSwitchedByIgnition" SG_ 1624 LV_FLA_defekt 0;
BA_ "GenSigSendType" SG_ 1624 LV_FLA_defekt 0;
BA_ "GenSigSwitchedByIgnition" SG_ 1624 LV_FLA_Sensor_blockiert 0;
BA_ "GenSigSendType" SG_ 1624 LV_FLA_Sensor_blockiert 0;
BA_ "GenSigSwitchedByIgnition" SG_ 1624 LV_Blinker_re_def 0;
BA_ "GenSigSendType" SG_ 1624 LV_Blinker_re_def 0;
BA_ "GenSigSwitchedByIgnition" SG_ 1624 LV_Standlicht_re_def 0;
BA_ "GenSigSendType" SG_ 1624 LV_Standlicht_re_def 0;
BA_ "GenSigSwitchedByIgnition" SG_ 1624 LV_Abblendlicht_re_def 0;
BA_ "GenSigSendType" SG_ 1624 LV_Abblendlicht_re_def 0;
BA_ "GenSigSwitchedByIgnition" SG_ 1624 LV_Fernlicht_re_def 0;
BA_ "GenSigSendType" SG_ 1624 LV_Fernlicht_re_def 0;
BA_ "GenSigSwitchedByIgnition" SG_ 1624 LV_Nebellicht_re_def 0;
BA_ "GenSigSendType" SG_ 1624 LV_Nebellicht_re_def 0;
BA_ "GenSigSwitchedByIgnition" SG_ 1624 LV_Blk_re_Seite_def 0;
BA_ "GenSigSendType" SG_ 1624 LV_Blk_re_Seite_def 0;
BA_ "GenSigSwitchedByIgnition" SG_ 1624 LV_Tagfahrlicht_re_def 0;
BA_ "GenSigSendType" SG_ 1624 LV_Tagfahrlicht_re_def 0;
BA_ "GenSigSwitchedByIgnition" SG_ 1624 LV_Aussenlicht_def 0;
BA_ "GenSigSendType" SG_ 1624 LV_Aussenlicht_def 3;
BA_ "GenSigSwitchedByIgnition" SG_ 1624 LV_Abblendlicht_TFL_li_def 0;
BA_ "GenSigSendType" SG_ 1624 LV_Abblendlicht_TFL_li_def 0;
BA_ "GenSigSwitchedByIgnition" SG_ 1624 LV_Nebellicht_TFL_li_def 0;
BA_ "GenSigSendType" SG_ 1624 LV_Nebellicht_TFL_li_def 0;
BA_ "GenSigSwitchedByIgnition" SG_ 1624 LV_Standlicht_TFL_li_def 0;
BA_ "GenSigSendType" SG_ 1624 LV_Standlicht_TFL_li_def 0;
BA_ "GenSigSwitchedByIgnition" SG_ 1624 LV_Abblend_Fernlicht_li_def 0;
BA_ "GenSigSendType" SG_ 1624 LV_Abblend_Fernlicht_li_def 0;
BA_ "GenSigSwitchedByIgnition" SG_ 1624 LV_Abblendlicht_TFL_re_def 0;
BA_ "GenSigSendType" SG_ 1624 LV_Abblendlicht_TFL_re_def 0;
BA_ "GenSigSwitchedByIgnition" SG_ 1624 LV_Nebellicht_TFL_re_def 0;
BA_ "GenSigSendType" SG_ 1624 LV_Nebellicht_TFL_re_def 0;
BA_ "GenSigSwitchedByIgnition" SG_ 1624 LV_Standlicht_TFL_re_def 0;
BA_ "GenSigSendType" SG_ 1624 LV_Standlicht_TFL_re_def 0;
BA_ "GenSigSwitchedByIgnition" SG_ 1624 LV_Abblend_Fernlicht_re_def 0;
BA_ "GenSigSendType" SG_ 1624 LV_Abblend_Fernlicht_re_def 0;
BA_ "GenSigSwitchedByIgnition" SG_ 1624 LV_Abbiegelicht_li_def 0;
BA_ "GenSigSendType" SG_ 1624 LV_Abbiegelicht_li_def 0;
BA_ "GenSigSwitchedByIgnition" SG_ 1624 LV_Abbiegelicht_re_def 0;
BA_ "GenSigSendType" SG_ 1624 LV_Abbiegelicht_re_def 0;
BA_ "GenSigSwitchedByIgnition" SG_ 1624 BCM1_Linksverkehr 0;
BA_ "GenSigSendType" SG_ 1624 BCM1_Linksverkehr 0;
BA_ "GenSigSwitchedByIgnition" SG_ 1624 BCM1_Licht_Dunkelheit_aktiv 0;
BA_ "GenSigSendType" SG_ 1624 BCM1_Licht_Dunkelheit_aktiv 3;
BA_ "GenSigSwitchedByIgnition" SG_ 1624 LV_LED_Scheinwerfer_li_def 0;
BA_ "GenSigSendType" SG_ 1624 LV_LED_Scheinwerfer_li_def 0;
BA_ "GenSigSwitchedByIgnition" SG_ 1624 LV_LED_Scheinwerfer_re_def 0;
BA_ "GenSigSendType" SG_ 1624 LV_LED_Scheinwerfer_re_def 0;
BA_ "GenSigSwitchedByIgnition" SG_ 1624 LV_Blinker_VL_aktiv 0;
BA_ "GenSigSendType" SG_ 1624 LV_Blinker_VL_aktiv 3;
BA_ "GenSigSwitchedByIgnition" SG_ 1624 LV_Blinker_VR_aktiv 0;
BA_ "GenSigSendType" SG_ 1624 LV_Blinker_VR_aktiv 3;
BA_REL_ "GenSigTimeoutTime" BU_SG_REL_ Frontradar SG_ 792 Kamera_Systemzustand 800;
BA_REL_ "GenSigTimeoutTime" BU_SG_REL_ Frontradar SG_ 960 ZAS_Kl_15 1000;
BA_REL_ "GenSigTimeoutTime" BU_SG_REL_ Frontradar SG_ 779 Kombi_01_BZ 500;
BA_REL_ "GenSigTimeoutTime" BU_SG_REL_ Frontradar SG_ 779 KBI_Anzeigestatus_ACC 500;
BA_REL_ "GenSigTimeoutTime" BU_SG_REL_ Frontradar SG_ 779 KBI_MFA_v_Einheit_01 500;
BA_REL_ "GenSigTimeoutTime" BU_SG_REL_ Frontsensorik SG_ 779 KBI_MFA_v_Einheit_01 500;
BA_REL_ "GenSigTimeoutTime" BU_SG_REL_ Frontradar SG_ 779 KBI_Handbremse 500;
BA_REL_ "GenSigTimeoutTime" BU_SG_REL_ Frontradar SG_ 779 KBI_angez_Geschw 500;
BA_REL_ "GenSigTimeoutTime" BU_SG_REL_ Frontsensorik SG_ 779 KBI_angez_Geschw 500;
BA_REL_ "GenSigTimeoutTime" BU_SG_REL_ Frontradar SG_ 779 KBI_Einheit_Tacho 500;
BA_REL_ "GenSigTimeoutTime" BU_SG_REL_ Frontsensorik SG_ 779 KBI_Einheit_Tacho 500;
BA_REL_ "GenSigTimeoutTime" BU_SG_REL_ Frontradar SG_ 779 KBI_Konsistenz_ACC 500;
BA_REL_ "GenSigTimeoutTime" BU_SG_REL_ Frontradar SG_ 779 KBI_Fehler_Anzeige_ACC 500;
BA_REL_ "GenSigTimeoutTime" BU_SG_REL_ Frontsensorik SG_ 1719 KBI_QBit_Aussen_Temp_gef 5000;
BA_REL_ "GenSigTimeoutTime" BU_SG_REL_ Frontsensorik SG_ 1719 KBI_Aussen_Temp_gef 5000;
BA_REL_ "GenSigTimeoutTime" BU_SG_REL_ Frontradar SG_ 1720 KBI_Variante 5000;
BA_REL_ "GenSigTimeoutTime" BU_SG_REL_ Frontsensorik SG_ 159 EPS_03_CRC 500;
BA_REL_ "GenSigTimeoutTime" BU_SG_REL_ Frontsensorik SG_ 159 EPS_03_BZ 500;
BA_REL_ "GenSigTimeoutTime" BU_SG_REL_ Frontsensorik SG_ 159 EPS_Berechneter_LW 500;
BA_REL_ "GenSigTimeoutTime" BU_SG_REL_ Frontsensorik SG_ 159 EPS_BLW_QBit 500;
BA_REL_ "GenSigTimeoutTime" BU_SG_REL_ Frontsensorik SG_ 159 EPS_VZ_BLW 500;
BA_REL_ "GenSigTimeoutTime" BU_SG_REL_ Frontsensorik SG_ 159 EPS_HCA_Status 500;
BA_REL_ "GenSigTimeoutTime" BU_SG_REL_ Frontsensorik SG_ 159 EPS_Lenkmoment 500;
BA_REL_ "GenSigTimeoutTime" BU_SG_REL_ Frontsensorik SG_ 159 EPS_Lenkmoment_QBit 500;
BA_REL_ "GenSigTimeoutTime" BU_SG_REL_ Frontsensorik SG_ 159 EPS_VZ_Lenkmoment 500;
BA_REL_ "GenSigTimeoutTime" BU_SG_REL_ Frontsensorik SG_ 159 EPS_Lenkungstyp 500;
BA_REL_ "GenSigTimeoutTime" BU_SG_REL_ Frontsensorik SG_ 981 BCM1_Touristen_Licht_Anf 1000;
BA_REL_ "GenSigTimeoutTime" BU_SG_REL_ Frontsensorik SG_ 981 BCM1_Allwetterlicht_Anf 1000;
BA_REL_ "GenSigTimeoutTime" BU_SG_REL_ Frontsensorik SG_ 1624 LV_Abblendlicht_Anzeige 5000;
BA_REL_ "GenSigTimeoutTime" BU_SG_REL_ Frontsensorik SG_ 1624 LV_Fernlicht_Anzeige 5000;
BA_REL_ "GenSigTimeoutTime" BU_SG_REL_ Frontsensorik SG_ 1624 LV_Nebellicht_Anzeige 5000;
BA_REL_ "GenSigTimeoutTime" BU_SG_REL_ Frontsensorik SG_ 1624 LV_Nebelschlusslicht_Anzeige 5000;
BA_REL_ "GenSigTimeoutTime" BU_SG_REL_ Frontsensorik SG_ 1624 LV_AFL_aktiv_Anzeige 5000;
VAL_ 791 Kamera_FDD_Obj01_ID 254 "Init" 255 "nicht_verfuegbar" ;
VAL_ 791 Kamera_FDD_Obj01_Entf_Nah 0 "kein_Objekt" 1 "Objekt_0-10m" 2 "Objekt_11-20m" 3 "Objekt_21-30m" 4 "Objekt_31-40m" 5 "Objekt_41-50m" 6 "Objekt_51-60m" 7 "Objekt_61-70m" 8 "Objekt_71-80m" 9 "Objekt_81-90m" 10 "Objekt_91-100m" 11 "reserviert" 12 "reserviert" 13 "keine_Entfernungsschaetzung" 14 "Init" 15 "nicht_verfuegbar" ;
VAL_ 791 Kamera_FDD_Obj01_Typ 0 "kein_Objekt" 1 "Scheinwerfer" 2 "Rueckleuchte" 3 "Scheinwerferpaar" 4 "Rueckleuchtenpaar_PKW" 5 "Kalibriermuster_links" 6 "Kalibriermuster_rechts" 7 "Cluster" 8 "Strassenleuchte" 9 "Positionsleuchte" 10 "Reflektor" 11 "unklassifizierte_Leuchtquelle" 12 "Reflektion" 13 "Rueckleuchtenpaar_LKW" 14 "Init" 15 "nicht_verfuegbar" ;
VAL_ 791 Kamera_FDD_Obj01_horizPos 1022 "Init" 1023 "nicht_verfuegbar" ;
VAL_ 791 Kamera_FDD_Obj01_MehrAlsAchtObj 0 "8 Objekte oder weniger detektiert" 1 "mehr als 8 Objekte detektiert" 2 "Init" 3 "nicht_verfuegbar" ;
VAL_ 791 Kamera_FDD_Obj01_Ersatzw 0 "Messwert" 1 "Ersatzwert" 2 "Init" 3 "nicht_verfuegbar" ;
VAL_ 791 Kamera_FDD_Obj01_horizDim 1022 "Init" 1023 "nicht_verfuegbar" ;
VAL_ 791 Kamera_FDD_Obj01_vertPos 1022 "Init" 1023 "nicht_verfuegbar" ;
VAL_ 791 Kamera_FDD_Obj01_Entfernung 0 "kein_Objekt" 1 "Objekt_0-50m" 2 "Objekt_51-75m" 3 "Objekt_76-100m" 4 "Objekt_101-125m" 5 "Objekt_126-150m" 6 "Objekt_151-175m" 7 "Objekt_176-200m" 8 "Objekt_201-250m" 9 "Objekt_251-max" 13 "keine_Entfernungsschaetzung" 14 "Init" 15 "nicht_verfuegbar" ;
VAL_ 791 Kamera_FDD_Obj01_Objguete 0 "Guete <= 70%" 1 "70% < Guete <= 85%" 2 "85% < Guete <= 95%" 3 "95% < Guete <= 100%" ;
VAL_ 799 Kamera_FDD_Obj02_ID 254 "Init" 255 "nicht_verfuegbar" ;
VAL_ 799 Kamera_FDD_Obj02_Entf_Nah 0 "kein_Objekt" 1 "Objekt_0-10m" 2 "Objekt_11-20m" 3 "Objekt_21-30m" 4 "Objekt_31-40m" 5 "Objekt_41-50m" 6 "Objekt_51-60m" 7 "Objekt_61-70m" 8 "Objekt_71-80m" 9 "Objekt_81-90m" 10 "Objekt_91-100m" 11 "reserviert" 12 "reserviert" 13 "keine_Entfernungsschaetzung" 14 "Init" 15 "nicht_verfuegbar" ;
VAL_ 799 Kamera_FDD_Obj02_Typ 0 "kein_Objekt" 1 "Scheinwerfer" 2 "Rueckleuchte" 3 "Scheinwerferpaar" 4 "Rueckleuchtenpaar_PKW" 5 "Kalibriermuster_links" 6 "Kalibriermuster_rechts" 7 "Cluster" 8 "Strassenleuchte" 9 "Positionsleuchte" 10 "Reflektor" 11 "unklassifizierte_Leuchtquelle" 12 "Reflektion" 13 "Rueckleuchtenpaar_LKW" 14 "Init" 15 "nicht_verfuegbar" ;
VAL_ 799 Kamera_FDD_Obj02_horizPos 1022 "Init" 1023 "nicht_verfuegbar" ;
VAL_ 799 Kamera_FDD_Obj02_Ersatzw 0 "Messwert" 1 "Ersatzwert" 2 "Init" 3 "nicht_verfuegbar" ;
VAL_ 799 Kamera_FDD_Obj02_horizDim 1022 "Init" 1023 "nicht_verfuegbar" ;
VAL_ 799 Kamera_FDD_Obj02_vertPos 1022 "Init" 1023 "nicht_verfuegbar" ;
VAL_ 799 Kamera_FDD_Obj02_Entfernung 0 "kein_Objekt" 1 "Objekt_0-50m" 2 "Objekt_51-75m" 3 "Objekt_76-100m" 4 "Objekt_101-125m" 5 "Objekt_126-150m" 6 "Objekt_151-175m" 7 "Objekt_176-200m" 8 "Objekt_201-250m" 9 "Objekt_251-max" 13 "keine_Entfernungsschaetzung" 14 "Init" 15 "nicht_verfuegbar" ;
VAL_ 799 Kamera_FDD_Obj02_Objguete 0 "Guete <= 70%" 1 "70% < Guete <= 85%" 2 "85% < Guete <= 95%" 3 "95% < Guete <= 100%" ;
VAL_ 838 Kamera_FDD_Obj03_ID 254 "Init" 255 "nicht_verfuegbar" ;
VAL_ 838 Kamera_FDD_Obj03_Entf_Nah 0 "kein_Objekt" 1 "Objekt_0-10m" 2 "Objekt_11-20m" 3 "Objekt_21-30m" 4 "Objekt_31-40m" 5 "Objekt_41-50m" 6 "Objekt_51-60m" 7 "Objekt_61-70m" 8 "Objekt_71-80m" 9 "Objekt_81-90m" 10 "Objekt_91-100m" 11 "reserviert" 12 "reserviert" 13 "keine_Entfernungsschaetzung" 14 "Init" 15 "nicht_verfuegbar" ;
VAL_ 838 Kamera_FDD_Obj03_Typ 0 "kein_Objekt" 1 "Scheinwerfer" 2 "Rueckleuchte" 3 "Scheinwerferpaar" 4 "Rueckleuchtenpaar_PKW" 5 "Kalibriermuster_links" 6 "Kalibriermuster_rechts" 7 "Cluster" 8 "Strassenleuchte" 9 "Positionsleuchte" 10 "Reflektor" 11 "unklassifizierte_Leuchtquelle" 12 "Reflektion" 13 "Rueckleuchtenpaar_LKW" 14 "Init" 15 "nicht_verfuegbar" ;
VAL_ 838 Kamera_FDD_Obj03_horizPos 1022 "Init" 1023 "nicht_verfuegbar" ;
VAL_ 838 Kamera_FDD_Obj03_Ersatzw 0 "Messwert" 1 "Ersatzwert" 2 "Init" 3 "nicht_verfuegbar" ;
VAL_ 838 Kamera_FDD_Obj03_horizDim 1022 "Init" 1023 "nicht_verfuegbar" ;
VAL_ 838 Kamera_FDD_Obj03_vertPos 1022 "Init" 1023 "nicht_verfuegbar" ;
VAL_ 838 Kamera_FDD_Obj03_Entfernung 0 "kein_Objekt" 1 "Objekt_0-50m" 2 "Objekt_51-75m" 3 "Objekt_76-100m" 4 "Objekt_101-125m" 5 "Objekt_126-150m" 6 "Objekt_151-175m" 7 "Objekt_176-200m" 8 "Objekt_201-250m" 9 "Objekt_251-max" 13 "keine_Entfernungsschaetzung" 14 "Init" 15 "nicht_verfuegbar" ;
VAL_ 838 Kamera_FDD_Obj03_Objguete 0 "Guete <= 70%" 1 "70% < Guete <= 85%" 2 "85% < Guete <= 95%" 3 "95% < Guete <= 100%" ;
VAL_ 839 Kamera_FDD_Obj04_ID 254 "Init" 255 "nicht_verfuegbar" ;
VAL_ 839 Kamera_FDD_Obj04_Entf_Nah 0 "kein_Objekt" 1 "Objekt_0-10m" 2 "Objekt_11-20m" 3 "Objekt_21-30m" 4 "Objekt_31-40m" 5 "Objekt_41-50m" 6 "Objekt_51-60m" 7 "Objekt_61-70m" 8 "Objekt_71-80m" 9 "Objekt_81-90m" 10 "Objekt_91-100m" 11 "reserviert" 12 "reserviert" 13 "keine_Entfernungsschaetzung" 14 "Init" 15 "nicht_verfuegbar" ;
VAL_ 839 Kamera_FDD_Obj04_Typ 0 "kein_Objekt" 1 "Scheinwerfer" 2 "Rueckleuchte" 3 "Scheinwerferpaar" 4 "Rueckleuchtenpaar_PKW" 5 "Kalibriermuster_links" 6 "Kalibriermuster_rechts" 7 "Cluster" 8 "Strassenleuchte" 9 "Positionsleuchte" 10 "Reflektor" 11 "unklassifizierte_Leuchtquelle" 12 "Reflektion" 13 "Rueckleuchtenpaar_LKW" 14 "Init" 15 "nicht_verfuegbar" ;
VAL_ 839 Kamera_FDD_Obj04_horizPos 1022 "Init" 1023 "nicht_verfuegbar" ;
VAL_ 839 Kamera_FDD_Obj04_Ersatzw 0 "Messwert" 1 "Ersatzwert" 2 "Init" 3 "nicht_verfuegbar" ;
VAL_ 839 Kamera_FDD_Obj04_horizDim 1022 "Init" 1023 "nicht_verfuegbar" ;
VAL_ 839 Kamera_FDD_Obj04_vertPos 1022 "Init" 1023 "nicht_verfuegbar" ;
VAL_ 839 Kamera_FDD_Obj04_Entfernung 0 "kein_Objekt" 1 "Objekt_0-50m" 2 "Objekt_51-75m" 3 "Objekt_76-100m" 4 "Objekt_101-125m" 5 "Objekt_126-150m" 6 "Objekt_151-175m" 7 "Objekt_176-200m" 8 "Objekt_201-250m" 9 "Objekt_251-max" 13 "keine_Entfernungsschaetzung" 14 "Init" 15 "nicht_verfuegbar" ;
VAL_ 839 Kamera_FDD_Obj04_Objguete 0 "Guete <= 70%" 1 "70% < Guete <= 85%" 2 "85% < Guete <= 95%" 3 "95% < Guete <= 100%" ;
VAL_ 840 Kamera_FDD_Obj05_ID 254 "Init" 255 "nicht_verfuegbar" ;
VAL_ 840 Kamera_FDD_Obj05_Entf_Nah 0 "kein_Objekt" 1 "Objekt_0-10m" 2 "Objekt_11-20m" 3 "Objekt_21-30m" 4 "Objekt_31-40m" 5 "Objekt_41-50m" 6 "Objekt_51-60m" 7 "Objekt_61-70m" 8 "Objekt_71-80m" 9 "Objekt_81-90m" 10 "Objekt_91-100m" 11 "reserviert" 12 "reserviert" 13 "keine_Entfernungsschaetzung" 14 "Init" 15 "nicht_verfuegbar" ;
VAL_ 840 Kamera_FDD_Obj05_Typ 0 "kein_Objekt" 1 "Scheinwerfer" 2 "Rueckleuchte" 3 "Scheinwerferpaar" 4 "Rueckleuchtenpaar_PKW" 5 "Kalibriermuster_links" 6 "Kalibriermuster_rechts" 7 "Cluster" 8 "Strassenleuchte" 9 "Positionsleuchte" 10 "Reflektor" 11 "unklassifizierte_Leuchtquelle" 12 "Reflektion" 13 "Rueckleuchtenpaar_LKW" 14 "Init" 15 "nicht_verfuegbar" ;
VAL_ 840 Kamera_FDD_Obj05_horizPos 1022 "Init" 1023 "nicht_verfuegbar" ;
VAL_ 840 Kamera_FDD_Obj05_Ersatzw 0 "Messwert" 1 "Ersatzwert" 2 "Init" 3 "nicht_verfuegbar" ;
VAL_ 840 Kamera_FDD_Obj05_horizDim 1022 "Init" 1023 "nicht_verfuegbar" ;
VAL_ 840 Kamera_FDD_Obj05_vertPos 1022 "Init" 1023 "nicht_verfuegbar" ;
VAL_ 840 Kamera_FDD_Obj05_Entfernung 0 "kein_Objekt" 1 "Objekt_0-50m" 2 "Objekt_51-75m" 3 "Objekt_76-100m" 4 "Objekt_101-125m" 5 "Objekt_126-150m" 6 "Objekt_151-175m" 7 "Objekt_176-200m" 8 "Objekt_201-250m" 9 "Objekt_251-max" 13 "keine_Entfernungsschaetzung" 14 "Init" 15 "nicht_verfuegbar" ;
VAL_ 840 Kamera_FDD_Obj05_Objguete 0 "Guete <= 70%" 1 "70% < Guete <= 85%" 2 "85% < Guete <= 95%" 3 "95% < Guete <= 100%" ;
VAL_ 841 Kamera_FDD_Obj06_ID 254 "Init" 255 "nicht_verfuegbar" ;
VAL_ 841 Kamera_FDD_Obj06_Entf_Nah 0 "kein_Objekt" 1 "Objekt_0-10m" 2 "Objekt_11-20m" 3 "Objekt_21-30m" 4 "Objekt_31-40m" 5 "Objekt_41-50m" 6 "Objekt_51-60m" 7 "Objekt_61-70m" 8 "Objekt_71-80m" 9 "Objekt_81-90m" 10 "Objekt_91-100m" 11 "reserviert" 12 "reserviert" 13 "keine_Entfernungsschaetzung" 14 "Init" 15 "nicht_verfuegbar" ;
VAL_ 841 Kamera_FDD_Obj06_Typ 0 "kein_Objekt" 1 "Scheinwerfer" 2 "Rueckleuchte" 3 "Scheinwerferpaar" 4 "Rueckleuchtenpaar_PKW" 5 "Kalibriermuster_links" 6 "Kalibriermuster_rechts" 7 "Cluster" 8 "Strassenleuchte" 9 "Positionsleuchte" 10 "Reflektor" 11 "unklassifizierte_Leuchtquelle" 12 "Reflektion" 13 "Rueckleuchtenpaar_LKW" 14 "Init" 15 "nicht_verfuegbar" ;
VAL_ 841 Kamera_FDD_Obj06_horizPos 1022 "Init" 1023 "nicht_verfuegbar" ;
VAL_ 841 Kamera_FDD_Obj06_Ersatzw 0 "Messwert" 1 "Ersatzwert" 2 "Init" 3 "nicht_verfuegbar" ;
VAL_ 841 Kamera_FDD_Obj06_horizDim 1022 "Init" 1023 "nicht_verfuegbar" ;
VAL_ 841 Kamera_FDD_Obj06_vertPos 1022 "Init" 1023 "nicht_verfuegbar" ;
VAL_ 841 Kamera_FDD_Obj06_Entfernung 0 "kein_Objekt" 1 "Objekt_0-50m" 2 "Objekt_51-75m" 3 "Objekt_76-100m" 4 "Objekt_101-125m" 5 "Objekt_126-150m" 6 "Objekt_151-175m" 7 "Objekt_176-200m" 8 "Objekt_201-250m" 9 "Objekt_251-max" 13 "keine_Entfernungsschaetzung" 14 "Init" 15 "nicht_verfuegbar" ;
VAL_ 841 Kamera_FDD_Obj06_Objguete 0 "Guete <= 70%" 1 "70% < Guete <= 85%" 2 "85% < Guete <= 95%" 3 "95% < Guete <= 100%" ;
VAL_ 842 Kamera_FDD_Obj07_ID 254 "Init" 255 "nicht_verfuegbar" ;
VAL_ 842 Kamera_FDD_Obj07_Entf_Nah 0 "kein_Objekt" 1 "Objekt_0-10m" 2 "Objekt_11-20m" 3 "Objekt_21-30m" 4 "Objekt_31-40m" 5 "Objekt_41-50m" 6 "Objekt_51-60m" 7 "Objekt_61-70m" 8 "Objekt_71-80m" 9 "Objekt_81-90m" 10 "Objekt_91-100m" 11 "reserviert" 12 "reserviert" 13 "keine_Entfernungsschaetzung" 14 "Init" 15 "nicht_verfuegbar" ;
VAL_ 842 Kamera_FDD_Obj07_Typ 0 "kein_Objekt" 1 "Scheinwerfer" 2 "Rueckleuchte" 3 "Scheinwerferpaar" 4 "Rueckleuchtenpaar_PKW" 5 "Kalibriermuster_links" 6 "Kalibriermuster_rechts" 7 "Cluster" 8 "Strassenleuchte" 9 "Positionsleuchte" 10 "Reflektor" 11 "unklassifizierte_Leuchtquelle" 12 "Reflektion" 13 "Rueckleuchtenpaar_LKW" 14 "Init" 15 "nicht_verfuegbar" ;
VAL_ 842 Kamera_FDD_Obj07_horizPos 1022 "Init" 1023 "nicht_verfuegbar" ;
VAL_ 842 Kamera_FDD_Obj07_Ersatzw 0 "Messwert" 1 "Ersatzwert" 2 "Init" 3 "nicht_verfuegbar" ;
VAL_ 842 Kamera_FDD_Obj07_horizDim 1022 "Init" 1023 "nicht_verfuegbar" ;
VAL_ 842 Kamera_FDD_Obj07_vertPos 1022 "Init" 1023 "nicht_verfuegbar" ;
VAL_ 842 Kamera_FDD_Obj07_Entfernung 0 "kein_Objekt" 1 "Objekt_0-50m" 2 "Objekt_51-75m" 3 "Objekt_76-100m" 4 "Objekt_101-125m" 5 "Objekt_126-150m" 6 "Objekt_151-175m" 7 "Objekt_176-200m" 8 "Objekt_201-250m" 9 "Objekt_251-max" 13 "keine_Entfernungsschaetzung" 14 "Init" 15 "nicht_verfuegbar" ;
VAL_ 842 Kamera_FDD_Obj07_Objguete 0 "Guete <= 70%" 1 "70% < Guete <= 85%" 2 "85% < Guete <= 95%" 3 "95% < Guete <= 100%" ;
VAL_ 843 Kamera_FDD_Obj08_ID 254 "Init" 255 "nicht_verfuegbar" ;
VAL_ 843 Kamera_FDD_Obj08_Entf_Nah 0 "kein_Objekt" 1 "Objekt_0-10m" 2 "Objekt_11-20m" 3 "Objekt_21-30m" 4 "Objekt_31-40m" 5 "Objekt_41-50m" 6 "Objekt_51-60m" 7 "Objekt_61-70m" 8 "Objekt_71-80m" 9 "Objekt_81-90m" 10 "Objekt_91-100m" 11 "reserviert" 12 "reserviert" 13 "keine_Entfernungsschaetzung" 14 "Init" 15 "nicht_verfuegbar" ;
VAL_ 843 Kamera_FDD_Obj08_Typ 0 "kein_Objekt" 1 "Scheinwerfer" 2 "Rueckleuchte" 3 "Scheinwerferpaar" 4 "Rueckleuchtenpaar_PKW" 5 "Kalibriermuster_links" 6 "Kalibriermuster_rechts" 7 "Cluster" 8 "Strassenleuchte" 9 "Positionsleuchte" 10 "Reflektor" 11 "unklassifizierte_Leuchtquelle" 12 "Reflektion" 13 "Rueckleuchtenpaar_LKW" 14 "Init" 15 "nicht_verfuegbar" ;
VAL_ 843 Kamera_FDD_Obj08_horizPos 1022 "Init" 1023 "nicht_verfuegbar" ;
VAL_ 843 Kamera_FDD_Obj08_Ersatzw 0 "Messwert" 1 "Ersatzwert" 2 "Init" 3 "nicht_verfuegbar" ;
VAL_ 843 Kamera_FDD_Obj08_horizDim 1022 "Init" 1023 "nicht_verfuegbar" ;
VAL_ 843 Kamera_FDD_Obj08_vertPos 1022 "Init" 1023 "nicht_verfuegbar" ;
VAL_ 843 Kamera_FDD_Obj08_Entfernung 0 "kein_Objekt" 1 "Objekt_0-50m" 2 "Objekt_51-75m" 3 "Objekt_76-100m" 4 "Objekt_101-125m" 5 "Objekt_126-150m" 6 "Objekt_151-175m" 7 "Objekt_176-200m" 8 "Objekt_201-250m" 9 "Objekt_251-max" 13 "keine_Entfernungsschaetzung" 14 "Init" 15 "nicht_verfuegbar" ;
VAL_ 843 Kamera_FDD_Obj08_Objguete 0 "Guete <= 70%" 1 "70% < Guete <= 85%" 2 "85% < Guete <= 95%" 3 "95% < Guete <= 100%" ;
VAL_ 844 Kamera_FDD_SL_01_ID 0 "Init" 1 "Strassenleuchte_ID_1" 2 "Strassenleuchte_ID_2" 3 "nicht_verfuegbar" ;
VAL_ 844 Kamera_FDD_SL_01_horizPos 1022 "Init" 1023 "nicht_verfuegbar" ;
VAL_ 844 Kamera_FDD_SL_01_vertPos 1022 "Init" 1023 "nicht_verfuegbar" ;
VAL_ 844 Kamera_FDD_SL_01_Typ 0 "keine_Strassenleuchte_erkannt" 1 "Strassenleuchte" 2 "Init" 3 "nicht_verfuegbar" ;
VAL_ 844 Kamera_FDD_SL_01_Objguete 0 "0_Bis_60_Prozent" 1 "60_Bis_75_Prozent" 2 "75_Bis_90_Prozent" 3 "90_Bis_100_Prozent" ;
VAL_ 844 Kamera_FDD_SL_01_Ersatzw 0 "Messwert" 1 "Ersatzwert" 2 "Init" 3 "Fehler" ;
VAL_ 845 Kamera_FDD_SL_02_ID 0 "Init" 1 "Strassenleuchte_ID_1" 2 "Strassenleuchte_ID_2" 3 "nicht_verfuegbar" ;
VAL_ 845 Kamera_FDD_SL_02_horizPos 1022 "Init" 1023 "nicht_verfuegbar" ;
VAL_ 845 Kamera_FDD_SL_02_vertPos 1022 "Init" 1023 "nicht_verfuegbar" ;
VAL_ 845 Kamera_FDD_SL_02_Typ 0 "keine_Strassenleuchte_erkannt" 1 "Strassenleuchte" 2 "Init" 3 "nicht_verfuegbar" ;
VAL_ 845 Kamera_FDD_SL_02_Objguete 0 "0_Bis_60_Prozent" 1 "60_Bis_75_Prozent" 2 "75_Bis_90_Prozent" 3 "90_Bis_100_Prozent" ;
VAL_ 845 Kamera_FDD_SL_02_Ersatzw 0 "Messwert" 1 "Ersatzwert" 2 "Init" 3 "Fehler" ;
VAL_ 792 Kamera_Systemzustand 0 "Kamera_operativ" 1 "Kamera_Initialisierung" 2 "Kamera_schaltet_ab" 3 "Kamera_Fehler" ;
VAL_ 792 Kamera_FDD_Eigenblend_Guete 14 "Init" 15 "Fehler" ;
VAL_ 792 Kamera_FDD_Eigenblend 0 "Keine_Eigenblendung_erkannt" 1 "Eigenblendung_erkannt" ;
VAL_ 792 Kamera_FDD_Strassenbeleuchung 0 "keine_Strassenbeleuchtung" 1 "Strassenbeleuchtung" 2 "Strassenleuchte" 3 "nicht_verfuegbar" ;
VAL_ 792 Kamera_FDD_Funktionsstatus 0 "FDD_ein_aktiv" 1 "FDD_ein_passiv" 2 "FDD_ein_Einschraenkung_Sicht" 3 "FDD_ein_Fehler_HW_SW" 4 "FDD_aus" 6 "Init" ;
VAL_ 792 Kamera_FDD_Anz_Strassenleuchten 15 "Init" ;
VAL_ 792 Kamera_FDD_Verkehrsrichtung 0 "rechtsverkehr" 1 "linksverkehr" 2 "Init" 3 "nicht verfuegbar" ;
VAL_ 792 Kamera_FSH_aktiv 0 "Kamera_Frontscheibenheizung_nicht_aktiviert" 1 "Kamera_Frontscheibenheizung_aktiviert" ;
VAL_ 960 RSt_Fahrerhinweise 0 "Init" 1 "Fahreruebernahme_Hinweis_ZAT_Automat_ohne_Gong" 2 "Fahreruebernahme_Hinweis_ZAT_Automat_mit_Gong" 3 "Fahreruebernahme_Hinweis_ZAT_Handschalter_ohne_Gong" 4 "Fahreruebernahme_Hinweis_ZAT_Handschalter_mit_Gong" 5 "Fahreruebernahme_Hinweis_ZAS_Automat_ohne_Gong" 6 "Fahreruebernahme_Hinweis_ZAS_Automat_mit_Gong" 7 "Fahreruebernahme_Hinweis_ZAS_Handschalter_ohne_Gong" 8 "Fahreruebernahme_Hinweis_ZAS_Handschalter_mit_Gong" 9 "RemoteStart_aktiv_ohne_Gong" 10 "RemoteStart_aktiv_mit_Gong" 11 "void" 12 "void" 13 "void" 14 "void" 15 "void" ;
VAL_ 960 ZAS_Kl_S 0 "aus" 1 "S_Kontakt_ein" ;
VAL_ 960 ZAS_Kl_15 0 "aus" 1 "ein" ;
VAL_ 960 ZAS_Kl_X 0 "aus" 1 "ein" ;
VAL_ 960 ZAS_Kl_50_Startanforderung 0 "aus" 1 "KL50_ein_Startwunsch_Fahrer" ;
VAL_ 960 BCM_Remotestart_Betrieb 0 "kein_RS_Betrieb" 1 "RS_Betrieb" ;
VAL_ 960 ZAS_Kl_Infotainment 0 "inaktiv" 1 "aktiv" ;
VAL_ 960 BCM_Remotestart_KL15_Anf 0 "inaktiv" 1 "aktiv" ;
VAL_ 960 BCM_Remotestart_MO_Start 0 "nicht_angefordert" 1 "angefordert" ;
VAL_ 960 KST_Warn_P1_ZST_def 0 "nicht_defekt" 1 "defekt" ;
VAL_ 960 KST_Warn_P2_ZST_def 0 "nicht_defekt" 1 "defekt" ;
VAL_ 960 KST_Fahrerhinweis_1 0 "inaktiv" 1 "aktiv" ;
VAL_ 960 KST_Fahrerhinweis_2 0 "inaktiv" 1 "aktiv" ;
VAL_ 960 KST_Fahrerhinweis_3 0 "inaktiv" 1 "aktiv" ;
VAL_ 960 KST_Fahrerhinweis_4 0 "inaktiv" 1 "aktiv" ;
VAL_ 960 KST_Fahrerhinweis_5 0 "inaktiv" 1 "aktiv" ;
VAL_ 960 KST_Fahrerhinweis_6 0 "inaktiv" 1 "aktiv" ;
VAL_ 1646 KL_STL_aktiv 0 "Standlueftung_nicht_aktiv" 1 "Standlueftung_aktiv" ;
VAL_ 1646 KL_STH_aktiv 0 "Standheizung_nicht_aktiv" 1 "Standheizung_aktiv" ;
VAL_ 1646 KL_Solarluefter_aktiv 0 "Solarluefter_nicht_aktiv" 1 "Solarluefter_aktiv__auto" ;
VAL_ 1646 KL_Umluft_Taste 0 "Taste_nicht_gedrueckt" 1 "Taste_gedrueckt" ;
VAL_ 1646 KL_Geblaese_Fond_Status 0 "Geblaese_aus" 1 "Geblaesestufe_10" 2 "Geblaesestufe_20" 3 "Geblaesestufe_30" 4 "Geblaesestufe_40" 5 "Geblaesestufe_50" 6 "Geblaesestufe_60" 7 "Geblaesestufe_70" 8 "Geblaesestufe_80" 9 "Geblaesestufe_90" 10 "Geblaesestufe_100" 14 "Init" 15 "Fehler" ;
VAL_ 1646 KL_STH_Ansteuerung 0 "Aus" 1 "Ein" 2 "Ein_mit_Motorvorwaermung" 3 "Heizleistung_reduziert" ;
VAL_ 1646 KL_Magnetventil 0 "Aus" 1 "Ein" ;
VAL_ 1646 KL_WaPu 0 "Wasserpumpe_aus" 1 "Wasserpumpe_aktiv" ;
VAL_ 1646 KL_Geblaese_Status 0 "Geblaese_aus" 1 "Geblaesestufe_10" 2 "Geblaesestufe_20" 3 "Geblaesestufe_30" 4 "Geblaesestufe_40" 5 "Geblaesestufe_50" 6 "Geblaesestufe_60" 7 "Geblaesestufe_70" 8 "Geblaesestufe_80" 9 "Geblaesestufe_90" 10 "Geblaesestufe_100" 14 "Init" 15 "Fehler" ;
VAL_ 1646 KL_Restwaerme_aktiv 0 "inaktiv" 1 "aktiv" ;
VAL_ 1646 KL_Kompressorkupplung 0 "oeffnen" 1 "schliessen" ;
VAL_ 1646 KL_BCmE_Livetip_Freigabe 0 "Anzeige_Livetip_nicht_zulaessig" 1 "Anzeige_Livetip_zulaessig" ;
VAL_ 1646 KL_Innen_Temp 253 "nicht_verbaut" 254 "nicht_verfuegbar" 255 "Fehler" ;
VAL_ 1646 KL_I_Geblaese_Fond 255 "Fehler" ;
VAL_ 1646 KL_Heizkreisventilstellung 0 "Init" 1 "Ventilstellung_gem_Anforderung" 2 "Ventilstellung_abweichend_Anf" 3 "Fehler" ;
VAL_ 1646 KL_FSH_Automatikbetrieb 0 "aus" 1 "angefordert_durch_Regelung" ;
VAL_ 1646 KL_SIH_LEH_Verteilung_VL 0 "gleichmaessige_Verteilung" 1 "Sitz_Prio_Hoch" 2 "Sitz_Prio_Mittel" 3 "Sitz_Prio_Niedrig" 4 "Lehne_Prio_Niedrig" 5 "Lehne_Prio_Mittel" 6 "Lehne_Prio_Hoch" ;
VAL_ 1646 KL_SIH_LEL_Verteilung_VL 0 "gleichmaessige_Verteilung" 1 "Sitz_Prio_Hoch" 2 "Sitz_Prio_Mittel" 3 "Sitz_Prio_Niedrig" 4 "Lehne_Prio_Niedrig" 5 "Lehne_Prio_Mittel" 6 "Lehne_Prio_Hoch" ;
VAL_ 1646 KL_SIH_LEH_Verteilung_VR 0 "gleichmaessige_Verteilung" 1 "Sitz_Prio_Hoch" 2 "Sitz_Prio_Mittel" 3 "Sitz_Prio_Niedrig" 4 "Lehne_Prio_Niedrig" 5 "Lehne_Prio_Mittel" 6 "Lehne_Prio_Hoch" ;
VAL_ 1646 KL_SIH_LEL_Verteilung_VR 0 "gleichmaessige_Verteilung" 1 "Sitz_Prio_Hoch" 2 "Sitz_Prio_Mittel" 3 "Sitz_Prio_Niedrig" 4 "Lehne_Prio_Niedrig" 5 "Lehne_Prio_Mittel" 6 "Lehne_Prio_Hoch" ;
VAL_ 949 KL_Drehz_Anh 0 "keine_Anhebung" 1 "Drehzahlanhebung_vom_Motor_angefordert" ;
VAL_ 949 KL_Vorwarn_Komp_ein 0 "Init" 1 "Vorwarnung_Kompressor_ein" ;
VAL_ 949 KL_AC_Schalter 0 "aus" 1 "ein" ;
VAL_ 949 KL_Komp_Moment_alt 1 "veraltet_bzw_Ermittlung_des_Moments_nicht_moeglich__zB_keine_Drehzahl_kein_Kaeltemitteldruck" ;
VAL_ 949 KL_Vorwarn_Zuheizer_ein 0 "keine_Vorwarnung" 1 "Vorwarnung_Zuheizer_ein" ;
VAL_ 949 KL_Zustand 0 "Aus" 1 "Ein" ;
VAL_ 949 KL_Kompressorkupplung_linear 253 "volle_Ansteuerung" 254 "Init__nicht_bedient" ;
VAL_ 949 KL_Charisma_FahrPr 0 "keine_Funktion" 1 "Programm_1" 2 "Programm_2" 3 "Programm_3" 4 "Programm_4" 5 "Programm_5" 6 "Programm_6" 7 "Programm_7" 8 "Programm_8" 9 "Programm_9" 10 "Programm_10" 11 "Programm_11" 12 "Programm_12" 13 "Programm_13" 14 "Programm_14" 15 "Programm_15" ;
VAL_ 949 KL_Charisma_Status 0 "Init" 1 "verfuegbar" 2 "nicht_verfuegbar" 3 "asynchron_durch_Fahrerwunsch" ;
VAL_ 949 KL_nachtr_Stopp_Anf 0 "nicht_angefordert" 1 "angefordert" ;
VAL_ 949 KL_T_Charge 0 "Taster_nicht_betaetigt" 1 "Taster_betaetigt" ;
VAL_ 949 KL_Last_Kompr 255 "Fehler" ;
VAL_ 949 KL_Spannungs_Anf 0 "keine_Anforderung" 1 "Anforderung_Stufe_1" 2 "Anforderung_Stufe_2" 3 "Anforderung_Stufe_3" ;
VAL_ 949 KL_Thermomanagement 0 "keine_Freigabe_TMM__max_Heizbedarf" 1 "kleine_Freigabe_TMM" 2 "mittlere_Freigabe_TMM" 3 "volle_Freigabe_TMM__kein_Heizbedarf" ;
VAL_ 949 KL_StartStopp_Info 0 "Motorlauf_nicht_notwendig_(Stoppfreigabe)" 1 "Motoranlauf_nicht_zwingend_notwendig_(Stoppverbot,keine_Startanforderung)" 2 "Motoranlauf_zwingend_notwendig_(Startanforderung)" 3 "Systemfehler" ;
VAL_ 949 KL_Freilauf_Info 0 "Freilauf_freigegeben" 1 "Uebergang_in_Freilauf_unzulaessig" 2 "Freilauf_nicht_freigegeben_Abbruch" 3 "Freilauf_Anforderung" ;
VAL_ 949 KL_Anf_KL 255 "Fehler" ;
VAL_ 949 KL_el_Zuheizer_Stufe 0 "Aus" 1 "Stufe_1" 2 "Stufe_2" 3 "Stufe_3" ;
VAL_ 949 KL_Ausstattung_Klima 0 "Heizung_elektrisch" 1 "Klimamanuell_elektrisch" 2 "Climatic__1_Zone" 3 "Climatronic__1_Zone" 4 "Climatronic__2_Zonen" 5 "Climatronic__3_Zonen" 6 "Climatronic__4_Zonen" 7 "reserviert" ;
VAL_ 949 KL_Variante_Standheizung 0 "Wasserstandheizung_60_min_Laufzeit" 1 "Luftstandheizung_120_min_Laufzeit" 2 "Wasserstandheizung_120_min_Laufzeit" 3 "Wasser_und_Luftstandheizung_120_min_Laufzeit" ;
VAL_ 1511 KL_HV_Heizer_Strom 255 "Init" ;
VAL_ 1511 KL_EKK_Strom 255 "Init" ;
VAL_ 1511 KL_Pumpe_02_Soll 126 "Init" 127 "Fehler" ;
VAL_ 1511 KL_Ventil_03_Soll 0 "nicht_ansteuern" 1 "Ventil_ansteuern" ;
VAL_ 1511 KL_Ventil_10_Status 0 "Ventil_nicht_angesteuert" 1 "Ventil_angesteuert" 2 "reserviert" 3 "reserviert" 4 "reserviert" 5 "Ventil_nicht_verbaut" 6 "Init" 7 "Fehler" ;
VAL_ 1511 KL_Senderkennung 0 "Sender Climatronic SG" 1 "Sender Waermepumpen SG" ;
VAL_ 1511 WP_KJ_Soll 0 "Init_Keine_Anforderung" 1 "KJ_oeffnen" 2 "KJ_schliessen" 3 "Fehler" ;
VAL_ 1511 KL_Fehler_HV_EKK 0 "Init" 1 "Kein HV Fehler am EKK erkannt" 2 "HV Fehler am EKK erkannt" 3 "Fehler" ;
VAL_ 1511 KL_Fehler_HV_Heizer 0 "Init" 1 "Kein HV Fehler am HV Heizer erkannt" 2 "HV Fehler am HV Heizer erkannt" 3 "Fehler" ;
VAL_ 1511 KL_BattKond_WaPu_DZMax 62 "Init" 63 "Fehler" ;
VAL_ 1511 WP_Kuehlerluefter_Anf 255 "Fehler" ;
VAL_ 1511 KL_KM_ASV_01_Status 0 "Ventil nicht geschaltet" 1 "Ventil geschaltet" 2 "Ventil nicht verbaut" 3 "Fehler" ;
VAL_ 1511 KL_KM_ASV_02_Status 0 "Ventil nicht geschaltet" 1 "Ventil geschaltet" 2 "Ventil nicht verbaut" 3 "Fehler" ;
VAL_ 1514 KL_Kundenwunsch_Kuehlen 0 "Keine_Kuehlung_gewuenscht" 1 "Kuehlung_gewuenscht" ;
VAL_ 1514 KL_OBD_Status 0 "MILaus" 1 "MILan" ;
VAL_ 1514 KL_KLE_Fehler_Anf 0 "inaktiv" 1 "aktiv" ;
VAL_ 1514 KL_Fehler_NTKreis 0 "KeinFehler" 1 "Fehler" ;
VAL_ 1514 KL_VK_Anf 0 "keine_Startanf_von_Climatronic" 1 "Startanf_via_FFB" 2 "Startanf_via_Sofortheiztaste" 3 "VK_Strategie_STH" 4 "Reserve" 5 "Reserve" 6 "Init" 7 "Fehler" ;
VAL_ 1514 KL_Standklima_Status_02 0 "nicht_aktiv" 1 "aktiv" 2 "eingeschraenkt_aktiv" 3 "Abbruch_durch_Benutzer" 4 "nicht_moeglich" 5 "Aussenhuelle_offen" 6 "Init" 7 "Fehler" ;
VAL_ 1514 KL_Standklima_RemoteModus 0 "Init__nicht_aktiv" 1 "Lueften" 2 "Kuehlen" 3 "Heizen" 4 "reserviert" 5 "reserviert" 6 "reserviert" 7 "reserviert" ;
VAL_ 1514 KBT_Defrost_aktiv 0 "inaktiv" 1 "aktiv" ;
VAL_ 1514 KL_VK_Betriebsdauer 62 "Init" 63 "Fehler" ;
VAL_ 1514 KL_Heizbedarf 0 "Kein_Heizbedarf" 1022 "Init" 1023 "Fehler" ;
VAL_ 1514 KL_Innentemp_KBT_Sensor 1022 "Init" 1023 "Fehler" ;
VAL_ 1514 KL_Vorkond_Strategie 0 "Aus" 1 "Spülen" 2 "Kanalkühlung" 3 "Kühlwasserzirkulation" 4 "Aktive Kühlung" 5 "Heizen" 6 "Reheat" 7 "Heizen_elektrisch" 8 "Heizen_verbrennungstechnisch" 14 "Konditionierung_nicht_moeglich" 15 "Init" ;
VAL_ 1515 KL_Abl_Soll_li 254 "Init" 255 "Fehler" ;
VAL_ 1515 KL_Abl_Soll_re 254 "Init" 255 "Fehler" ;
VAL_ 1515 KL_Verdampfer_Soll 254 "Init" 255 "Fehler" ;
VAL_ 1515 KL_Abl_Ist_li 1022 "Init" 1023 "Fehler" ;
VAL_ 1515 KL_Abl_Ist_re 1022 "Init" 1023 "Fehler" ;
VAL_ 1515 KL_TaupEps_Korr 1022 "Init" 1023 "Fehler" ;
VAL_ 1712 FS_Taupunkt 0 "nicht verfuegbar" 1023 "Fehler" ;
VAL_ 1712 FS_ResponseError 0 "normal" 1 "Fehler" ;
VAL_ 1712 FS_Temp_Scheibe 0 "nicht verfuegbar" 1023 "Fehler" ;
VAL_ 1712 FS_Temp_Sensor 0 "nicht verfuegbar" 255 "Fehler" ;
VAL_ 1712 FS_Luftfeuchte_rel 0 "nicht verfuegbar" 255 "Fehler" ;
VAL_ 1717 FSA_Taupunkt 1021 "nicht_verbaut" 1022 "Init" 1023 "Fehler" ;
VAL_ 1717 FSA_ResponseError 0 "normal" 1 "Fehler" ;
VAL_ 1717 FSA_Temp_Luft 1021 "nicht_verbaut" 1022 "Init" 1023 "Fehler" ;
VAL_ 1717 FSA_Luftfeuchte_rel 253 "nicht_verbaut" 254 "Init" 255 "Fehler" ;
VAL_ 1717 FSA_Temp_Sensor 2045 "nicht_verbaut" 2046 "Init" 2047 "Fehler" ;
VAL_ 1717 FSA_Sensorheizung_Status 0 "inaktiv" 1 "aktiv" ;
VAL_ 2549088343 ACC_KompSchutz 0 "inaktiv" 1 "aktiv" ;
VAL_ 2549088343 ACC_Abschaltstufe 0 "keine_Einschraenkung" 1 "Funktionseinschraenkung" ;
VAL_ 2549088343 ACC_Transport_Mode 0 "keine_Einschraenkung" 1 "Funktionseinschraenkung" ;
VAL_ 2549088343 ACC_Nachlauftyp 0 "Komm_bei_KL15_EIN" 1 "Komm_nach_KL15_AUS" 2 "Komm_bei_KL15_AUS" ;
VAL_ 2549088343 ACC_SNI 87 "ACC" ;
VAL_ 2549088343 ACC_KD_Fehler 0 "kein_KD_Fehler" 1 "KD_Fehler" ;
VAL_ 2549088304 FLA_KompSchutz 0 "inaktiv" 1 "aktiv" ;
VAL_ 2549088304 FLA_Abschaltstufe 0 "keine_Einschraenkung" 1 "Funktionseinschraenkung" ;
VAL_ 2549088304 FLA_Transport_Mode 0 "keine_Einschraenkung" 1 "Funktionseinschraenkung" ;
VAL_ 2549088304 FLA_Nachlauftyp 0 "Komm_bei_KL15_EIN" 1 "Komm_nach_KL15_AUS" 2 "Komm_bei_KL15_AUS" ;
VAL_ 2549088304 FLA_SNI 48 "FLA" ;
VAL_ 2549088304 FLA_KD_Fehler 0 "kein_KD_Fehler" 1 "KD_Fehler" ;
VAL_ 2549088335 Kamera_KompSchutz 0 "inaktiv" 1 "aktiv" ;
VAL_ 2549088335 Kamera_Abschaltstufe 0 "keine_Einschraenkung" 1 "Funktionseinschraenkung" ;
VAL_ 2549088335 Kamera_Transport_Mode 0 "keine_Einschraenkung" 1 "Funktionseinschraenkung" ;
VAL_ 2549088335 Kamera_Nachlauftyp 0 "Komm_bei_KL15_EIN" 1 "Komm_nach_KL15_AUS" 2 "Komm_bei_KL15_AUS" ;
VAL_ 2549088335 Kamera_SNI 79 "Kamera" ;
VAL_ 2549088335 Kamera_KD_Fehler 0 "kein_KD_Fehler" 1 "KD_Fehler" ;
VAL_ 2549088340 LWRAFS_KompSchutz 0 "inaktiv" 1 "aktiv" ;
VAL_ 2549088340 LWRAFS_Abschaltstufe 0 "keine_Einschraenkung" 1 "Funktionseinschraenkung" ;
VAL_ 2549088340 LWRAFS_Transport_Mode 0 "keine_Einschraenkung" 1 "Funktionseinschraenkung" ;
VAL_ 2549088340 LWRAFS_Nachlauftyp 0 "Komm_bei_KL15_EIN" 1 "Komm_nach_KL15_AUS" 2 "Komm_bei_KL15_AUS" ;
VAL_ 2549088340 LWRAFS_SNI 84 "LWRAFS" ;
VAL_ 2549088340 LWR_KD_Fehler 0 "kein_KD_Fehler" 1 "KD_Fehler" ;
VAL_ 2549088334 SWA_KompSchutz 0 "inaktiv" 1 "aktiv" ;
VAL_ 2549088334 SWA_Abschaltstufe 0 "keine_Einschraenkung" 1 "Funktionseinschraenkung" ;
VAL_ 2549088334 SWA_Transport_Mode 0 "keine_Einschraenkung" 1 "Funktionseinschraenkung" ;
VAL_ 2549088334 SWA_Nachlauftyp 0 "Komm_bei_KL15_EIN" 1 "Komm_nach_KL15_AUS" 2 "Komm_bei_KL15_AUS" ;
VAL_ 2549088334 SWA_SNI 78 "SWA" ;
VAL_ 2549088334 KN_SWA_BusKnockOutTimer 255 "BusKnockOut_deaktiviert" ;
VAL_ 2549088334 SWA_KD_Fehler 0 "kein_KD_Fehler" 1 "KD_Fehler" ;
VAL_ 779 KBI_ABS_Lampe 0 "ABS Lampe aus" 1 "ABS Lampe ein" ;
VAL_ 779 KBI_ESP_Lampe 0 "ESP Lampe aus" 1 "ESP Lampe ein" ;
VAL_ 779 KBI_BKL_Lampe 0 "BKL aus" 1 "BKL ein" ;
VAL_ 779 KBI_Airbag_Lampe 0 "Airbag Lampe aus" 1 "Airbag Lampe ein" ;
VAL_ 779 KBI_SILA_gueltig 0 "ungueltig" 1 "gueltig" ;
VAL_ 779 KBI_Vorglueh_System_Lampe 0 "Lampe aus" 1 "Lampe ein" ;
VAL_ 779 KBI_NV_in_Anzeige 0 "NV_nicht_in_Anzeige" 1 "NV_in_Anzeige" ;
VAL_ 779 KBI_Anzeigestatus_ACC 0 "keine_ACC_Anzeige" 1 "ACC_Anzeige_aktiv" ;
VAL_ 779 KBI_Anzeigestatus_GRA 0 "nicht_vorhanden" 1 "Anzeigemoeglichkeit_vorhanden" 2 "reserviert" 3 "Fehler" ;
VAL_ 779 KBI_Oeldruck_Schalter 0 "offen____p_kleiner_pnenn" 1 "geschlossen____p_groessergleich_pnenn" ;
VAL_ 779 KBI_Tankwarnung 0 "Lampe aus" 1 "Lampe ein" ;
VAL_ 779 KBI_MFA_v_Einheit_01 0 "kmh" 1 "mph" ;
VAL_ 779 KBI_im_Stellgliedtest 0 "kein Stellgliedtest" 1 "Kombi im Stellgliedtest" ;
VAL_ 779 KBI_Anzeigefehler_LDW 0 "nicht vorhanden bzw. unterstützt" 1 "Anzeige iO" 2 "Anzeigefehler" 3 "nicht definiert" ;
VAL_ 779 KBI_Oeldruckwarnung 0 "inaktiv" 1 "aktiv" ;
VAL_ 779 KBI_Handbremse 0 "nicht_angezogen" 1 "angezogen" ;
VAL_ 779 KBI_PLA_in_Anzeige 0 "PLA_nicht_in_Anzeige" 1 "PLA_in_Anzeige" ;
VAL_ 779 KBI_Anzeigefehler_NV 0 "kein_Anzeigefehler" 1 "Anzeigefehler" ;
VAL_ 779 KBI_Anzeigestatus_LIM 0 "nicht_vorhanden" 1 "Anzeigemoeglichkeit_vorhanden" 2 "reserviert" 3 "Fehler" ;
VAL_ 779 KBI_ARA_in_Anzeige 0 "ARA nicht in Anzeige" 1 "ARA in Anzeige" ;
VAL_ 779 KBI_Einheit_Tacho 0 "km/h" 1 "mph" ;
VAL_ 779 KBI_Konsistenz_ACC 0 "ACC Botschaft konsistent" 1 "ACC Botschaft inkonsistent" ;
VAL_ 779 KBI_Fehler_Anzeige_ACC 0 " iO" 1 "Anzeigefehler ACC" ;
VAL_ 779 KBI_Anzeigefehler_SWA 0 "nicht vorhanden bzw. unterstützt" 1 "Anzeige iO" 2 "Anzeigefehler" 3 "nicht definiert" ;
VAL_ 1719 KBI_Kilometerstand 1048574 "Init" 1048575 "Fehler" ;
VAL_ 1719 KBI_Standzeit_02 131069 "nicht_verfuegbar" 131070 "Init" 131071 "Fehler" ;
VAL_ 1719 KBI_Reserve_Warnung_Sek 0 "Keine_Warnung" 1 "Sekundaere_Reservewarnung" ;
VAL_ 1719 KBI_RDK_Kalibrier_Anf 0 "keine_Kalibrieranforderung" 1 "Kalibrieranforderung" ;
VAL_ 1719 KBI_Inhalt_Tank 126 "Init" 127 "Fehler" ;
VAL_ 1719 KBI_FStatus_Tank 0 "Tankfüllstand i.O." 1 "Tankfüllstand n.i.O" ;
VAL_ 1719 KBI_aktive_Laengsfunktion 0 "Init" 1 "Speedlimiter" 2 "GRA_oder_ACC" 3 "PACCh" 4 "HDC" 5 "frei" 6 "frei" 7 "frei" ;
VAL_ 1719 KBI_Oelwechsel_durchgefuehrt 0 "Oelwechsel_nicht_durchgefuehrt" 1 "Oelwechsel_durchgefuehrt" ;
VAL_ 1719 KBI_QBit_Aussen_Temp_gef 0 "gueltiger_Wert" 1 "Ersatz_Init_oder_Fehlerwert" ;
VAL_ 1719 KBI_Aussen_Temp_gef 253 "nicht verbaut" 254 "Init" 255 "Fehler" ;
VAL_ 1720 KBI_Variante_USA 0 "keine USA-Variante" 1 "USA-Variante" ;
VAL_ 1720 KBI_Variante 0 "Zeiger Kombiinstrument" 1 "Volldisplay Kombiinstrument" ;
VAL_ 1720 KBI_BCmE_aktiv 0 "Anzeige_nicht_aktiv" 1 "Anzeige_aktiv" ;
VAL_ 1720 KBI_Sparhinweis_quittiert 0 "nicht_quittiert" 1 "quittiert" ;
VAL_ 1720 KBI_Tankfuellstand_Prozent 126 "Init" 127 "Fehler" ;
VAL_ 1720 KBI_Nachtanken_erkannt 0 "Geberbetrieb" 1 "Nachtankmodus" ;
VAL_ 1720 KBI_Tankinhalt_hochaufl 16382 "Init" 16383 "Fehler" ;
VAL_ 1720 KBI_Max_Tankinhalt 254 "Init" 255 "Fehler" ;
VAL_ 919 LDW_Gong 0 "kein akustisches Signal" 1 "Gong_1" 2 "Gong_2" 3 "nicht definiert" ;
VAL_ 919 LDW_Frueh_Spaet 0 "frueh_frueh_aktiv" 1 "frueh_spaet_aktiv" 2 "spaet_spaet_aktiv" 3 "Fehler" ;
VAL_ 919 LDW_Texte 0 "keine_Anzeige" 1 "Laneassist_zur_Zeit_n_verfuegbar" 2 "Laneassist_Systemfehler" 3 "Laneassist_zur_Zeit_keine_SSicht" 4 "Laneassist_Fahreruebernahme" 6 "Emergency_Alert_Fahreruebernahme" 7 "Laneassist_FahreruebernahmeLeise" 8 "Laneassist_FahreruebernahmeStumm" 10 "Laneassist_Deaktiviert" ;
VAL_ 919 LDW_Seite_DLCTLC 0 "links" 1 "rechts" ;
VAL_ 919 LDW_Lernmodus 0 "LDW aus" 1 "LDW an/inaktiv" 2 "LDW an/aktiv" 3 "Warnung rechts" 4 "Warnung links" 5 "nicht definiert" 6 "nicht definiert" 7 "nicht definiert" ;
VAL_ 919 LDW_Lernmodus_seitenabhaengig 0 "links_aus__rechts_aus" 1 "HCCA_links_an__rechts_an" 2 "HCCA_links_an__rechts_Warnung" 3 "HCCA_links_Warnung__rechts_an" 4 "nicht_definiert" 5 "links_outlined__rechts_outlined" 6 "links_outlined__rechts_an" 7 "links_outlined__rechts_Warnung" 8 "nicht_definiert" 9 "links_an__rechts_outlined" 10 "links_an__rechts_an" 11 "links_an__rechts_Warnung" 12 "nicht_definiert" 13 "links_Warnung__rechts_outlined" 14 "links_Warnung__rechts_an" 15 "links_Warnung__rechts_Warnung" ;
VAL_ 919 LDW_TLC 31 "Init" ;
VAL_ 919 HC_Uss_Anforderung 0 "Ultraschallsensoren Aus" 1 "Ultraschallsensoren An" ;
VAL_ 919 EA_Warnblinken 0 "aus" 1 "Statisch" 2 "Taster" 3 "Statisch_ohne_WBT" ;
VAL_ 919 LDW_Warnung_links 0 "Warnung links aus" 1 "Warnung links ein" ;
VAL_ 919 LDW_Warnung_rechts 0 "Warnung rechts aus" 1 "Warnung rechts ein" ;
VAL_ 919 LDW_Codierinfo_fuer_VLR 0 "ohne VLR, ohne Akustik" 1 "HMI-Variante VLR" 2 "HMI-Variante VLR + Akustik" 3 "HMI-Variante Akustik" ;
VAL_ 919 LDW_Status_LED_gelb 0 "LDW-Status gelb aus" 1 "LDW-Status gelb aktiv" ;
VAL_ 919 LDW_Status_LED_gruen 0 "LDW-Status gruen aus" 1 "LDW-Status gruen aktiv" ;
VAL_ 159 EPS_DSR_Status 0 "DSR_deaktiviert" 1 "DSR_Anforderung_nicht_ausfuehrbar" 2 "Kommunikation_ESP_gestoert" 3 "EPS_bzgl_DSR_funktionsbereit" 4 "DSR_Anforderung_abgewiesen" 5 "externer_Momenteneingriff_aktiv" 6 "externer_Lenkwinkeleingriff_aktiv" 7 "externer_Momenten_und_Lenkwinkeleingriff_aktiv" ;
VAL_ 159 EPS_Berechneter_LW 4094 "Init" 4095 "Fehler" ;
VAL_ 159 EPS_BLW_QBit 0 "gueltiger_Wert" 1 "Ersatz_Init_oder_Fehlerwert" ;
VAL_ 159 EPS_VZ_BLW 0 "positiv" 1 "negativ" ;
VAL_ 159 EPS_HCA_Status 0 "HCA_in_der_EPS_deaktiviert" 1 "HCA_Anforderung_nicht_ausfuehrbar_HCA_Fehlerstatus_Initialisierung_Ausschaltphase" 2 "Kommunikation_zum_HCA_SG_gestoert" 3 "EPS_bzgl_HCA_fuktionsbereit" 4 "HCA_Anforderung_abgewiesen_aufgrund_Fehler_in_HCA" 5 "HCA_Momenteneingriff_1_aktiv" 6 "reserviert" 7 "HCA_Momenteneingriff_2_aktiv" 8 "HCA_abgewiesen_aufgrund_Momentenpriorisierung" ;
VAL_ 159 EPS_Lenkmoment 1023 "Fehler" ;
VAL_ 159 EPS_Lenkmoment_QBit 0 "gueltiger_Wert" 1 "Ersatz_Init_oder_Fehlerwert" ;
VAL_ 159 EPS_VZ_Lenkmoment 0 "positiv" 1 "negativ" ;
VAL_ 159 EPS_Lenkungstyp 0 "RCEPS_Serie" 1 "RCEPS_Dynamiklenkung" 2 "MQB_DP" 3 "MQB_APA" 4 "MQB_Direktlenkung" 15 "unbekannt" ;
VAL_ 981 BCM1_Kurvenlicht_links_Anf 0 "linkes_Kurvenlicht/Abbiegelicht_durch_BCM1_nicht_angesteuert" 1 "linkes_Kurven/Abbiegelicht_durch_BCM1_angesteuert" ;
VAL_ 981 BCM1_Kurvenlicht_rechts_Anf 0 "rechtes_Kurvenlicht/Abbiegelicht_durch_BCM1_nicht_angesteuert" 1 "rechtes_Kurvenlicht/Abbiegelicht_durch_BCM1_angesteuert" ;
VAL_ 981 BCM1_Standlicht_Anf 0 "Licht_nicht_angefordert" 1 "Licht ist einzuschalten" ;
VAL_ 981 BCM1_Abblendlicht_Anf 0 "Licht_nicht_angefordert" 1 "Licht ist einzuschalten" ;
VAL_ 981 BCM1_Fernlicht_Anf 0 "Licht_nicht_angefordert" 1 "Licht ist einzuschalten" ;
VAL_ 981 BCM1_Nebellicht_Anf 0 "Licht_nicht_angefordert" 1 "Licht ist einzuschalten" ;
VAL_ 981 BCM1_Parklicht_li_Anf 0 "Licht_nicht_angefordert" 1 "Licht ist einzuschalten" ;
VAL_ 981 BCM1_Parklicht_re_Anf 0 "Licht_nicht_angefordert" 1 "Licht ist einzuschalten" ;
VAL_ 981 BCM1_Nebelschluss_Ahg_Anf 0 "Licht_nicht_angefordert" 1 "Licht ist einzuschalten" ;
VAL_ 981 BCM1_Nebelschluss_Fzg_Anf 0 "Licht_nicht_angefordert" 1 "Licht ist einzuschalten" ;
VAL_ 981 BCM1_Schlusslicht_Anf 0 "Licht_nicht_angefordert" 1 "Licht ist einzuschalten" ;
VAL_ 981 BCM_Rueckfahrlicht_Anf 0 "Licht_nicht_angefordert" 1 "Licht_angefordert" ;
VAL_ 981 BCM1_Signaturlicht_Anf 0 "Licht_nicht_angefordert" 1 "Licht_ist_einzuschalten" ;
VAL_ 981 BCM1_Umfeldleuchten_Anf 0 "Licht_nicht_angefordert" 1 "Licht ist einzuschalten" ;
VAL_ 981 BCM1_Tagfahrlicht_Anf 0 "Licht_nicht_angefordert" 1 "Licht ist einzuschalten" ;
VAL_ 981 BCM1_Regenlicht_Anf 0 "Licht_nicht_angefordert" 1 "Licht ist einzuschalten" ;
VAL_ 981 BCM1_Autobahnlicht_Anf 0 "Licht_nicht_angefordert" 1 "Licht ist einzuschalten" ;
VAL_ 981 BCM1_Touristen_Licht_Anf 0 "Licht_nicht_angefordert" 1 "Anforderung von Touristenlicht" ;
VAL_ 981 BCM1_CH_aktiv 0 "Inaktiv" 1 "Aktiv" ;
VAL_ 981 BCM1_LH_aktiv 0 "Inaktiv" 1 "Aktiv" ;
VAL_ 981 BCM1_Gleitende_Leuchtw_Anf 0 "Aus" 1 "Ein" ;
VAL_ 981 BCM1_GLW_Fernlicht_Anf 0 "Aus" 1 "Ein" ;
VAL_ 981 BCM1_Adaptive_Lichtvert_Anf 0 "Aus" 1 "Ein" ;
VAL_ 981 BCM1_CH_LH_aktiv 0 "Comming_Home_Bzw._Leaving_Home_nicht_aktiv" 1 "Comming Home bzw. Leaving Home aktiv" ;
VAL_ 981 BCM1_Allwetterlicht_Anf 0 "Licht_nicht_angefordert" 1 "Licht_ist_einzuschalten" ;
VAL_ 1624 LV_Standlicht_Anzeige 0 "nicht aktiv" 1 "aktiv" ;
VAL_ 1624 LV_Abblendlicht_Anzeige 0 "inaktiv" 1 "aktiv" ;
VAL_ 1624 LV_Fernlicht_Anzeige 0 "nicht aktiv" 1 "aktiv" ;
VAL_ 1624 LV_Nebellicht_Anzeige 0 "nicht aktiv" 1 "aktiv" ;
VAL_ 1624 LV_Nebelschlusslicht_Anzeige 0 "nicht aktiv" 1 "aktiv" ;
VAL_ 1624 LV_Tagfahrlicht_Anzeige 0 "nicht aktiv" 1 "aktiv" ;
VAL_ 1624 LV_AFL_aktiv_Anzeige 0 "nicht aktiv" 1 "aktiv" ;
VAL_ 1624 LV_AFL_defekt 0 "OK" 1 "defekt" ;
VAL_ 1624 LV_Blinker_li_def 0 "OK" 1 "defekt" ;
VAL_ 1624 LV_Standlicht_li_def 0 "OK" 1 "defekt" ;
VAL_ 1624 LV_Abblendlicht_li_def 0 "OK" 1 "defekt" ;
VAL_ 1624 LV_Fernlicht_li_def 0 "OK" 1 "defekt" ;
VAL_ 1624 LV_Nebellicht_li_def 0 "OK" 1 "defekt" ;
VAL_ 1624 LV_Blk_li_Seite_def 0 "OK" 1 "defekt" ;
VAL_ 1624 LV_Tagfahrlicht_li_def 0 "OK" 1 "defekt" ;
VAL_ 1624 LV_FLA_aktiv_Anzeige 0 "aus" 1 "ein" ;
VAL_ 1624 LV_FLA_defekt 0 "i.O." 1 "FLA defekt" ;
VAL_ 1624 LV_FLA_Sensor_blockiert 0 "i.O." 1 "FLA-Sensor blockiert" ;
VAL_ 1624 LV_Blinker_re_def 0 "OK" 1 "defekt" ;
VAL_ 1624 LV_Standlicht_re_def 0 "OK" 1 "defekt" ;
VAL_ 1624 LV_Abblendlicht_re_def 0 "OK" 1 "defekt" ;
VAL_ 1624 LV_Fernlicht_re_def 0 "OK" 1 "defekt" ;
VAL_ 1624 LV_Nebellicht_re_def 0 "OK" 1 "defekt" ;
VAL_ 1624 LV_Blk_re_Seite_def 0 "OK" 1 "defekt" ;
VAL_ 1624 LV_Tagfahrlicht_re_def 0 "OK" 1 "defekt" ;
VAL_ 1624 LV_Aussenlicht_def 0 "OK" 1 "defekt" ;
VAL_ 1624 LV_Abblendlicht_TFL_li_def 0 "OK" 1 "defekt" ;
VAL_ 1624 LV_Nebellicht_TFL_li_def 0 "OK" 1 "defekt" ;
VAL_ 1624 LV_Standlicht_TFL_li_def 0 "OK" 1 "defekt" ;
VAL_ 1624 LV_Abblend_Fernlicht_li_def 0 "OK" 1 "defekt" ;
VAL_ 1624 LV_Abblendlicht_TFL_re_def 0 "OK" 1 "defekt" ;
VAL_ 1624 LV_Nebellicht_TFL_re_def 0 "OK" 1 "defekt" ;
VAL_ 1624 LV_Standlicht_TFL_re_def 0 "OK" 1 "defekt" ;
VAL_ 1624 LV_Abblend_Fernlicht_re_def 0 "OK" 1 "defekt" ;
VAL_ 1624 LV_Abbiegelicht_li_def 0 "OK" 1 "defekt" ;
VAL_ 1624 LV_Abbiegelicht_re_def 0 "OK" 1 "defekt" ;
VAL_ 1624 BCM1_Linksverkehr 0 "Rechtsverkehr" 1 "Linksverkehr" ;
VAL_ 1624 BCM1_Licht_Dunkelheit_aktiv 1 "Licht wegen Dunkelheit aktiv, nicht bei Autobahnlicht, Tagfahrlicht oder Regenlicht" ;
VAL_ 1624 LV_LED_Scheinwerfer_li_def 0 "OK" 1 "defekt" ;
VAL_ 1624 LV_LED_Scheinwerfer_re_def 0 "OK" 1 "defekt" ;
VAL_ 1624 LV_Blinker_VL_aktiv 0 "inaktiv" 1 "aktiv" ;
VAL_ 1624 LV_Blinker_VR_aktiv 0 "inaktiv" 1 "aktiv" ;
